BU_:  Airbag BAP_Tester ICAS1_Gateway ICAS1_KommunikationsServer LE1 LE2 Motor_BEV Schaltbetaetigung

BO_ 333 ACC_18: 32 ICAS1_Gateway
 SG_ ACC_18_CRC  : 0|8@1+ (1.000000,0.000000) [0.000000|255.000000] "" Motor_BEV
 SG_ ACC_18_BZ  : 8|4@1+ (1.000000,0.000000) [0.000000|15.000000] "" Motor_BEV
 SG_ ACC_limitierte_Anfahrdyn  : 12|1@1+ (1.000000,0.000000) [0.000000|1.000000] "" Motor_BEV
 SG_ ACC_nachtr_Stopp_Anf  : 13|1@1+ (1.000000,0.000000) [0.000000|1.000000] "" Vector__XXX
 SG_ ACC_DynErhoehung  : 14|1@1+ (1.000000,0.000000) [0.000000|1.000000] "" Motor_BEV
 SG_ ACC_Freilaufstrategie_TSK  : 15|1@1+ (1.000000,0.000000) [0.000000|1.000000] "" Motor_BEV
 SG_ ACC_zul_Regelabw_unten  : 16|6@1+ (0.024000,0.000000) [0.000000|1.512000] "Unit_MeterPerSeconSquar" Motor_BEV
 SG_ ACC_StartStopp_Info  : 22|2@1+ (1.000000,0.000000) [0.000000|3.000000] "" Vector__XXX
 SG_ ACC_Sollbeschleunigung_02  : 24|11@1+ (0.005000,-7.220000) [-7.220000|3.005000] "Unit_MeterPerSeconSquar" Motor_BEV
 SG_ ACC_zul_Regelabw_oben  : 35|5@1+ (0.062500,0.000000) [0.000000|1.937500] "Unit_MeterPerSeconSquar" Motor_BEV
 SG_ ACC_neg_Sollbeschl_Grad_02  : 40|8@1+ (0.050000,0.000000) [0.000000|12.750000] "Unit_MeterPerCubicSecon" Motor_BEV
 SG_ ACC_pos_Sollbeschl_Grad_02  : 48|8@1+ (0.050000,0.000000) [0.000000|12.750000] "Unit_MeterPerCubicSecon" Motor_BEV
 SG_ ACC_Anfahren  : 56|1@1+ (1.000000,0.000000) [0.000000|1.000000] "" Motor_BEV
 SG_ ACC_Anhalten  : 57|1@1+ (1.000000,0.000000) [0.000000|1.000000] "" Motor_BEV
 SG_ ACC_Typ  : 58|2@1+ (1.000000,0.000000) [0.000000|3.000000] "" Motor_BEV
 SG_ ACC_Status_ACC  : 60|3@1+ (1.000000,0.000000) [0.000000|7.000000] "" Motor_BEV
 SG_ ACC_Minimale_Bremsung  : 63|1@1+ (1.000000,0.000000) [0.000000|1.000000] "" Motor_BEV
 SG_ ACC_Anhalteweg  : 64|11@1+ (0.010000,0.000000) [0.000000|20.450000] "Unit_Meter" Vector__XXX
 SG_ ACC_Boost  : 75|1@1+ (1.000000,0.000000) [0.000000|1.000000] "" Vector__XXX
 SG_ ACC_Freilauf_Anf  : 76|1@1+ (1.000000,0.000000) [0.000000|1.000000] "" Vector__XXX
 SG_ ACC_Anforderung_HMS  : 77|3@1+ (1.000000,0.000000) [0.000000|7.000000] "" Vector__XXX
 SG_ ACC_Folgebeschl  : 80|8@1+ (0.030000,-4.600000) [-4.600000|2.990000] "Unit_MeterPerSeconSquar" Motor_BEV
 SG_ ACC_Freilauf_Info  : 88|2@1+ (1.000000,0.000000) [0.000000|3.000000] "" Motor_BEV
 SG_ ACC_Tempolimitassistent_Ein  : 90|1@1+ (1.000000,0.000000) [0.000000|1.000000] "" Vector__XXX
 SG_ ACC_FoD_Status  : 91|2@1+ (1.000000,0.000000) [0.000000|3.000000] "" Motor_BEV
 SG_ vESC_Verz_Anf  : 232|4@1+ (0.500000,0.000000) [0.000000|3.500000] "Unit_MeterPerSeconSquar" Vector__XXX
 SG_ RDR_v_ueber_Grund  : 236|12@1+ (0.100000,0.000000) [0.000000|409.000000] "Unit_KiloMeterPerHour" Vector__XXX
 SG_ RDR_v_ueber_Grund_Genauigkeit  : 248|6@1+ (0.100000,0.000000) [0.000000|6.000000] "Unit_KiloMeterPerHour" Vector__XXX
 SG_ RDR_v_ueber_Grund_Fahrtrichtung  : 254|2@1+ (1.000000,0.000000) [0.000000|3.000000] "" Vector__XXX

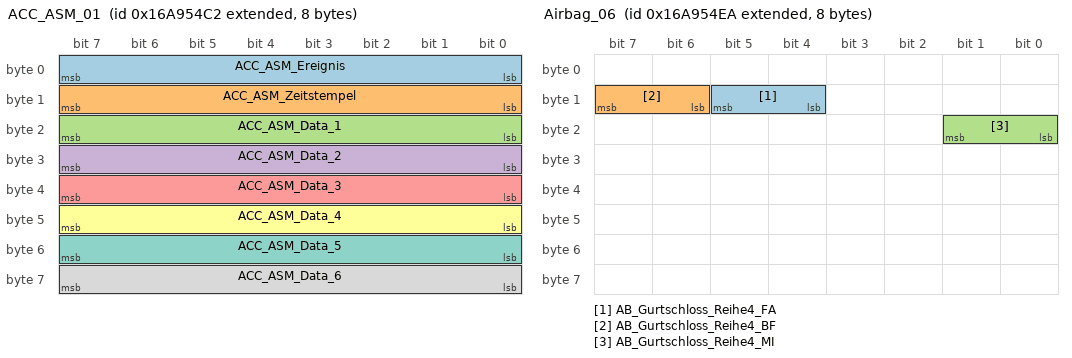
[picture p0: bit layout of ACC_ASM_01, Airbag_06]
BO_ 2527679682 ACC_ASM_01: 8 ICAS1_Gateway
 SG_ ACC_ASM_Ereignis  : 0|8@1+ (1.000000,0.000000) [1.000000|254.000000] "" Airbag
 SG_ ACC_ASM_Zeitstempel  : 8|8@1+ (0.080000,0.000000) [0.000000|20.320000] "Unit_Secon" Airbag
 SG_ ACC_ASM_Data_1  : 16|8@1+ (1.000000,0.000000) [0.000000|255.000000] "" Airbag
 SG_ ACC_ASM_Data_2  : 24|8@1+ (1.000000,0.000000) [0.000000|255.000000] "" Airbag
 SG_ ACC_ASM_Data_3  : 32|8@1+ (1.000000,0.000000) [0.000000|255.000000] "" Airbag
 SG_ ACC_ASM_Data_4  : 40|8@1+ (1.000000,0.000000) [0.000000|255.000000] "" Airbag
 SG_ ACC_ASM_Data_5  : 48|8@1+ (1.000000,0.000000) [0.000000|255.000000] "" Airbag
 SG_ ACC_ASM_Data_6  : 56|8@1+ (1.000000,0.000000) [0.000000|255.000000] "" Airbag

BO_ 64 Airbag_01: 8 Airbag
 SG_ Airbag_01_CRC  : 0|8@1+ (1.000000,0.000000) [0.000000|255.000000] "" ICAS1_Gateway LE1 LE2 Motor_BEV
 SG_ Airbag_01_BZ  : 8|4@1+ (1.000000,0.000000) [0.000000|15.000000] "" ICAS1_Gateway LE1 LE2 Motor_BEV
 SG_ AB_RGS_Anst  : 12|4@1+ (1.000000,0.000000) [0.000000|15.000000] "" ICAS1_Gateway ICAS1_KommunikationsServer
 SG_ AB_Front_Crash  : 16|1@1+ (1.000000,0.000000) [0.000000|1.000000] "" ICAS1_Gateway
 SG_ AB_Heck_Crash  : 17|1@1+ (1.000000,0.000000) [0.000000|1.000000] "" ICAS1_Gateway
 SG_ AB_SF_Crash  : 18|1@1+ (1.000000,0.000000) [0.000000|1.000000] "" ICAS1_Gateway
 SG_ AB_SB_Crash  : 19|1@1+ (1.000000,0.000000) [0.000000|1.000000] "" ICAS1_Gateway
 SG_ AB_Rollover_Crash  : 20|1@1+ (1.000000,0.000000) [0.000000|1.000000] "" ICAS1_Gateway
 SG_ AB_Crash_Int  : 21|3@1+ (1.000000,0.000000) [0.000000|7.000000] "" ICAS1_Gateway ICAS1_KommunikationsServer Motor_BEV
 SG_ AB_Lampe  : 24|1@1+ (1.000000,0.000000) [0.000000|1.000000] "" ICAS1_Gateway ICAS1_KommunikationsServer
 SG_ AB_Deaktiviert  : 25|1@1+ (1.000000,0.000000) [0.000000|1.000000] "" ICAS1_Gateway
 SG_ AB_VB_deaktiviert  : 26|1@1+ (1.000000,0.000000) [0.000000|1.000000] "" ICAS1_Gateway
 SG_ AB_Systemfehler  : 27|1@1+ (1.000000,0.000000) [0.000000|1.000000] "" ICAS1_Gateway ICAS1_KommunikationsServer
 SG_ AB_Diagnose  : 28|1@1+ (1.000000,0.000000) [0.000000|1.000000] "" ICAS1_Gateway
 SG_ AB_Stellgliedtest  : 29|1@1+ (1.000000,0.000000) [0.000000|1.000000] "" ICAS1_Gateway
 SG_ AB_Erh_Auf_VB  : 30|2@1+ (1.000000,0.000000) [0.000000|3.000000] "" ICAS1_Gateway
 SG_ AB_Gurtwarn_VF  : 32|1@1+ (1.000000,0.000000) [0.000000|1.000000] "" ICAS1_Gateway ICAS1_KommunikationsServer
 SG_ AB_Gurtwarn_VB  : 33|1@1+ (1.000000,0.000000) [0.000000|1.000000] "" ICAS1_Gateway ICAS1_KommunikationsServer
 SG_ AB_Anzeige_Fussg  : 34|2@1+ (1.000000,0.000000) [0.000000|3.000000] "" ICAS1_Gateway
 SG_ AB_Texte_AKS  : 36|2@1+ (1.000000,0.000000) [0.000000|3.000000] "" ICAS1_Gateway
 SG_ AB_PAO_Leuchte_Anf  : 38|1@1+ (1.000000,0.000000) [0.000000|1.000000] "" ICAS1_Gateway
 SG_ AB_MKB_gueltig  : 39|1@1+ (1.000000,0.000000) [0.000000|1.000000] "" ICAS1_Gateway
 SG_ AB_MKB_Anforderung  : 40|1@1+ (1.000000,0.000000) [0.000000|1.000000] "" ICAS1_Gateway
 SG_ AB_Versorgungsspannung  : 41|1@1+ (1.000000,0.000000) [0.000000|1.000000] "" ICAS1_Gateway
 SG_ AB_Deaktivierung_HV  : 42|3@1+ (1.000000,0.000000) [0.000000|7.000000] "" ICAS1_Gateway ICAS1_KommunikationsServer LE1 LE2 Motor_BEV
 SG_ AB_EDR_Trigger  : 45|2@1+ (1.000000,0.000000) [0.000000|3.000000] "" ICAS1_Gateway
 SG_ AB_Belegung_VF  : 47|2@1+ (1.000000,0.000000) [0.000000|3.000000] "" ICAS1_Gateway
 SG_ AB_Gurtschloss_FA_ext  : 49|3@1+ (1.000000,0.000000) [0.000000|7.000000] "" ICAS1_Gateway
 SG_ AB_Belegung_VF_ext  : 52|3@1+ (1.000000,0.000000) [0.000000|7.000000] "" ICAS1_Gateway
 SG_ ASM_Masterzeit  : 56|8@1+ (0.080000,0.000000) [0.000000|20.320000] "Unit_Secon" ICAS1_Gateway

BO_ 1312 Airbag_02: 8 Airbag
 SG_ Airbag_02_CRC  : 0|8@1+ (1.000000,0.000000) [0.000000|255.000000] "" ICAS1_Gateway Motor_BEV
 SG_ Airbag_02_BZ  : 8|4@1+ (1.000000,0.000000) [0.000000|15.000000] "" ICAS1_Gateway Motor_BEV
 SG_ LoGeWa_Event_Kombiwarnung  : 12|4@1+ (1.000000,0.000000) [0.000000|15.000000] "" ICAS1_Gateway
 SG_ AB_Anforderung_eCall  : 16|1@1+ (1.000000,0.000000) [0.000000|1.000000] "" ICAS1_Gateway
 SG_ AB_Anprall_Seite_Beifahrer  : 17|1@1+ (1.000000,0.000000) [0.000000|1.000000] "" ICAS1_Gateway ICAS1_KommunikationsServer
 SG_ AB_Anprall_Rollover  : 18|1@1+ (1.000000,0.000000) [0.000000|1.000000] "" ICAS1_Gateway ICAS1_KommunikationsServer
 SG_ AB_Anprall_FGS  : 19|1@1+ (1.000000,0.000000) [0.000000|1.000000] "" ICAS1_Gateway ICAS1_KommunikationsServer
 SG_ AB_Anprall_Front_Beifahrer  : 20|1@1+ (1.000000,0.000000) [0.000000|1.000000] "" ICAS1_Gateway ICAS1_KommunikationsServer
 SG_ AB_Anprall_Front_Fahrer  : 21|1@1+ (1.000000,0.000000) [0.000000|1.000000] "" ICAS1_Gateway ICAS1_KommunikationsServer
 SG_ AB_Anprall_Heck_Beifahrer  : 22|1@1+ (1.000000,0.000000) [0.000000|1.000000] "" ICAS1_Gateway ICAS1_KommunikationsServer
 SG_ AB_Anprall_Heck_Fahrer  : 23|1@1+ (1.000000,0.000000) [0.000000|1.000000] "" ICAS1_Gateway ICAS1_KommunikationsServer
 SG_ AB_Wickelklappung_Reihe2_MI  : 24|2@1+ (1.000000,0.000000) [0.000000|3.000000] "" ICAS1_Gateway
 SG_ AB_Belegung_VB  : 26|2@1+ (1.000000,0.000000) [0.000000|3.000000] "" ICAS1_Gateway
 SG_ AB_Abschaltanf_SIH_BF  : 28|1@1+ (1.000000,0.000000) [0.000000|1.000000] "" ICAS1_Gateway
 SG_ AB_Anprall_Seite_Fahrer  : 29|1@1+ (1.000000,0.000000) [0.000000|1.000000] "" ICAS1_Gateway ICAS1_KommunikationsServer
 SG_ SC_PAO_Schriftzug_Anf  : 30|2@1+ (1.000000,0.000000) [0.000000|3.000000] "" ICAS1_Gateway
 SG_ SC_PAO_ON_Anf  : 32|2@1+ (1.000000,0.000000) [0.000000|3.000000] "" ICAS1_Gateway
 SG_ SC_PAO_OFF_Anf  : 34|2@1+ (1.000000,0.000000) [0.000000|3.000000] "" ICAS1_Gateway
 SG_ AB_Crashschwere  : 36|3@1+ (1.000000,0.000000) [0.000000|7.000000] "" ICAS1_Gateway ICAS1_KommunikationsServer
 SG_ AB_Anforderung_USM  : 39|1@1+ (1.000000,0.000000) [0.000000|1.000000] "" ICAS1_Gateway
 SG_ AB_Gurtschloss_FA  : 40|2@1+ (1.000000,0.000000) [0.000000|3.000000] "" ICAS1_Gateway ICAS1_KommunikationsServer Motor_BEV
 SG_ AB_Gurtschloss_BF  : 42|2@1+ (1.000000,0.000000) [0.000000|3.000000] "" ICAS1_Gateway ICAS1_KommunikationsServer
 SG_ AB_Gurtschloss_Reihe2_FA  : 44|2@1+ (1.000000,0.000000) [0.000000|3.000000] "" ICAS1_Gateway ICAS1_KommunikationsServer
 SG_ AB_Gurtschloss_Reihe2_MI  : 46|2@1+ (1.000000,0.000000) [0.000000|3.000000] "" ICAS1_Gateway ICAS1_KommunikationsServer
 SG_ AB_Gurtschloss_Reihe2_BF  : 48|2@1+ (1.000000,0.000000) [0.000000|3.000000] "" ICAS1_Gateway ICAS1_KommunikationsServer
 SG_ AB_Gurtschloss_Reihe3_FA  : 50|2@1+ (1.000000,0.000000) [0.000000|3.000000] "" ICAS1_Gateway ICAS1_KommunikationsServer
 SG_ AB_Gurtschloss_Reihe3_MI  : 52|2@1+ (1.000000,0.000000) [0.000000|3.000000] "" ICAS1_Gateway ICAS1_KommunikationsServer
 SG_ AB_Gurtschloss_Reihe3_BF  : 54|2@1+ (1.000000,0.000000) [0.000000|3.000000] "" ICAS1_Gateway ICAS1_KommunikationsServer
 SG_ AB_Sitzpos_Sens_FA  : 56|2@1+ (1.000000,0.000000) [0.000000|3.000000] "" ICAS1_Gateway
 SG_ AB_Sitzpos_Sens_BF  : 58|2@1+ (1.000000,0.000000) [0.000000|3.000000] "" ICAS1_Gateway
 SG_ AB_Wickelklappung_Reihe2_BF  : 60|2@1+ (1.000000,0.000000) [0.000000|3.000000] "" ICAS1_Gateway
 SG_ AB_Wickelklappung_Reihe2_FA  : 62|2@1+ (1.000000,0.000000) [0.000000|3.000000] "" ICAS1_Gateway

BO_ 65 Airbag_03: 8 Airbag
 SG_ Airbag_03_CRC  : 0|8@1+ (1.000000,0.000000) [0.000000|255.000000] "" ICAS1_Gateway
 SG_ Airbag_03_BZ  : 8|4@1+ (1.000000,0.000000) [0.000000|15.000000] "" ICAS1_Gateway
 SG_ AB_MKB_Safing  : 63|1@1+ (1.000000,0.000000) [0.000000|1.000000] "" ICAS1_Gateway

BO_ 1349 Airbag_04: 8 Airbag
 SG_ AB_Gurtwarn_Reihe4_FA  : 14|2@1+ (1.000000,0.000000) [0.000000|3.000000] "" ICAS1_Gateway ICAS1_KommunikationsServer
 SG_ AB_Gurtwarn_Reihe4_BF  : 16|2@1+ (1.000000,0.000000) [0.000000|3.000000] "" ICAS1_Gateway ICAS1_KommunikationsServer
 SG_ AB_Gurtwarn_Reihe4_MI  : 18|2@1+ (1.000000,0.000000) [0.000000|3.000000] "" ICAS1_Gateway ICAS1_KommunikationsServer
 SG_ AB_Gurtwarn_Reihe2_FA  : 20|2@1+ (1.000000,0.000000) [0.000000|3.000000] "" ICAS1_Gateway ICAS1_KommunikationsServer
 SG_ AB_Gurtwarn_Reihe2_BF  : 22|2@1+ (1.000000,0.000000) [0.000000|3.000000] "" ICAS1_Gateway ICAS1_KommunikationsServer
 SG_ AbstWarn_MV_FAS_Fkt_Status  : 24|2@1+ (1.000000,0.000000) [0.000000|3.000000] "" ICAS1_Gateway
 SG_ WarnBrems_Charisma_Status  : 26|2@1+ (1.000000,0.000000) [0.000000|3.000000] "" ICAS1_Gateway
 SG_ WarnBrems_Charisma_FahrPr  : 28|4@1+ (1.000000,0.000000) [0.000000|15.000000] "" ICAS1_Gateway
 SG_ AB_Gurtwarn_Reihe2_MI  : 32|2@1+ (1.000000,0.000000) [0.000000|3.000000] "" ICAS1_Gateway ICAS1_KommunikationsServer
 SG_ AB_Gurtwarn_Reihe3_FA  : 34|2@1+ (1.000000,0.000000) [0.000000|3.000000] "" ICAS1_Gateway ICAS1_KommunikationsServer
 SG_ AB_Gurtwarn_Reihe3_MI  : 36|2@1+ (1.000000,0.000000) [0.000000|3.000000] "" ICAS1_Gateway ICAS1_KommunikationsServer
 SG_ AB_Gurtwarn_Reihe3_BF  : 38|2@1+ (1.000000,0.000000) [0.000000|3.000000] "" ICAS1_Gateway ICAS1_KommunikationsServer
 SG_ LGI_FAS_Fkt_Status  : 40|2@1+ (1.000000,0.000000) [0.000000|3.000000] "" ICAS1_Gateway
 SG_ PreCrash_FAS_Fkt_Status  : 42|3@1+ (1.000000,0.000000) [0.000000|7.000000] "" ICAS1_Gateway
 SG_ AB_SBR_hinten_verbau  : 48|2@1+ (1.000000,0.000000) [0.000000|3.000000] "" ICAS1_Gateway ICAS1_KommunikationsServer
 SG_ AWV_Einstellung_System_ASG  : 51|1@1+ (1.000000,0.000000) [0.000000|1.000000] "" ICAS1_Gateway
 SG_ AWV_Einstellung_Warnung_ASG  : 52|3@1+ (1.000000,0.000000) [0.000000|7.000000] "" ICAS1_Gateway
 SG_ SC_PreSense_Modus_Warnung_NV  : 55|3@1+ (1.000000,0.000000) [0.000000|7.000000] "" ICAS1_Gateway
 SG_ SC_PreSense_Modus_Warnung_MV  : 58|3@1+ (1.000000,0.000000) [0.000000|7.000000] "" ICAS1_Gateway
 SG_ SC_PreSense_Modus_System_MV  : 61|1@1+ (1.000000,0.000000) [0.000000|1.000000] "" ICAS1_Gateway
 SG_ SC_PreSense_Modus_System_NV  : 62|1@1+ (1.000000,0.000000) [0.000000|1.000000] "" ICAS1_Gateway
 SG_ SC_PreSense_Modus_System_KAS  : 63|1@1+ (1.000000,0.000000) [0.000000|1.000000] "" ICAS1_Gateway

BO_ 2527679722 Airbag_06: 8 Airbag
 SG_ AB_Gurtschloss_Reihe4_FA  : 12|2@1+ (1.000000,0.000000) [0.000000|3.000000] "" ICAS1_Gateway ICAS1_KommunikationsServer
 SG_ AB_Gurtschloss_Reihe4_BF  : 14|2@1+ (1.000000,0.000000) [0.000000|3.000000] "" ICAS1_Gateway ICAS1_KommunikationsServer
 SG_ AB_Gurtschloss_Reihe4_MI  : 16|2@1+ (1.000000,0.000000) [0.000000|3.000000] "" ICAS1_Gateway ICAS1_KommunikationsServer

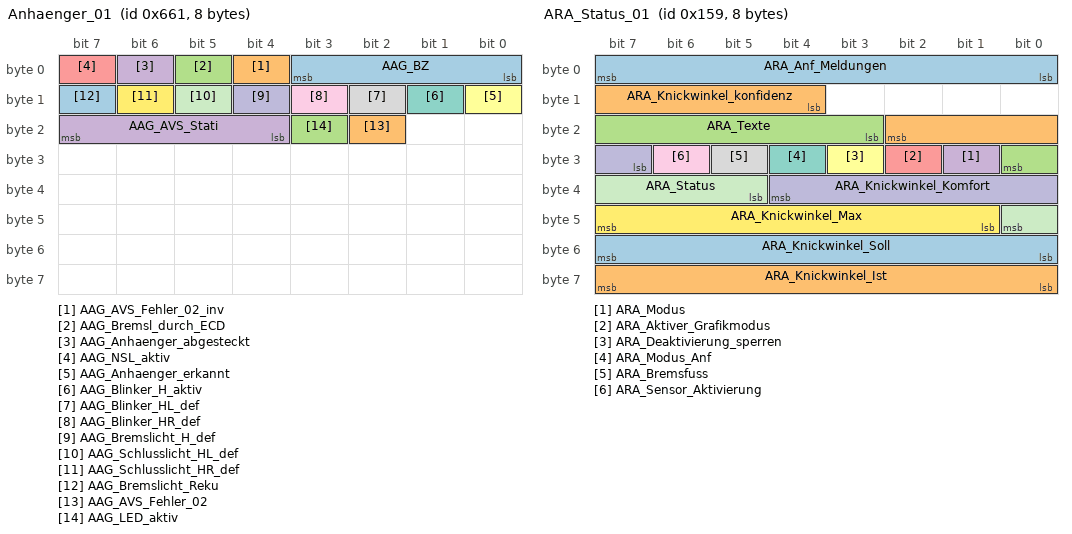
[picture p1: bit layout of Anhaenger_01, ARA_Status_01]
BO_ 1633 Anhaenger_01: 8 ICAS1_Gateway
 SG_ AAG_BZ  : 0|4@1+ (1.000000,0.000000) [0.000000|15.000000] "" Vector__XXX
 SG_ AAG_AVS_Fehler_02_inv  : 4|1@1+ (1.000000,0.000000) [0.000000|1.000000] "" Vector__XXX
 SG_ AAG_Bremsl_durch_ECD  : 5|1@1+ (1.000000,0.000000) [0.000000|1.000000] "" Motor_BEV
 SG_ AAG_Anhaenger_abgesteckt  : 6|1@1+ (1.000000,0.000000) [0.000000|1.000000] "" Motor_BEV
 SG_ AAG_NSL_aktiv  : 7|1@1+ (1.000000,0.000000) [0.000000|1.000000] "" Vector__XXX
 SG_ AAG_Anhaenger_erkannt  : 8|1@1+ (1.000000,0.000000) [0.000000|1.000000] "" Motor_BEV
 SG_ AAG_Blinker_H_aktiv  : 9|1@1+ (1.000000,0.000000) [0.000000|1.000000] "" Vector__XXX
 SG_ AAG_Blinker_HL_def  : 10|1@1+ (1.000000,0.000000) [0.000000|1.000000] "" Vector__XXX
 SG_ AAG_Blinker_HR_def  : 11|1@1+ (1.000000,0.000000) [0.000000|1.000000] "" Vector__XXX
 SG_ AAG_Bremslicht_H_def  : 12|1@1+ (1.000000,0.000000) [0.000000|1.000000] "" Motor_BEV
 SG_ AAG_Schlusslicht_HL_def  : 13|1@1+ (1.000000,0.000000) [0.000000|1.000000] "" Vector__XXX
 SG_ AAG_Schlusslicht_HR_def  : 14|1@1+ (1.000000,0.000000) [0.000000|1.000000] "" Vector__XXX
 SG_ AAG_Bremslicht_Reku  : 15|1@1+ (1.000000,0.000000) [0.000000|1.000000] "" Vector__XXX
 SG_ AAG_AVS_Fehler_02  : 18|1@1+ (1.000000,0.000000) [0.000000|1.000000] "" Vector__XXX
 SG_ AAG_LED_aktiv  : 19|1@1+ (1.000000,0.000000) [0.000000|1.000000] "" Vector__XXX
 SG_ AAG_AVS_Stati  : 20|4@1+ (1.000000,0.000000) [0.000000|15.000000] "" Vector__XXX

BO_ 345 ARA_Status_01: 8 ICAS1_Gateway
 SG_ ARA_Anf_Meldungen  : 0|8@1+ (1.000000,0.000000) [0.000000|255.000000] "" Vector__XXX
 SG_ ARA_Knickwinkel_konfidenz  : 12|7@1+ (1.000000,0.000000) [0.000000|120.000000] "Unit_DegreOfArc" Vector__XXX
 SG_ ARA_Texte  : 19|6@1+ (1.000000,0.000000) [0.000000|63.000000] "" Vector__XXX
 SG_ ARA_Modus  : 25|1@1+ (1.000000,0.000000) [0.000000|1.000000] "" Vector__XXX
 SG_ ARA_Aktiver_Grafikmodus  : 26|1@1+ (1.000000,0.000000) [0.000000|1.000000] "" Vector__XXX
 SG_ ARA_Deaktivierung_sperren  : 27|1@1+ (1.000000,0.000000) [0.000000|1.000000] "" Vector__XXX
 SG_ ARA_Modus_Anf  : 28|1@1+ (1.000000,0.000000) [0.000000|1.000000] "" Vector__XXX
 SG_ ARA_Bremsfuss  : 29|1@1+ (1.000000,0.000000) [0.000000|1.000000] "" Vector__XXX
 SG_ ARA_Sensor_Aktivierung  : 30|1@1+ (1.000000,0.000000) [0.000000|1.000000] "" Vector__XXX
 SG_ ARA_Knickwinkel_Komfort  : 31|6@1+ (1.000000,0.000000) [0.000000|60.000000] "Unit_DegreOfArc" Vector__XXX
 SG_ ARA_Status  : 37|4@1+ (1.000000,0.000000) [0.000000|15.000000] "" Motor_BEV
 SG_ ARA_Knickwinkel_Max  : 41|7@1+ (1.000000,0.000000) [0.000000|120.000000] "Unit_DegreOfArc" Vector__XXX
 SG_ ARA_Knickwinkel_Soll  : 48|8@1+ (1.000000,-125.000000) [-125.000000|126.000000] "Unit_DegreOfArc" Vector__XXX
 SG_ ARA_Knickwinkel_Ist  : 56|8@1+ (1.000000,-125.000000) [-125.000000|126.000000] "Unit_DegreOfArc" Vector__XXX

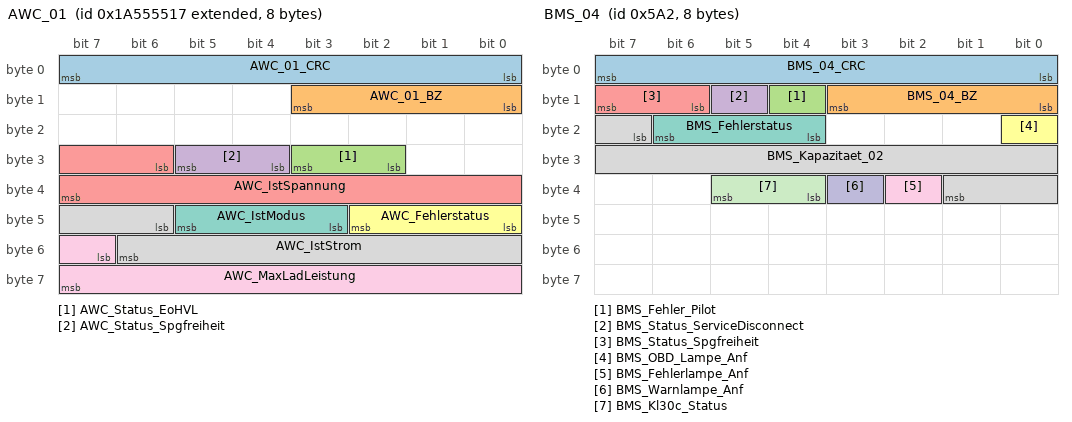
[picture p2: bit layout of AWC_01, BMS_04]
BO_ 2589283607 AWC_01: 8 ICAS1_Gateway
 SG_ AWC_01_CRC  : 0|8@1+ (1.000000,0.000000) [0.000000|255.000000] "" Vector__XXX
 SG_ AWC_01_BZ  : 8|4@1+ (1.000000,0.000000) [0.000000|15.000000] "" Vector__XXX
 SG_ AWC_Status_EoHVL  : 26|2@1+ (1.000000,0.000000) [0.000000|3.000000] "" Motor_BEV
 SG_ AWC_Status_Spgfreiheit  : 28|2@1+ (1.000000,0.000000) [0.000000|3.000000] "" Vector__XXX
 SG_ AWC_IstSpannung  : 30|10@1+ (1.000000,0.000000) [0.000000|1021.000000] "Unit_Volt" Vector__XXX
 SG_ AWC_Fehlerstatus  : 40|3@1+ (1.000000,0.000000) [0.000000|7.000000] "" Vector__XXX
 SG_ AWC_IstModus  : 43|3@1+ (1.000000,0.000000) [0.000000|7.000000] "" Vector__XXX
 SG_ AWC_IstStrom  : 46|9@1+ (0.100000,0.000000) [0.000000|50.900000] "Unit_Amper" Vector__XXX
 SG_ AWC_MaxLadLeistung  : 55|9@1+ (25.000000,0.000000) [0.000000|12725.000000] "Unit_Watt" Vector__XXX

BO_ 219 AWV_03: 48 ICAS1_Gateway
 SG_ AWV_03_CRC  : 0|8@1+ (1.000000,0.000000) [0.000000|255.000000] "" Airbag
 SG_ AWV_03_BZ  : 8|4@1+ (1.000000,0.000000) [0.000000|15.000000] "" Airbag
 SG_ PCF_Freigabe  : 12|1@1+ (1.000000,0.000000) [0.000000|1.000000] "" Airbag
 SG_ SDF_PSF_Objektstatus  : 13|3@1+ (1.000000,0.000000) [0.000000|7.000000] "" Airbag
 SG_ SDF_PSF_CU_Status  : 16|1@1+ (1.000000,0.000000) [0.000000|1.000000] "" Airbag
 SG_ SDF_PSF_CW  : 17|7@1+ (1.000000,0.000000) [0.000000|100.000000] "" Airbag
 SG_ SDF_PSF_Fahrer_aktiv  : 24|1@1+ (1.000000,0.000000) [0.000000|1.000000] "" Airbag
 SG_ SDF_PSF_Guete  : 25|2@1+ (1.000000,0.000000) [0.000000|3.000000] "" Airbag
 SG_ SDF_PSF_Kollisionsueberdeckung  : 27|5@1+ (0.100000,0.000000) [0.100000|2.800000] "Unit_Meter" Airbag
 SG_ SDF_PSF_Time_To_Collision  : 32|8@1+ (0.010000,0.000000) [0.000000|2.500000] "Unit_Secon" Vector__XXX
 SG_ SDF_PSF_v_rel  : 40|8@1+ (0.400000,0.000000) [0.400000|101.200000] "Unit_MeterPerSecon" Airbag
 SG_ AWV_Eingriff_Sendeart  : 64|1@1+ (1.000000,0.000000) [0.000000|1.000000] "" Airbag
 SG_ AWV_Verz_Freigabe  : 65|1@1+ (1.000000,0.000000) [0.000000|1.000000] "" Airbag
 SG_ AWV_Verz_Anf  : 66|10@1+ (0.024000,-20.016000) [-20.016000|4.512000] "Unit_MeterPerSeconSquar" Airbag
 SG_ AWV_Anf_Prefill  : 76|1@1+ (1.000000,0.000000) [0.000000|1.000000] "" Airbag
 SG_ AWV_Ruckprofil  : 77|3@1+ (1.000000,0.000000) [0.000000|7.000000] "" Vector__XXX
 SG_ AWV_Time_to_collision  : 80|8@1+ (0.010000,0.000000) [0.000000|2.500000] "Unit_Secon" Airbag
 SG_ AWV_HBA_Param  : 88|2@1+ (1.000000,0.000000) [0.000000|3.000000] "" Vector__XXX
 SG_ AWV_Verz_Anf_ASIL  : 90|3@1+ (1.000000,0.000000) [0.000000|7.000000] "" Vector__XXX
 SG_ AWV_Time_to_brake  : 93|7@1+ (10.000000,0.000000) [0.000000|1240.000000] "Unit_MilliSecon" Vector__XXX
 SG_ AWV_Zielobjekttyp  : 100|4@1+ (1.000000,0.000000) [0.000000|15.000000] "" Airbag
 SG_ AWV_QFK_KruemmSoll  : 104|15@1+ (0.000007,0.000000) [0.000000|0.219539] "Unit_MeterInver" Vector__XXX
 SG_ AWV_QFK_KruemmSoll_VZ  : 119|1@1+ (1.000000,0.000000) [0.000000|1.000000] "" Vector__XXX
 SG_ AWV_QFK_Spuerb  : 120|8@1+ (0.400000,0.000000) [0.000000|100.000000] "Unit_PerCent" Vector__XXX
 SG_ AWV_QFK_AnfStat  : 128|4@1+ (1.000000,0.000000) [0.000000|15.000000] "" Airbag
 SG_ AWV_QFK_Signal1  : 132|10@1+ (1.000000,0.000000) [0.000000|1023.000000] "" Vector__XXX
 SG_ AWV_QFK_Art1  : 142|3@1+ (1.000000,0.000000) [0.000000|7.000000] "" Vector__XXX
 SG_ AWV_QFK_Art2  : 145|3@1+ (1.000000,0.000000) [0.000000|7.000000] "" Vector__XXX
 SG_ AWV_QFK_Signal2  : 148|10@1+ (1.000000,0.000000) [0.000000|1023.000000] "" Vector__XXX

BO_ 2536767264 BAP_Debug_Cmd: 8 BAP_Tester
 SG_ BAP_Debug_Cmd  : 0|16@1+ (1.000000,0.000000) [0.000000|65535.000000] "" Motor_BEV

BO_ 2536767280 BAP_Debug_Data: 8 Motor_BEV
 SG_ BAP_Debug_Data  : 0|64@1+ (1.000000,0.000000) [0.000000|18446744073709551616.000000] "" BAP_Tester

BO_ 2536717313 BAP_EfficiencyAssist_ASG_02: 8 ICAS1_Gateway
 SG_ BAP_EfficAssist_ASG_02_Header  : 0|64@1+ (1.000000,0.000000) [0.000000|18446744073709551616.000000] "" Motor_BEV

BO_ 2536717314 BAP_EfficiencyAssist_ASG_03: 8 ICAS1_Gateway
 SG_ BAP_EfficAssist_ASG_03_Header  : 0|8@1+ (1.000000,0.000000) [0.000000|255.000000] "" Motor_BEV

BO_ 2536717328 BAP_EfficiencyAssist_FSG_01: 8 Motor_BEV
 SG_ BAP_EfficAssist_FSG_01_Header  : 0|8@1+ (1.000000,0.000000) [0.000000|255.000000] "" ICAS1_Gateway

BO_ 2536709120 BAP_Hybrid_ASG_01: 8 ICAS1_Gateway
 SG_ BAP_Hybrid_ASG_01_Header  : 0|8@1+ (1.000000,0.000000) [0.000000|255.000000] "" Motor_BEV

BO_ 2536709136 BAP_Hybrid_FSG_01: 8 Motor_BEV
 SG_ BAP_Hybrid_FSG_01_Header  : 0|8@1+ (1.000000,0.000000) [0.000000|255.000000] "" ICAS1_Gateway

BO_ 869 BEM_05: 8 ICAS1_Gateway
 SG_ BEM_UBDM  : 0|8@1+ (0.050000,5.000000) [5.050000|17.700000] "Unit_Volt" Vector__XXX
 SG_ NVEM_Ladefreigabe  : 8|2@1+ (1.000000,0.000000) [0.000000|3.000000] "" Vector__XXX
 SG_ NVEM_FMAus_Info  : 10|2@1+ (1.000000,0.000000) [0.000000|3.000000] "" Vector__XXX
 SG_ NVEM_PTC_Sollstufe  : 12|2@1+ (1.000000,0.000000) [0.000000|3.000000] "" Vector__XXX
 SG_ NVEM_P_Generator_Status  : 15|1@1+ (1.000000,0.000000) [0.000000|1.000000] "" Vector__XXX
 SG_ BEM_P_Generator  : 16|8@1+ (50.000000,0.000000) [0.000000|12700.000000] "Unit_Watt" Vector__XXX
 SG_ BEM_n_LLA  : 24|2@1+ (1.000000,0.000000) [0.000000|3.000000] "" Vector__XXX
 SG_ BEM_01_Abschaltstufen  : 26|3@1+ (1.000000,0.000000) [0.000000|7.000000] "" Vector__XXX
 SG_ BEM_Anf_KL  : 29|1@1+ (1.000000,0.000000) [0.000000|1.000000] "" Vector__XXX
 SG_ BEM_StartStopp_Info  : 30|2@1+ (1.000000,0.000000) [0.000000|3.000000] "" Vector__XXX
 SG_ BEM_DFM  : 32|5@1+ (3.225000,0.025000) [0.025000|100.000000] "" Vector__XXX
 SG_ BEM_EMLIN_ungueltig  : 37|1@1+ (1.000000,0.000000) [0.000000|1.000000] "" Vector__XXX
 SG_ BEM_Batt_Ab  : 38|1@1+ (1.000000,0.000000) [0.000000|1.000000] "" Motor_BEV
 SG_ NVEM_FMAus_I_Verbrauch  : 39|5@1+ (5.000000,0.000000) [0.000000|145.000000] "Unit_Amper" Vector__XXX
 SG_ NVEM_Freilauf_Info  : 44|2@1+ (1.000000,0.000000) [0.000000|3.000000] "" Vector__XXX
 SG_ BEM_NV_NachladAnf  : 46|2@1+ (1.000000,0.000000) [0.000000|3.000000] "" Vector__XXX
 SG_ BEM_Segel_Info  : 48|2@1+ (1.000000,0.000000) [0.000000|3.000000] "" Vector__XXX
 SG_ BEM_HYB_DC_uSollLV  : 50|6@1+ (0.100000,10.600000) [10.600000|16.000000] "Unit_Volt" Vector__XXX
 SG_ BEM_HYB_DC_uMinLV  : 56|8@1+ (0.100000,0.000000) [0.000000|25.300000] "Unit_Volt" Vector__XXX

BO_ 1442 BMS_04: 8 ICAS1_Gateway
 SG_ BMS_04_CRC  : 0|8@1+ (1.000000,0.000000) [0.000000|255.000000] "" Vector__XXX
 SG_ BMS_04_BZ  : 8|4@1+ (1.000000,0.000000) [0.000000|15.000000] "" Vector__XXX
 SG_ BMS_Fehler_Pilot  : 12|1@1+ (1.000000,0.000000) [0.000000|1.000000] "" Vector__XXX
 SG_ BMS_Status_ServiceDisconnect  : 13|1@1+ (1.000000,0.000000) [0.000000|1.000000] "" Vector__XXX
 SG_ BMS_Status_Spgfreiheit  : 14|2@1+ (1.000000,0.000000) [0.000000|3.000000] "" Motor_BEV
 SG_ BMS_OBD_Lampe_Anf  : 16|1@1+ (1.000000,0.000000) [0.000000|1.000000] "" Motor_BEV
 SG_ BMS_Fehlerstatus  : 20|3@1+ (1.000000,0.000000) [0.000000|7.000000] "" Vector__XXX
 SG_ BMS_Kapazitaet_02  : 23|11@1+ (0.200000,0.000000) [0.000000|409.200000] "Unit_AmperHour" Vector__XXX
 SG_ BMS_Fehlerlampe_Anf  : 34|1@1+ (1.000000,0.000000) [0.000000|1.000000] "" Motor_BEV
 SG_ BMS_Warnlampe_Anf  : 35|1@1+ (1.000000,0.000000) [0.000000|1.000000] "" Motor_BEV
 SG_ BMS_Kl30c_Status  : 36|2@1+ (1.000000,0.000000) [0.000000|3.000000] "" Motor_BEV

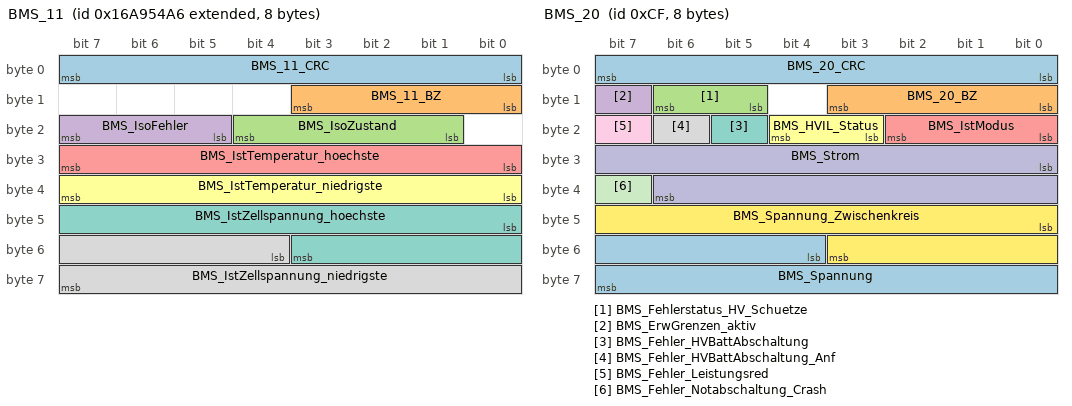
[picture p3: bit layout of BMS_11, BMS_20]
BO_ 2527679654 BMS_11: 8 ICAS1_Gateway
 SG_ BMS_11_CRC  : 0|8@1+ (1.000000,0.000000) [0.000000|255.000000] "" Motor_BEV
 SG_ BMS_11_BZ  : 8|4@1+ (1.000000,0.000000) [0.000000|15.000000] "" Motor_BEV
 SG_ BMS_IsoZustand  : 17|4@1+ (1.000000,0.000000) [0.000000|15.000000] "" Motor_BEV
 SG_ BMS_IsoFehler  : 21|3@1+ (1.000000,0.000000) [0.000000|7.000000] "" Motor_BEV
 SG_ BMS_IstTemperatur_hoechste  : 24|8@1+ (0.500000,-40.000000) [-40.000000|86.000000] "Unit_DegreCelsi" Vector__XXX
 SG_ BMS_IstTemperatur_niedrigste  : 32|8@1+ (0.500000,-40.000000) [-40.000000|86.000000] "Unit_DegreCelsi" Vector__XXX
 SG_ BMS_IstZellspannung_hoechste  : 40|12@1+ (1.000000,1000.000000) [1000.000000|5091.000000] "Unit_MilliVolt" Vector__XXX
 SG_ BMS_IstZellspannung_niedrigste  : 52|12@1+ (1.000000,1000.000000) [1000.000000|5091.000000] "Unit_MilliVolt" Vector__XXX

BO_ 207 BMS_20: 8 ICAS1_Gateway
 SG_ BMS_20_CRC  : 0|8@1+ (1.000000,0.000000) [0.000000|255.000000] "" Motor_BEV
 SG_ BMS_20_BZ  : 8|4@1+ (1.000000,0.000000) [0.000000|15.000000] "" Motor_BEV
 SG_ BMS_Fehlerstatus_HV_Schuetze  : 13|2@1+ (1.000000,0.000000) [0.000000|3.000000] "" Motor_BEV
 SG_ BMS_ErwGrenzen_aktiv  : 15|1@1+ (1.000000,0.000000) [0.000000|1.000000] "" Motor_BEV
 SG_ BMS_IstModus  : 16|3@1+ (1.000000,0.000000) [0.000000|7.000000] "" LE1 LE2 Motor_BEV
 SG_ BMS_HVIL_Status  : 19|2@1+ (1.000000,0.000000) [0.000000|3.000000] "" Motor_BEV
 SG_ BMS_Fehler_HVBattAbschaltung  : 21|1@1+ (1.000000,0.000000) [0.000000|1.000000] "" Motor_BEV
 SG_ BMS_Fehler_HVBattAbschaltung_Anf  : 22|1@1+ (1.000000,0.000000) [0.000000|1.000000] "" Motor_BEV
 SG_ BMS_Fehler_Leistungsred  : 23|1@1+ (1.000000,0.000000) [0.000000|1.000000] "" Motor_BEV
 SG_ BMS_Strom  : 24|15@1+ (0.100000,-1630.000000) [-1630.000000|1630.000000] "Unit_Amper" Motor_BEV
 SG_ BMS_Fehler_Notabschaltung_Crash  : 39|1@1+ (1.000000,0.000000) [0.000000|1.000000] "" Vector__XXX
 SG_ BMS_Spannung_Zwischenkreis  : 40|12@1+ (0.500000,-1000.000000) [-1000.000000|1000.000000] "Unit_Volt" Motor_BEV
 SG_ BMS_Spannung  : 52|12@1+ (0.250000,0.000000) [0.000000|1000.000000] "Unit_Volt" Motor_BEV

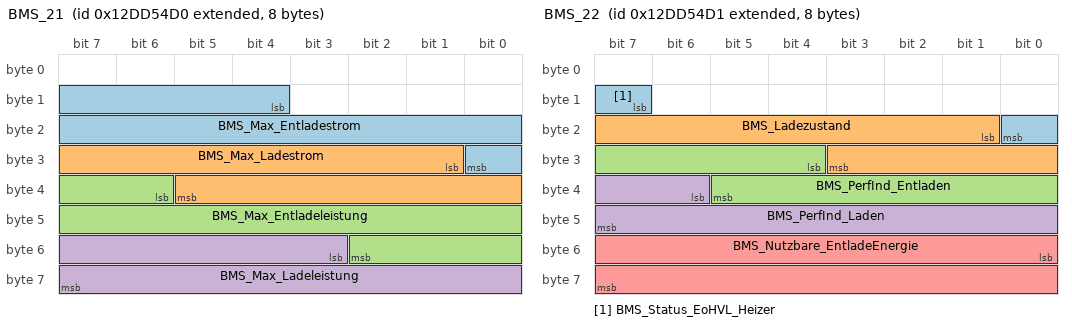
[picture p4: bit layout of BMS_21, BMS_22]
BO_ 2463978704 BMS_21: 8 ICAS1_Gateway
 SG_ BMS_Max_Entladestrom  : 12|13@1+ (0.200000,0.000000) [0.000000|1630.000000] "Unit_Amper" Motor_BEV
 SG_ BMS_Max_Ladestrom  : 25|13@1+ (0.200000,0.000000) [0.000000|1630.000000] "Unit_Amper" Motor_BEV
 SG_ BMS_Max_Entladeleistung  : 38|13@1+ (100.000000,0.000000) [0.000000|818000.000000] "Unit_Watt" Motor_BEV
 SG_ BMS_Max_Ladeleistung  : 51|13@1+ (100.000000,0.000000) [0.000000|818000.000000] "Unit_Watt" Motor_BEV

BO_ 2463978705 BMS_22: 8 ICAS1_Gateway
 SG_ BMS_Status_EoHVL_Heizer  : 15|2@1+ (1.000000,0.000000) [0.000000|3.000000] "" Motor_BEV
 SG_ BMS_Ladezustand  : 17|11@1+ (0.050000,0.000000) [0.000000|100.000000] "Unit_PerCent" Motor_BEV
 SG_ BMS_PerfInd_Entladen  : 28|10@1+ (0.200000,0.000000) [0.000000|200.000000] "Unit_PerCent" Motor_BEV
 SG_ BMS_PerfInd_Laden  : 38|10@1+ (0.200000,0.000000) [0.000000|200.000000] "Unit_PerCent" Motor_BEV
 SG_ BMS_Nutzbare_EntladeEnergie  : 48|16@1+ (5.000000,0.000000) [0.000000|327400.000000] "Unit_WattHour" Motor_BEV

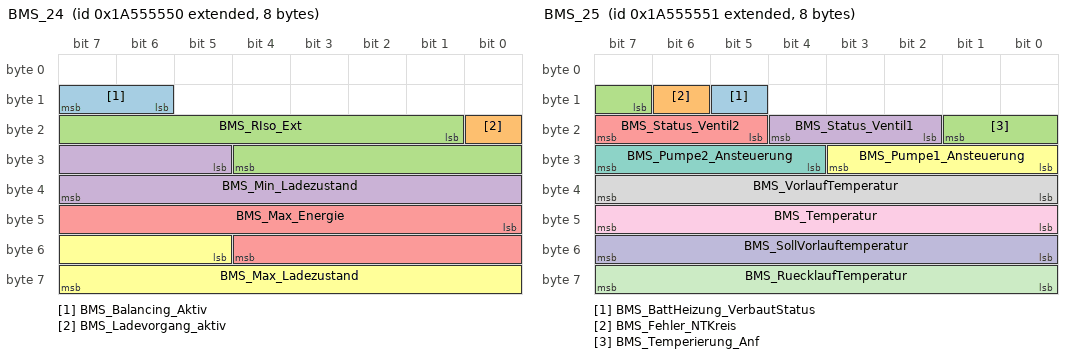
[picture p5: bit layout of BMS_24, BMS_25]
BO_ 2589283664 BMS_24: 8 ICAS1_Gateway
 SG_ BMS_Balancing_Aktiv  : 14|2@1+ (1.000000,0.000000) [0.000000|3.000000] "" Vector__XXX
 SG_ BMS_Ladevorgang_aktiv  : 16|1@1+ (1.000000,0.000000) [0.000000|1.000000] "" Vector__XXX
 SG_ BMS_RIso_Ext  : 17|12@1+ (5.000000,0.000000) [0.000000|20465.000000] "Unit_KiloOhm" Motor_BEV
 SG_ BMS_Min_Ladezustand  : 29|11@1+ (0.050000,0.000000) [0.000000|100.000000] "Unit_PerCent" Motor_BEV
 SG_ BMS_Max_Energie  : 40|13@1+ (40.000000,0.000000) [0.000000|327400.000000] "Unit_WattHour" Motor_BEV
 SG_ BMS_Max_Ladezustand  : 53|11@1+ (0.050000,0.000000) [0.000000|100.000000] "Unit_PerCent" Motor_BEV

BO_ 2589283665 BMS_25: 8 ICAS1_Gateway
 SG_ BMS_BattHeizung_VerbautStatus  : 13|1@1+ (1.000000,0.000000) [0.000000|1.000000] "" Motor_BEV
 SG_ BMS_Fehler_NTKreis  : 14|1@1+ (1.000000,0.000000) [0.000000|1.000000] "" Vector__XXX
 SG_ BMS_Temperierung_Anf  : 15|3@1+ (1.000000,0.000000) [0.000000|7.000000] "" Motor_BEV
 SG_ BMS_Status_Ventil1  : 18|3@1+ (1.000000,0.000000) [0.000000|7.000000] "" Motor_BEV
 SG_ BMS_Status_Ventil2  : 21|3@1+ (1.000000,0.000000) [0.000000|7.000000] "" Motor_BEV
 SG_ BMS_Pumpe1_Ansteuerung  : 24|4@1+ (10.000000,0.000000) [0.000000|100.000000] "Unit_PerCent" Motor_BEV
 SG_ BMS_Pumpe2_Ansteuerung  : 28|4@1+ (10.000000,0.000000) [0.000000|100.000000] "Unit_PerCent" Motor_BEV
 SG_ BMS_VorlaufTemperatur  : 32|8@1+ (0.500000,-40.000000) [-40.000000|86.000000] "Unit_DegreCelsi" Motor_BEV
 SG_ BMS_Temperatur  : 40|8@1+ (0.500000,-40.000000) [-40.000000|86.500000] "Unit_DegreCelsi" Motor_BEV
 SG_ BMS_SollVorlauftemperatur  : 48|8@1+ (0.500000,-40.000000) [-40.000000|86.500000] "Unit_DegreCelsi" Motor_BEV
 SG_ BMS_RuecklaufTemperatur  : 56|8@1+ (0.500000,-40.000000) [-40.000000|86.000000] "Unit_DegreCelsi" Motor_BEV

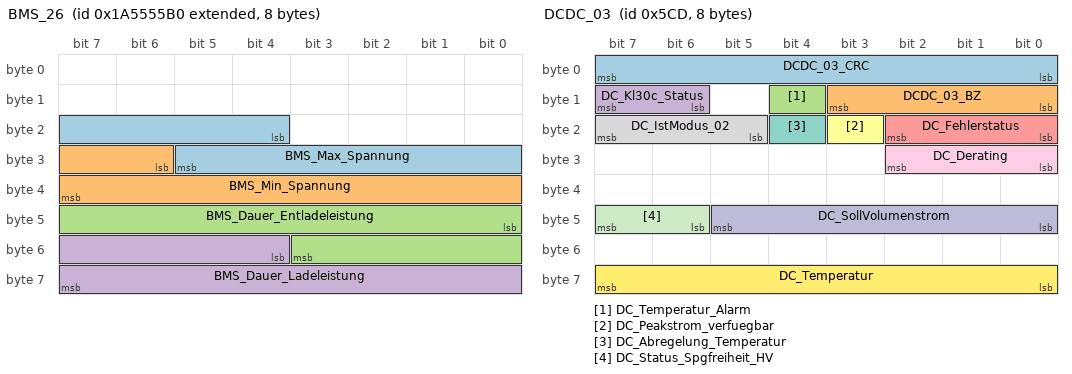
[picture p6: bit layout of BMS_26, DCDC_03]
BO_ 2589283760 BMS_26: 8 ICAS1_Gateway
 SG_ BMS_Max_Spannung  : 20|10@1+ (1.000000,0.000000) [0.000000|1000.000000] "Unit_Volt" Motor_BEV
 SG_ BMS_Min_Spannung  : 30|10@1+ (1.000000,0.000000) [0.000000|1000.000000] "Unit_Volt" Motor_BEV
 SG_ BMS_Dauer_Entladeleistung  : 40|12@1+ (200.000000,0.000000) [0.000000|818000.000000] "Unit_Watt" Motor_BEV
 SG_ BMS_Dauer_Ladeleistung  : 52|12@1+ (200.000000,0.000000) [0.000000|818000.000000] "Unit_Watt" Motor_BEV

BO_ 2463978646 Charisma_11: 24 ICAS1_Gateway
 SG_ CHA_Ziel_FahrPr_AGA  : 0|4@1+ (1.000000,0.000000) [0.000000|15.000000] "" Vector__XXX
 SG_ CHA_Ziel_FahrPr_ESP  : 4|4@1+ (1.000000,0.000000) [0.000000|15.000000] "" Motor_BEV
 SG_ CHA_Ziel_FahrPr_Freilauf  : 8|4@1+ (1.000000,0.000000) [0.000000|15.000000] "" Vector__XXX
 SG_ CHA_Fahrer_Umschaltung  : 14|1@1+ (1.000000,0.000000) [0.000000|1.000000] "" Motor_BEV
 SG_ CHA_Fahrer_Umschaltung_BMA  : 15|1@1+ (1.000000,0.000000) [0.000000|1.000000] "" Vector__XXX
 SG_ CHA_Ziel_FahrPr_MO  : 16|4@1+ (1.000000,0.000000) [0.000000|15.000000] "" Motor_BEV
 SG_ CHA_Ziel_FahrPr_GE  : 20|4@1+ (1.000000,0.000000) [0.000000|15.000000] "" Vector__XXX
 SG_ CHA_Ziel_FahrPr_ALR  : 24|4@1+ (1.000000,0.000000) [0.000000|15.000000] "" Motor_BEV
 SG_ CHA_Ziel_FahrPr_MO_BZS  : 28|4@1+ (1.000000,0.000000) [0.000000|15.000000] "" Vector__XXX
 SG_ CHA_Ziel_FahrPr_DR  : 32|4@1+ (1.000000,0.000000) [0.000000|15.000000] "" Vector__XXX
 SG_ CHA_Ziel_FahrPr_VAQ  : 36|4@1+ (1.000000,0.000000) [0.000000|15.000000] "" Vector__XXX
 SG_ CHA_Ziel_FahrPr_AFS  : 40|4@1+ (1.000000,0.000000) [0.000000|15.000000] "" Vector__XXX
 SG_ CHA_Ziel_FahrPr_PreCrash  : 44|4@1+ (1.000000,0.000000) [0.000000|15.000000] "" Airbag
 SG_ CHA_Ziel_FahrPr_EPS  : 48|4@1+ (1.000000,0.000000) [0.000000|15.000000] "" Vector__XXX
 SG_ CHA_Ziel_FahrPr_ACC  : 52|4@1+ (1.000000,0.000000) [0.000000|15.000000] "" Vector__XXX
 SG_ CHA_Ziel_FahrPr_SAK  : 56|4@1+ (1.000000,0.000000) [0.000000|15.000000] "" Vector__XXX
 SG_ CHA_Ziel_FahrPr_MO_StSt  : 60|4@1+ (1.000000,0.000000) [0.000000|15.000000] "" Vector__XXX
 SG_ CHA_Ziel_FahrPr_EBKV  : 64|4@1+ (1.000000,0.000000) [0.000000|15.000000] "" Vector__XXX
 SG_ CHA_Ziel_FahrPr_IL  : 68|4@1+ (1.000000,0.000000) [0.000000|15.000000] "" Vector__XXX
 SG_ CHA_Current_Mode  : 72|4@1+ (1.000000,0.000000) [0.000000|15.000000] "" Vector__XXX
 SG_ CHA_Ziel_FahrPr_QS  : 80|4@1+ (1.000000,0.000000) [0.000000|15.000000] "" Vector__XXX
 SG_ CHA_Ziel_FahrPr_SCU  : 84|4@1+ (1.000000,0.000000) [0.000000|15.000000] "" Vector__XXX
 SG_ CHA_Ziel_FahrPr_HAL  : 88|4@1+ (1.000000,0.000000) [0.000000|15.000000] "" Vector__XXX
 SG_ CHA_Ziel_FahrPr_NR  : 92|4@1+ (1.000000,0.000000) [0.000000|15.000000] "" Vector__XXX
 SG_ CHA_Ziel_FahrPr_AV  : 96|4@1+ (1.000000,0.000000) [0.000000|15.000000] "" Vector__XXX
 SG_ CHA_Ziel_FahrPr_MXB  : 100|4@1+ (1.000000,0.000000) [0.000000|15.000000] "" Vector__XXX
 SG_ CHA_Ziel_FahrPr_AFR  : 104|4@1+ (1.000000,0.000000) [0.000000|15.000000] "" Vector__XXX
 SG_ CHA_Ziel_FahrPr_HDC  : 108|4@1+ (1.000000,0.000000) [0.000000|15.000000] "" Vector__XXX
 SG_ CHA_Ziel_FahrPr_EAR  : 112|4@1+ (1.000000,0.000000) [0.000000|15.000000] "" Vector__XXX
 SG_ CHA_Ziel_FahrPr_AEB  : 116|4@1+ (1.000000,0.000000) [0.000000|15.000000] "" Vector__XXX
 SG_ CHA_Ziel_FahrPr_FCWO  : 120|4@1+ (1.000000,0.000000) [0.000000|15.000000] "" Vector__XXX
 SG_ CHA_Ziel_FahrPr_FCWP  : 124|4@1+ (1.000000,0.000000) [0.000000|15.000000] "" Vector__XXX
 SG_ CHA_Ziel_FahrPr_ToS_laengs  : 144|4@1+ (1.000000,0.000000) [0.000000|15.000000] "" Vector__XXX
 SG_ CHA_Ziel_FahrPr_ToS_quer  : 148|4@1+ (1.000000,0.000000) [0.000000|15.000000] "" Vector__XXX
 SG_ CHA_Ziel_FahrPr_mFDR  : 152|4@1+ (1.000000,0.000000) [0.000000|15.000000] "" Vector__XXX
 SG_ CHA_Ziel_FahrPr_Reku_ZwGas  : 156|4@1+ (1.000000,0.000000) [0.000000|15.000000] "" Vector__XXX
 SG_ CHA_Ziel_FahrPr_MO_Freilauf  : 160|4@1+ (1.000000,0.000000) [0.000000|15.000000] "" Vector__XXX
 SG_ CHA_Ziel_FahrPr_BMS  : 164|4@1+ (1.000000,0.000000) [0.000000|15.000000] "" Vector__XXX
 SG_ CHA_Current_Mode_BMA  : 168|4@1+ (1.000000,0.000000) [0.000000|15.000000] "" Vector__XXX
 SG_ CHA_Ziel_FahrPr_PDC  : 172|4@1+ (1.000000,0.000000) [0.000000|15.000000] "" Vector__XXX
 SG_ CHA_Ziel_FahrPr_HHC  : 176|4@1+ (1.000000,0.000000) [0.000000|15.000000] "" Vector__XXX
 SG_ CHA_Ziel_FahrPr_EDS  : 180|4@1+ (1.000000,0.000000) [0.000000|15.000000] "" Vector__XXX
 SG_ CHA_Ziel_FahrPr_PACC  : 184|4@1+ (1.000000,0.000000) [0.000000|15.000000] "" Vector__XXX
 SG_ CHA_Ziel_FahrPr_AGK  : 188|4@1+ (1.000000,0.000000) [0.000000|15.000000] "" Vector__XXX

BO_ 514 Daempfer_03: 32 ICAS1_Gateway
 SG_ DR_Aufbaubeschleunigung_HR  : 12|10@1+ (0.032700,-15.696000) [-15.696000|15.696000] "Unit_MeterPerSeconSquar" Motor_BEV
 SG_ DR_Aufbaubeschleunigung_VR  : 22|10@1+ (0.032700,-15.696000) [-15.696000|15.696000] "Unit_MeterPerSeconSquar" Motor_BEV
 SG_ DR_Aufbaubeschleunigung_VL  : 32|10@1+ (0.032700,-15.696000) [-15.696000|15.696000] "Unit_MeterPerSeconSquar" Motor_BEV
 SG_ DR_Aufbaubeschleunigung_HL  : 42|10@1+ (0.032700,-15.696000) [-15.696000|15.696000] "Unit_MeterPerSeconSquar" Motor_BEV
 SG_ DR_Funktionsstatus  : 52|2@1+ (1.000000,0.000000) [0.000000|3.000000] "" Vector__XXX
 SG_ DR_Drehwinkelsensortausch_VL  : 72|2@1+ (1.000000,0.000000) [1.000000|3.000000] "" Vector__XXX
 SG_ DR_Drehwinkelsensortausch_VR  : 74|2@1+ (1.000000,0.000000) [1.000000|3.000000] "" Vector__XXX
 SG_ DR_Drehwinkelsensortausch_HL  : 76|2@1+ (1.000000,0.000000) [1.000000|3.000000] "" Vector__XXX
 SG_ DR_Drehwinkelsensortausch_HR  : 78|2@1+ (1.000000,0.000000) [1.000000|3.000000] "" Vector__XXX
 SG_ DR_Drehwinkel_VL  : 80|12@1+ (0.088000,0.000000) [0.000000|359.920000] "" Vector__XXX
 SG_ DR_Drehwinkel_VR  : 92|12@1+ (0.088000,0.000000) [0.000000|359.920000] "" Vector__XXX
 SG_ DR_Drehwinkel_HL  : 104|12@1+ (0.088000,0.000000) [0.000000|359.920000] "" Vector__XXX
 SG_ DR_Drehwinkel_HR  : 116|12@1+ (0.088000,0.000000) [0.000000|359.920000] "" Vector__XXX

BO_ 1485 DCDC_03: 8 ICAS1_Gateway
 SG_ DCDC_03_CRC  : 0|8@1+ (1.000000,0.000000) [0.000000|255.000000] "" Motor_BEV
 SG_ DCDC_03_BZ  : 8|4@1+ (1.000000,0.000000) [0.000000|15.000000] "" Motor_BEV
 SG_ DC_Temperatur_Alarm  : 12|1@1+ (1.000000,0.000000) [0.000000|1.000000] "" Vector__XXX
 SG_ DC_Kl30c_Status  : 14|2@1+ (1.000000,0.000000) [0.000000|3.000000] "" Motor_BEV
 SG_ DC_Fehlerstatus  : 16|3@1+ (1.000000,0.000000) [0.000000|7.000000] "" Vector__XXX
 SG_ DC_Peakstrom_verfuegbar  : 19|1@1+ (1.000000,0.000000) [0.000000|1.000000] "" Vector__XXX
 SG_ DC_Abregelung_Temperatur  : 20|1@1+ (1.000000,0.000000) [0.000000|1.000000] "" Vector__XXX
 SG_ DC_IstModus_02  : 21|3@1+ (1.000000,0.000000) [0.000000|7.000000] "" Vector__XXX
 SG_ DC_Derating  : 24|3@1+ (1.000000,0.000000) [0.000000|7.000000] "" Vector__XXX
 SG_ DC_SollVolumenstrom  : 40|6@1+ (0.500000,0.000000) [0.000000|30.500000] "Unit_LiterPerMinut" Motor_BEV
 SG_ DC_Status_Spgfreiheit_HV  : 46|2@1+ (1.000000,0.000000) [0.000000|3.000000] "" Vector__XXX
 SG_ DC_Temperatur  : 56|8@1+ (1.000000,-40.000000) [-40.000000|213.000000] "Unit_DegreCelsi" Motor_BEV

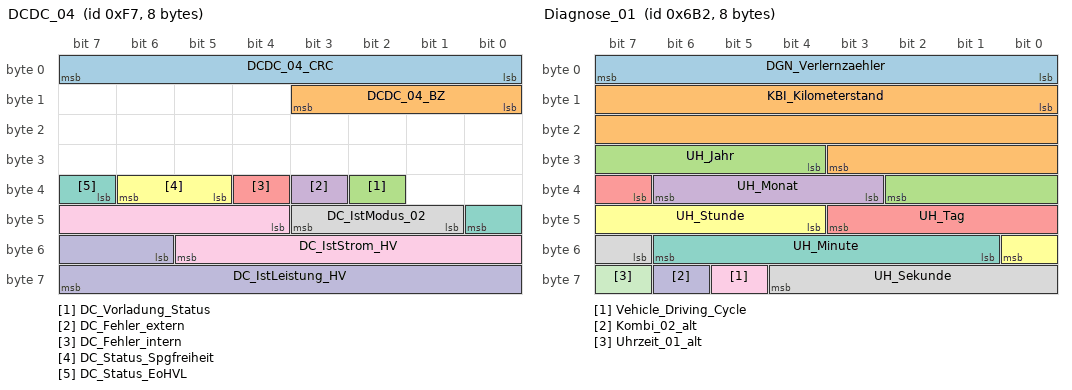
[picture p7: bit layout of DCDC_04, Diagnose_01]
BO_ 247 DCDC_04: 8 ICAS1_Gateway
 SG_ DCDC_04_CRC  : 0|8@1+ (1.000000,0.000000) [0.000000|255.000000] "" Vector__XXX
 SG_ DCDC_04_BZ  : 8|4@1+ (1.000000,0.000000) [0.000000|15.000000] "" Vector__XXX
 SG_ DC_Vorladung_Status  : 34|1@1+ (1.000000,0.000000) [0.000000|1.000000] "" Motor_BEV
 SG_ DC_Fehler_extern  : 35|1@1+ (1.000000,0.000000) [0.000000|1.000000] "" Motor_BEV
 SG_ DC_Fehler_intern  : 36|1@1+ (1.000000,0.000000) [0.000000|1.000000] "" Motor_BEV
 SG_ DC_Status_Spgfreiheit  : 37|2@1+ (1.000000,0.000000) [0.000000|3.000000] "" Motor_BEV
 SG_ DC_Status_EoHVL  : 39|2@1+ (1.000000,0.000000) [0.000000|3.000000] "" Motor_BEV
 SG_ DC_IstModus_02  : 41|3@1+ (1.000000,0.000000) [0.000000|7.000000] "" Motor_BEV
 SG_ DC_IstStrom_HV  : 44|10@1+ (0.100000,-51.100000) [-51.100000|51.000000] "Unit_Amper" Motor_BEV
 SG_ DC_IstLeistung_HV  : 54|10@1+ (10.000000,-4000.000000) [-4000.000000|6210.000000] "Unit_Watt" Motor_BEV

BO_ 2617027088 DEV_Airbag_ASM_01: 8 Airbag
 SG_ DEV_Airbag_ASM_01_Data  : 0|64@1+ (1.000000,0.000000) [0.000000|18446744073709551616.000000] "" Vector__XXX

BO_ 2617027072 DEV_Airbag_Resp_00: 8 Airbag
 SG_ DEV_Airbag_Resp_00_Data  : 0|64@1+ (1.000000,0.000000) [0.000000|18446744073709551616.000000] "" Vector__XXX

BO_ 2617027073 DEV_Airbag_Resp_01: 8 Airbag
 SG_ DEV_Airbag_Resp_01_Data  : 0|64@1+ (1.000000,0.000000) [0.000000|18446744073709551616.000000] "" Vector__XXX

BO_ 2617027074 DEV_Airbag_Resp_02: 8 Airbag
 SG_ DEV_Airbag_Resp_02_Data  : 0|64@1+ (1.000000,0.000000) [0.000000|18446744073709551616.000000] "" Vector__XXX

BO_ 2617027075 DEV_Airbag_Resp_03: 8 Airbag
 SG_ DEV_Airbag_Resp_03_Data  : 0|64@1+ (1.000000,0.000000) [0.000000|18446744073709551616.000000] "" Vector__XXX

BO_ 2617027076 DEV_Airbag_Resp_04: 8 Airbag
 SG_ DEV_Airbag_Resp_04_Data  : 0|64@1+ (1.000000,0.000000) [0.000000|18446744073709551616.000000] "" Vector__XXX

BO_ 2617027077 DEV_Airbag_Resp_05: 8 Airbag
 SG_ DEV_Airbag_Resp_05_Data  : 0|64@1+ (1.000000,0.000000) [0.000000|18446744073709551616.000000] "" Vector__XXX

BO_ 2617027078 DEV_Airbag_Resp_06: 8 Airbag
 SG_ DEV_Airbag_Resp_06_Data  : 0|64@1+ (1.000000,0.000000) [0.000000|18446744073709551616.000000] "" Vector__XXX

BO_ 2617027079 DEV_Airbag_Resp_07: 8 Airbag
 SG_ DEV_Airbag_Resp_07_Data  : 0|64@1+ (1.000000,0.000000) [0.000000|18446744073709551616.000000] "" Vector__XXX

BO_ 2617027080 DEV_Airbag_Resp_08: 8 Airbag
 SG_ DEV_Airbag_Resp_08_Data  : 0|64@1+ (1.000000,0.000000) [0.000000|18446744073709551616.000000] "" Vector__XXX

BO_ 2617027081 DEV_Airbag_Resp_09: 8 Airbag
 SG_ DEV_Airbag_Resp_09_Data  : 0|64@1+ (1.000000,0.000000) [0.000000|18446744073709551616.000000] "" Vector__XXX

BO_ 2617027082 DEV_Airbag_Resp_10: 8 Airbag
 SG_ DEV_Airbag_Resp_10_Data  : 0|64@1+ (1.000000,0.000000) [0.000000|18446744073709551616.000000] "" Vector__XXX

BO_ 2617027083 DEV_Airbag_Resp_11: 8 Airbag
 SG_ DEV_Airbag_Resp_11_Data  : 0|64@1+ (1.000000,0.000000) [0.000000|18446744073709551616.000000] "" Vector__XXX

BO_ 2617154048 DEV_Waehlhebel_Resp_00: 8 Schaltbetaetigung
 SG_ DEV_Waehlhebel_Resp_00_Data  : 0|64@1+ (1.000000,0.000000) [0.000000|18446744073709551616.000000] "" Vector__XXX

BO_ 2617154049 DEV_Waehlhebel_Resp_01: 8 Schaltbetaetigung
 SG_ DEV_Waehlhebel_Resp_01_Data  : 0|64@1+ (1.000000,0.000000) [0.000000|18446744073709551616.000000] "" Vector__XXX

BO_ 2617154050 DEV_Waehlhebel_Resp_02: 8 Schaltbetaetigung
 SG_ DEV_Waehlhebel_Resp_02_Data  : 0|64@1+ (1.000000,0.000000) [0.000000|18446744073709551616.000000] "" Vector__XXX

BO_ 2617154051 DEV_Waehlhebel_Resp_03: 8 Schaltbetaetigung
 SG_ DEV_Waehlhebel_Resp_03_Data  : 0|64@1+ (1.000000,0.000000) [0.000000|18446744073709551616.000000] "" Vector__XXX

BO_ 2617154052 DEV_Waehlhebel_Resp_04: 8 Schaltbetaetigung
 SG_ DEV_Waehlhebel_Resp_04_Data  : 0|64@1+ (1.000000,0.000000) [0.000000|18446744073709551616.000000] "" Vector__XXX

BO_ 2617154053 DEV_Waehlhebel_Resp_05: 8 Schaltbetaetigung
 SG_ DEV_Waehlhebel_Resp_05_Data  : 0|64@1+ (1.000000,0.000000) [0.000000|18446744073709551616.000000] "" Vector__XXX

BO_ 2549876269 Diag_Waehlhebel_Req: 8 Motor_BEV
 SG_ Diag_Waehlhebel_Req_Data  : 0|64@1+ (1.000000,0.000000) [0.000000|18446744073709551616.000000] "" Schaltbetaetigung

BO_ 2550007341 Diag_Waehlhebel_Resp: 8 Schaltbetaetigung
 SG_ Diag_Waehlhebel_Resp_Data  : 0|64@1+ (1.000000,0.000000) [0.000000|18446744073709551616.000000] "" Motor_BEV

BO_ 1714 Diagnose_01: 8 ICAS1_Gateway
 SG_ DGN_Verlernzaehler  : 0|8@1+ (1.000000,0.000000) [0.000000|254.000000] "" Airbag LE1 LE2 Motor_BEV
 SG_ KBI_Kilometerstand  : 8|20@1+ (1.000000,0.000000) [0.000000|1048573.000000] "Unit_KiloMeter" Airbag LE1 LE2 Motor_BEV
 SG_ UH_Jahr  : 28|7@1+ (1.000000,2000.000000) [2000.000000|2127.000000] "Unit_Year" Airbag LE1 LE2 Motor_BEV
 SG_ UH_Monat  : 35|4@1+ (1.000000,0.000000) [1.000000|12.000000] "Unit_Month" Airbag LE1 LE2 Motor_BEV
 SG_ UH_Tag  : 39|5@1+ (1.000000,0.000000) [1.000000|31.000000] "Unit_Day" Airbag LE1 LE2 Motor_BEV
 SG_ UH_Stunde  : 44|5@1+ (1.000000,0.000000) [0.000000|23.000000] "Unit_Hours" Airbag LE1 LE2 Motor_BEV
 SG_ UH_Minute  : 49|6@1+ (1.000000,0.000000) [0.000000|59.000000] "Unit_Minut" Airbag LE1 LE2 Motor_BEV
 SG_ UH_Sekunde  : 55|6@1+ (1.000000,0.000000) [0.000000|59.000000] "Unit_Secon" Airbag LE1 LE2 Motor_BEV
 SG_ Vehicle_Driving_Cycle  : 61|1@1+ (1.000000,0.000000) [0.000000|1.000000] "" Airbag
 SG_ Kombi_02_alt  : 62|1@1+ (1.000000,0.000000) [0.000000|1.000000] "" Vector__XXX
 SG_ Uhrzeit_01_alt  : 63|1@1+ (1.000000,0.000000) [0.000000|1.000000] "" Vector__XXX

BO_ 851 DiETa_01: 8 ICAS1_Gateway
 SG_ DiETas_01_CRC  : 0|8@1+ (1.000000,0.000000) [0.000000|255.000000] "" Airbag
 SG_ DiETas_01_BZ  : 8|4@1+ (1.000000,0.000000) [0.000000|15.000000] "" Airbag
 SG_ DiETa_Reserve_Byte2_4  : 12|1@1+ (1.000000,0.000000) [0.000000|1.000000] "" Vector__XXX
 SG_ DiETa_Status  : 13|2@1+ (1.000000,0.000000) [0.000000|3.000000] "" Airbag
 SG_ DiETa_ResponseError  : 15|1@1+ (1.000000,0.000000) [0.000000|1.000000] "" Vector__XXX
 SG_ DiETa_Car  : 16|2@1+ (1.000000,0.000000) [0.000000|3.000000] "" Vector__XXX
 SG_ DiETa_Klima  : 18|2@1+ (1.000000,0.000000) [0.000000|3.000000] "" Vector__XXX
 SG_ DiETa_Mode  : 20|2@1+ (1.000000,0.000000) [0.000000|3.000000] "" Vector__XXX
 SG_ DiETa_Parken  : 22|2@1+ (1.000000,0.000000) [0.000000|3.000000] "" Vector__XXX
 SG_ DiETa_FSH_Taste  : 24|2@1+ (1.000000,0.000000) [0.000000|3.000000] "" Vector__XXX
 SG_ DiETa_HSH_Taste  : 26|2@1+ (1.000000,0.000000) [0.000000|3.000000] "" Vector__XXX
 SG_ DiETa_Warnblink_Taste  : 28|2@1+ (1.000000,0.000000) [0.000000|3.000000] "" Vector__XXX
 SG_ DiETa_FAS_Stufe  : 30|2@1+ (1.000000,0.000000) [0.000000|3.000000] "" Vector__XXX
 SG_ DiETa_PAO_ON_Status  : 32|2@1+ (1.000000,0.000000) [0.000000|3.000000] "" Airbag
 SG_ DiETa_PAO_OFF_Status  : 34|2@1+ (1.000000,0.000000) [0.000000|3.000000] "" Airbag
 SG_ DiETa_Defrost_Taste  : 36|2@1+ (1.000000,0.000000) [0.000000|3.000000] "" Vector__XXX
 SG_ DiETa_Reserve_Byte5_6  : 38|2@1+ (1.000000,0.000000) [0.000000|3.000000] "" Vector__XXX
 SG_ DiETa_Lock_Unlock_Taste  : 40|3@1+ (1.000000,0.000000) [0.000000|7.000000] "" Vector__XXX
 SG_ DiETa_Mode_roh  : 43|1@1+ (1.000000,0.000000) [0.000000|1.000000] "" Vector__XXX
 SG_ DiETa_Reserve_Byte6_3  : 44|4@1+ (1.000000,0.000000) [0.000000|15.000000] "" Vector__XXX
 SG_ DiETa_Reserve_Byte7  : 48|8@1+ (1.000000,0.000000) [0.000000|255.000000] "" Vector__XXX
 SG_ DiETa_Reserve_Byte8  : 56|8@1+ (1.000000,0.000000) [0.000000|255.000000] "" Vector__XXX

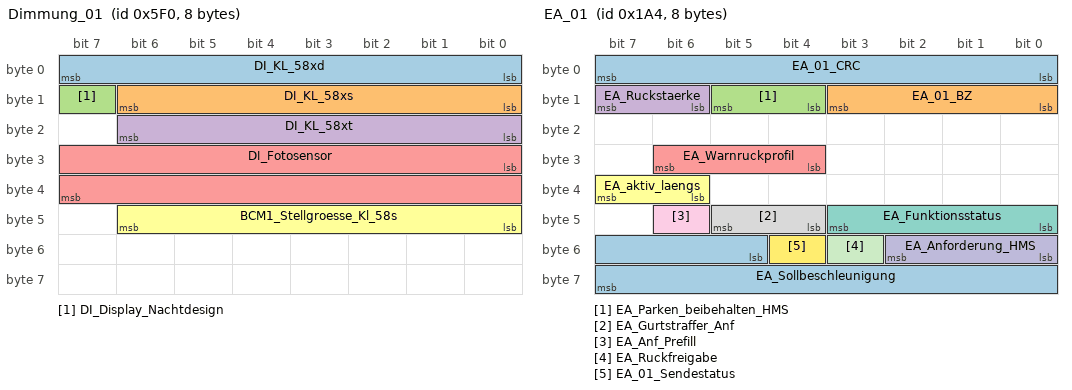
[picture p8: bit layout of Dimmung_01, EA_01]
BO_ 1520 Dimmung_01: 8 ICAS1_Gateway
 SG_ DI_KL_58xd  : 0|8@1+ (1.000000,0.000000) [0.000000|253.000000] "" Airbag Schaltbetaetigung
 SG_ DI_KL_58xs  : 8|7@1+ (1.000000,0.000000) [0.000000|100.000000] "Unit_PerCent" Airbag
 SG_ DI_Display_Nachtdesign  : 15|1@1+ (1.000000,0.000000) [0.000000|1.000000] "" Vector__XXX
 SG_ DI_KL_58xt  : 16|7@1+ (1.000000,0.000000) [0.000000|100.000000] "Unit_PerCent" Airbag Schaltbetaetigung
 SG_ DI_Fotosensor  : 24|16@1+ (1.000000,0.000000) [0.000000|65535.000000] "" Vector__XXX
 SG_ BCM1_Stellgroesse_Kl_58s  : 40|7@1+ (1.000000,0.000000) [0.000000|100.000000] "" Vector__XXX

BO_ 420 EA_01: 8 ICAS1_Gateway
 SG_ EA_01_CRC  : 0|8@1+ (1.000000,0.000000) [0.000000|255.000000] "" Motor_BEV
 SG_ EA_01_BZ  : 8|4@1+ (1.000000,0.000000) [0.000000|15.000000] "" Motor_BEV
 SG_ EA_Parken_beibehalten_HMS  : 12|2@1+ (1.000000,0.000000) [0.000000|3.000000] "" Vector__XXX
 SG_ EA_Ruckstaerke  : 14|2@1+ (1.000000,0.000000) [0.000000|3.000000] "" Vector__XXX
 SG_ EA_Warnruckprofil  : 28|3@1+ (1.000000,0.000000) [0.000000|7.000000] "" Vector__XXX
 SG_ EA_aktiv_laengs  : 38|2@1+ (1.000000,0.000000) [0.000000|3.000000] "" Motor_BEV
 SG_ EA_Funktionsstatus  : 40|4@1+ (1.000000,0.000000) [0.000000|15.000000] "" Motor_BEV
 SG_ EA_Gurtstraffer_Anf  : 44|2@1+ (1.000000,0.000000) [0.000000|3.000000] "" Airbag
 SG_ EA_Anf_Prefill  : 46|1@1+ (1.000000,0.000000) [0.000000|1.000000] "" Vector__XXX
 SG_ EA_Anforderung_HMS  : 48|3@1+ (1.000000,0.000000) [0.000000|7.000000] "" Vector__XXX
 SG_ EA_Ruckfreigabe  : 51|1@1+ (1.000000,0.000000) [0.000000|1.000000] "" Vector__XXX
 SG_ EA_01_Sendestatus  : 52|1@1+ (1.000000,0.000000) [0.000000|1.000000] "" Vector__XXX
 SG_ EA_Sollbeschleunigung  : 53|11@1+ (0.005000,-7.220000) [-7.220000|3.005000] "Unit_MeterPerSeconSquar" Motor_BEV

BO_ 374 EBKV_03: 8 ICAS1_Gateway
 SG_ EBKV_03_CRC  : 0|8@1+ (1.000000,0.000000) [0.000000|255.000000] "" Vector__XXX
 SG_ EBKV_03_BZ  : 8|4@1+ (1.000000,0.000000) [0.000000|15.000000] "" Vector__XXX
 SG_ EBKV_Activate_Fallback_ESP  : 12|1@1+ (1.000000,0.000000) [0.000000|1.000000] "" Vector__XXX
 SG_ EBKV_Restdruckabsenkung  : 13|3@1+ (1.000000,0.000000) [0.000000|7.000000] "" Vector__XXX
 SG_ EBKV_Status_02  : 16|4@1+ (1.000000,0.000000) [0.000000|15.000000] "" Vector__XXX
 SG_ EBKV_Diagnose  : 20|1@1+ (1.000000,0.000000) [0.000000|1.000000] "" Vector__XXX
 SG_ EBKV_Fahrer_bremst  : 21|1@1+ (1.000000,0.000000) [0.000000|1.000000] "" Motor_BEV
 SG_ EBKV_QBit_Fahrer_bremst  : 22|1@1+ (1.000000,0.000000) [0.000000|1.000000] "" Motor_BEV
 SG_ EBKV_Fahrer_bremst_deutlich  : 23|1@1+ (1.000000,0.000000) [0.000000|1.000000] "" Vector__XXX
 SG_ EBKV_OBD_Status  : 24|1@1+ (1.000000,0.000000) [0.000000|1.000000] "" Motor_BEV
 SG_ EBKV_VMM_Sek_Notstopp_Status  : 25|3@1+ (1.000000,0.000000) [0.000000|7.000000] "" Vector__XXX
 SG_ EBKV_Anforderung_HMS  : 28|3@1+ (1.000000,0.000000) [0.000000|7.000000] "" Vector__XXX
 SG_ SBS_Anforderung_GE  : 31|1@1+ (1.000000,0.000000) [0.000000|1.000000] "" Vector__XXX
 SG_ EPB_Status_ext  : 32|3@1+ (1.000000,0.000000) [0.000000|7.000000] "" Motor_BEV
 SG_ EBKV_Bremspedalweg  : 40|8@1+ (0.400000,-0.400000) [0.000000|101.200000] "Unit_PerCent" Motor_BEV
 SG_ EBKV_Kraftblending_Reserve  : 48|8@1+ (0.500000,0.000000) [0.000000|125.000000] "Unit_Bar" Vector__XXX
 SG_ EBKV_Aussteuerdruck  : 56|8@1+ (1.000000,0.000000) [0.000000|250.000000] "Unit_Bar" Vector__XXX

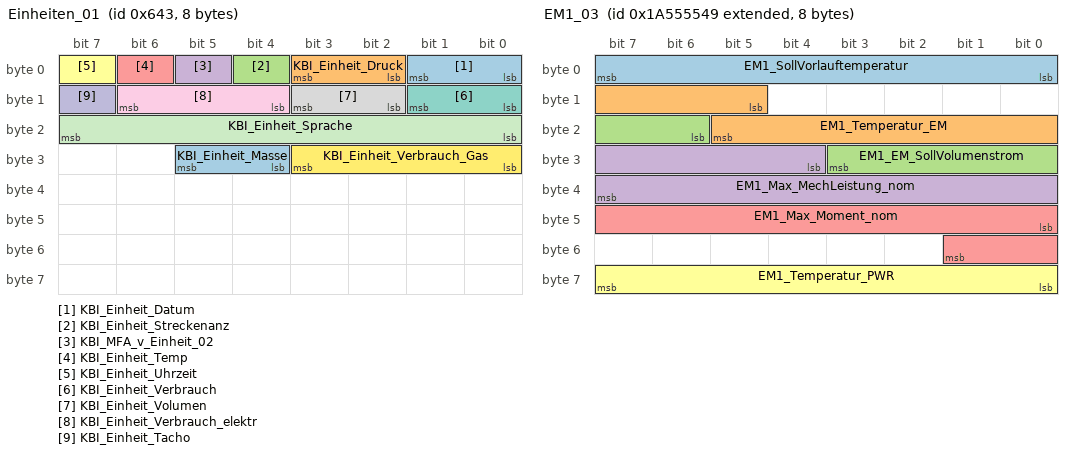
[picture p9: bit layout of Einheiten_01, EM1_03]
BO_ 1603 Einheiten_01: 8 ICAS1_KommunikationsServer
 SG_ KBI_Einheit_Datum  : 0|2@1+ (1.000000,0.000000) [0.000000|3.000000] "" Vector__XXX
 SG_ KBI_Einheit_Druck  : 2|2@1+ (1.000000,0.000000) [0.000000|3.000000] "" Vector__XXX
 SG_ KBI_Einheit_Streckenanz  : 4|1@1+ (1.000000,0.000000) [0.000000|1.000000] "" Vector__XXX
 SG_ KBI_MFA_v_Einheit_02  : 5|1@1+ (1.000000,0.000000) [0.000000|1.000000] "" Motor_BEV
 SG_ KBI_Einheit_Temp  : 6|1@1+ (1.000000,0.000000) [0.000000|1.000000] "" Vector__XXX
 SG_ KBI_Einheit_Uhrzeit  : 7|1@1+ (1.000000,0.000000) [0.000000|1.000000] "" Vector__XXX
 SG_ KBI_Einheit_Verbrauch  : 8|2@1+ (1.000000,0.000000) [0.000000|3.000000] "" Vector__XXX
 SG_ KBI_Einheit_Volumen  : 10|2@1+ (1.000000,0.000000) [0.000000|3.000000] "" Vector__XXX
 SG_ KBI_Einheit_Verbrauch_elektr  : 12|3@1+ (1.000000,0.000000) [0.000000|7.000000] "" Vector__XXX
 SG_ KBI_Einheit_Tacho  : 15|1@1+ (1.000000,0.000000) [0.000000|1.000000] "" Motor_BEV
 SG_ KBI_Einheit_Sprache  : 16|8@1+ (1.000000,0.000000) [0.000000|255.000000] "" Vector__XXX
 SG_ KBI_Einheit_Verbrauch_Gas  : 24|4@1+ (1.000000,0.000000) [0.000000|15.000000] "" Vector__XXX
 SG_ KBI_Einheit_Masse  : 28|2@1+ (1.000000,0.000000) [0.000000|3.000000] "" Vector__XXX

BO_ 192 EM1_01: 32 LE1
 SG_ EM1_01_CRC  : 0|8@1+ (1.000000,0.000000) [0.000000|255.000000] "" ICAS1_Gateway Motor_BEV
 SG_ EM1_01_BZ  : 8|4@1+ (1.000000,0.000000) [0.000000|15.000000] "" ICAS1_Gateway Motor_BEV
 SG_ EM1_Istmodus  : 12|4@1+ (1.000000,0.000000) [0.000000|15.000000] "" ICAS1_Gateway Motor_BEV
 SG_ EM1_IstMoment  : 16|12@1+ (0.500000,-1023.000000) [-1023.000000|1023.500000] "Unit_NewtoMeter" ICAS1_Gateway Motor_BEV
 SG_ EM1_Moment_AR_Eingriff  : 28|12@1+ (0.500000,-1023.000000) [-1023.000000|1023.500000] "Unit_NewtoMeter" ICAS1_Gateway Motor_BEV
 SG_ EM1_IstDrehzahl  : 40|15@1+ (1.000000,-10000.000000) [-10000.000000|22765.000000] "Unit_MinutInver" ICAS1_Gateway Motor_BEV
 SG_ EM1_AR_aktiv  : 55|1@1+ (1.000000,0.000000) [0.000000|1.000000] "" ICAS1_Gateway Motor_BEV
 SG_ EM1_IstSpannung  : 56|12@1+ (0.250000,0.000000) [0.000000|1023.250000] "Unit_Volt" ICAS1_Gateway Motor_BEV
 SG_ EM1_Strom_HV  : 68|12@1+ (0.500000,-1023.000000) [-1023.000000|1023.500000] "Unit_Amper" ICAS1_Gateway Motor_BEV
 SG_ EM1_Max_Moment  : 80|11@1+ (1.000000,-1023.000000) [-1023.000000|1022.000000] "Unit_NewtoMeter" ICAS1_Gateway Motor_BEV
 SG_ EM1_ErwGrenzen_aktiv  : 91|1@1+ (1.000000,0.000000) [0.000000|1.000000] "" ICAS1_Gateway Motor_BEV
 SG_ EM1_Min_Moment  : 92|11@1+ (1.000000,-1023.000000) [-1023.000000|1022.000000] "Unit_NewtoMeter" ICAS1_Gateway Motor_BEV
 SG_ EM1_Fehler_ElAntriebAbschaltung  : 103|1@1+ (1.000000,0.000000) [0.000000|1.000000] "" ICAS1_Gateway Motor_BEV
 SG_ EM1_Max_Moment_Lim  : 104|11@1+ (1.000000,-1023.000000) [-1023.000000|1022.000000] "Unit_NewtoMeter" ICAS1_Gateway Motor_BEV
 SG_ EM1_Fehler_Notabschaltung  : 115|1@1+ (1.000000,0.000000) [0.000000|1.000000] "" ICAS1_Gateway Motor_BEV
 SG_ EM1_Min_Moment_Lim  : 116|11@1+ (1.000000,-1023.000000) [-1023.000000|1022.000000] "Unit_NewtoMeter" ICAS1_Gateway Motor_BEV
 SG_ EM1_Status_DrzEingriff  : 127|2@1+ (1.000000,0.000000) [0.000000|3.000000] "" ICAS1_Gateway Motor_BEV
 SG_ EM1_Mom_DrzEingriff  : 129|11@1+ (1.000000,-1023.000000) [-1023.000000|1022.000000] "Unit_NewtoMeter" ICAS1_Gateway Motor_BEV

BO_ 2463978673 EM1_02: 32 LE1
 SG_ EM1_Status_Spgfreiheit  : 12|2@1+ (1.000000,0.000000) [0.000000|3.000000] "" Motor_BEV
 SG_ EM1_Status_EoHVL  : 14|2@1+ (1.000000,0.000000) [0.000000|3.000000] "" Motor_BEV
 SG_ EM1_Max_LeistungMech_Sockel  : 16|13@1+ (200.000000,-819000.000000) [-819000.000000|818800.000000] "Unit_Watt" Vector__XXX
 SG_ EM1_Max_Moment_Sockel  : 29|11@1+ (1.000000,-1023.000000) [-1023.000000|1022.000000] "Unit_NewtoMeter" Vector__XXX
 SG_ EM1_Min_LeistungMech_Sockel  : 40|13@1+ (200.000000,-819000.000000) [-819000.000000|818800.000000] "Unit_Watt" Vector__XXX
 SG_ EM1_Min_Moment_Sockel  : 53|11@1+ (1.000000,-1023.000000) [-1023.000000|1022.000000] "Unit_NewtoMeter" Vector__XXX
 SG_ EM1_PerfInd_MaxLeistung  : 64|10@1+ (0.200000,0.000000) [0.000000|200.000000] "Unit_PerCent" Motor_BEV
 SG_ EM1_PerfInd_MaxMoment  : 74|10@1+ (0.200000,0.000000) [0.000000|200.000000] "Unit_PerCent" Motor_BEV
 SG_ EM1_AnlernenElMotor_Anf  : 84|1@1+ (1.000000,0.000000) [0.000000|1.000000] "" Motor_BEV
 SG_ EM1_OBD_Lampe_Anf  : 85|1@1+ (1.000000,0.000000) [0.000000|1.000000] "" Motor_BEV
 SG_ EM1_Generator_Moment  : 86|10@1+ (1.000000,0.000000) [0.000000|1021.000000] "Unit_NewtoMeter" Motor_BEV
 SG_ EM1_PerfInd_Temperatur  : 96|8@1+ (0.800000,0.000000) [0.000000|200.000000] "Unit_PerCent" Motor_BEV
 SG_ EM1_MaxZul_Drehzahl  : 104|8@1+ (80.000000,0.000000) [0.000000|20240.000000] "Unit_RevPerMinute" Motor_BEV
 SG_ EM1_Min_Moment_Gesamt  : 112|11@1+ (1.000000,-1023.000000) [-1023.000000|1022.000000] "Unit_NewtoMeter" Motor_BEV
 SG_ EM1_Fehlerlampe_Anf  : 123|1@1+ (1.000000,0.000000) [0.000000|1.000000] "" Motor_BEV
 SG_ EM1_Max_Moment_Gesamt  : 124|11@1+ (1.000000,-1023.000000) [-1023.000000|1022.000000] "Unit_NewtoMeter" Motor_BEV
 SG_ EM1_Warnlampe_Anf  : 135|1@1+ (1.000000,0.000000) [0.000000|1.000000] "" Motor_BEV
 SG_ EM1_Rekuperation  : 136|15@1+ (10.000000,0.000000) [0.000000|327670.000000] "Unit_WattSecond" Motor_BEV
 SG_ EM1_Rekuperation_Ueberlauf  : 151|1@1+ (1.000000,0.000000) [0.000000|1.000000] "" Motor_BEV
 SG_ EM1_Verbrauch  : 152|15@1+ (10.000000,0.000000) [0.000000|327670.000000] "Unit_WattSecond" Motor_BEV
 SG_ EM1_Verbrauch_Ueberlauf  : 167|1@1+ (1.000000,0.000000) [0.000000|1.000000] "" Motor_BEV
 SG_ EM1_Fehler_AE  : 168|1@1+ (1.000000,0.000000) [0.000000|1.000000] "" Motor_BEV
 SG_ EM1_Fehler_Leistungsred  : 169|1@1+ (1.000000,0.000000) [0.000000|1.000000] "" Motor_BEV
 SG_ EM1_Fehler_ElAntriebFreilauf  : 170|1@1+ (1.000000,0.000000) [0.000000|1.000000] "" Motor_BEV
 SG_ EM1_PWR_SollVolumenstrom  : 171|6@1+ (0.500000,0.000000) [0.000000|30.500000] "Unit_LiterPerMinut" Motor_BEV

BO_ 2589283657 EM1_03: 8 LE1
 SG_ EM1_SollVorlauftemperatur  : 0|8@1+ (0.500000,-40.000000) [-40.000000|86.500000] "Unit_DegreCelsi" Motor_BEV
 SG_ EM1_Temperatur_EM  : 13|9@1+ (1.000000,-40.000000) [-40.000000|469.000000] "Unit_DegreCelsi" ICAS1_Gateway Motor_BEV
 SG_ EM1_EM_SollVolumenstrom  : 22|6@1+ (0.500000,0.000000) [0.000000|30.500000] "Unit_LiterPerMinut" Motor_BEV
 SG_ EM1_Max_MechLeistung_nom  : 28|12@1+ (200.000000,0.000000) [0.000000|818600.000000] "Unit_Watt" Motor_BEV
 SG_ EM1_Max_Moment_nom  : 40|10@1+ (1.000000,0.000000) [0.000000|1021.000000] "Unit_NewtoMeter" Motor_BEV
 SG_ EM1_Temperatur_PWR  : 56|8@1+ (1.000000,-40.000000) [-40.000000|213.000000] "Unit_DegreCelsi" ICAS1_Gateway Motor_BEV

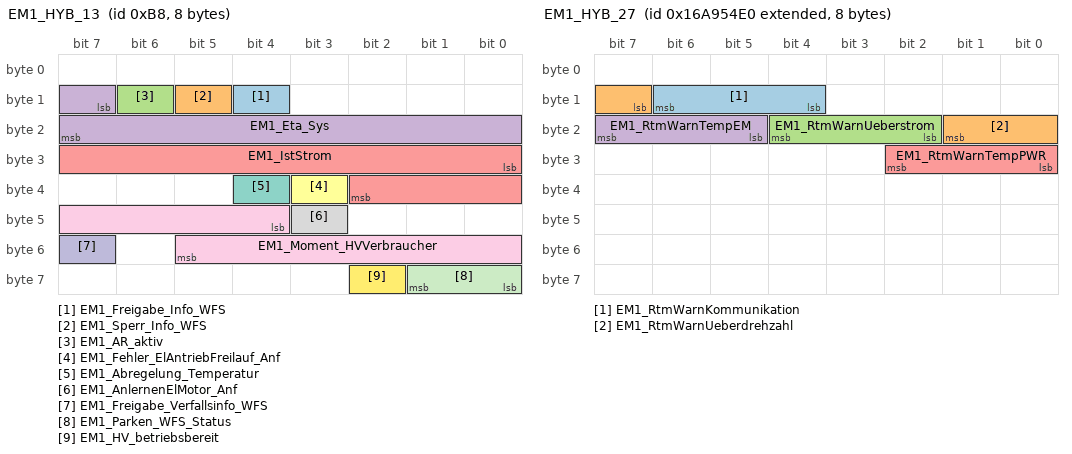
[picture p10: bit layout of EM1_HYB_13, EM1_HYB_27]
BO_ 184 EM1_HYB_13: 8 LE1
 SG_ EM1_Freigabe_Info_WFS  : 12|1@1+ (1.000000,0.000000) [0.000000|1.000000] "" ICAS1_Gateway Motor_BEV
 SG_ EM1_Sperr_Info_WFS  : 13|1@1+ (1.000000,0.000000) [0.000000|1.000000] "" ICAS1_Gateway Motor_BEV
 SG_ EM1_AR_aktiv  : 14|1@1+ (1.000000,0.000000) [0.000000|1.000000] "" ICAS1_Gateway
 SG_ EM1_Eta_Sys  : 15|9@1+ (0.200000,0.000000) [0.000000|101.800000] "Unit_PerCent" ICAS1_Gateway
 SG_ EM1_IstStrom  : 24|11@1+ (1.000000,-1023.000000) [-1023.000000|1022.000000] "Unit_Amper" ICAS1_Gateway
 SG_ EM1_Fehler_ElAntriebFreilauf_Anf  : 35|1@1+ (1.000000,0.000000) [0.000000|1.000000] "" ICAS1_Gateway
 SG_ EM1_Abregelung_Temperatur  : 36|1@1+ (1.000000,0.000000) [0.000000|1.000000] "" ICAS1_Gateway
 SG_ EM1_AnlernenElMotor_Anf  : 43|1@1+ (1.000000,0.000000) [0.000000|1.000000] "" ICAS1_Gateway
 SG_ EM1_Moment_HVVerbraucher  : 44|10@1+ (1.000000,-511.000000) [-511.000000|511.000000] "Unit_NewtoMeter" ICAS1_Gateway
 SG_ EM1_Freigabe_Verfallsinfo_WFS  : 55|1@1+ (1.000000,0.000000) [0.000000|1.000000] "" ICAS1_Gateway Motor_BEV
 SG_ EM1_Parken_WFS_Status  : 56|2@1+ (1.000000,0.000000) [0.000000|3.000000] "" ICAS1_Gateway
 SG_ EM1_HV_betriebsbereit  : 58|1@1+ (1.000000,0.000000) [0.000000|1.000000] "" ICAS1_Gateway

BO_ 2527679712 EM1_HYB_27: 8 LE1
 SG_ EM1_RtmWarnKommunikation  : 12|3@1+ (1.000000,0.000000) [0.000000|7.000000] "" Vector__XXX
 SG_ EM1_RtmWarnUeberdrehzahl  : 15|3@1+ (1.000000,0.000000) [0.000000|7.000000] "" ICAS1_Gateway
 SG_ EM1_RtmWarnUeberstrom  : 18|3@1+ (1.000000,0.000000) [0.000000|7.000000] "" ICAS1_Gateway
 SG_ EM1_RtmWarnTempEM  : 21|3@1+ (1.000000,0.000000) [0.000000|7.000000] "" ICAS1_Gateway
 SG_ EM1_RtmWarnTempPWR  : 24|3@1+ (1.000000,0.000000) [0.000000|7.000000] "" ICAS1_Gateway

BO_ 193 EM2_01: 32 LE2
 SG_ EM2_01_CRC  : 0|8@1+ (1.000000,0.000000) [0.000000|255.000000] "" Motor_BEV
 SG_ EM2_01_BZ  : 8|4@1+ (1.000000,0.000000) [0.000000|15.000000] "" Motor_BEV
 SG_ EM2_Istmodus  : 12|4@1+ (1.000000,0.000000) [0.000000|15.000000] "" ICAS1_Gateway Motor_BEV
 SG_ EM2_IstMoment  : 16|12@1+ (0.500000,-1023.000000) [-1023.000000|1023.500000] "Unit_NewtoMeter" ICAS1_Gateway Motor_BEV
 SG_ EM2_Moment_AR_Eingriff  : 28|12@1+ (0.500000,-1023.000000) [-1023.000000|1023.500000] "Unit_NewtoMeter" Motor_BEV
 SG_ EM2_IstDrehzahl  : 40|15@1+ (1.000000,-10000.000000) [-10000.000000|22765.000000] "Unit_MinutInver" ICAS1_Gateway Motor_BEV
 SG_ EM2_AR_aktiv  : 55|1@1+ (1.000000,0.000000) [0.000000|1.000000] "" Motor_BEV
 SG_ EM2_IstSpannung  : 56|12@1+ (0.250000,0.000000) [0.000000|1023.250000] "Unit_Volt" ICAS1_Gateway Motor_BEV
 SG_ EM2_Strom_HV  : 68|12@1+ (0.500000,-1023.000000) [-1023.000000|1023.500000] "Unit_Amper" ICAS1_Gateway Motor_BEV
 SG_ EM2_Max_Moment  : 80|11@1+ (1.000000,-1023.000000) [-1023.000000|1022.000000] "Unit_NewtoMeter" Motor_BEV
 SG_ EM2_ErwGrenzen_aktiv  : 91|1@1+ (1.000000,0.000000) [0.000000|1.000000] "" Motor_BEV
 SG_ EM2_Min_Moment  : 92|11@1+ (1.000000,-1023.000000) [-1023.000000|1022.000000] "Unit_NewtoMeter" Motor_BEV
 SG_ EM2_Fehler_ElAntriebAbschaltung  : 103|1@1+ (1.000000,0.000000) [0.000000|1.000000] "" Motor_BEV
 SG_ EM2_Max_Moment_Lim  : 104|11@1+ (1.000000,-1023.000000) [-1023.000000|1022.000000] "Unit_NewtoMeter" Motor_BEV
 SG_ EM2_Fehler_Notabschaltung  : 115|1@1+ (1.000000,0.000000) [0.000000|1.000000] "" ICAS1_Gateway Motor_BEV
 SG_ EM2_Min_Moment_Lim  : 116|11@1+ (1.000000,-1023.000000) [-1023.000000|1022.000000] "Unit_NewtoMeter" Motor_BEV
 SG_ EM2_Status_DrzEingriff  : 127|2@1+ (1.000000,0.000000) [0.000000|3.000000] "" ICAS1_Gateway Motor_BEV
 SG_ EM2_Mom_DrzEingriff  : 129|11@1+ (1.000000,-1023.000000) [-1023.000000|1022.000000] "Unit_NewtoMeter" Motor_BEV

BO_ 2463978674 EM2_02: 32 LE2
 SG_ EM2_Status_Spgfreiheit  : 12|2@1+ (1.000000,0.000000) [0.000000|3.000000] "" Motor_BEV
 SG_ EM2_Status_EoHVL  : 14|2@1+ (1.000000,0.000000) [0.000000|3.000000] "" Motor_BEV
 SG_ EM2_Max_LeistungMech_Sockel  : 16|13@1+ (200.000000,-819000.000000) [-819000.000000|818800.000000] "Unit_Watt" Vector__XXX
 SG_ EM2_Max_Moment_Sockel  : 29|11@1+ (1.000000,-1023.000000) [-1023.000000|1022.000000] "Unit_NewtoMeter" Vector__XXX
 SG_ EM2_Min_LeistungMech_Sockel  : 40|13@1+ (200.000000,-819000.000000) [-819000.000000|818800.000000] "Unit_Watt" Vector__XXX
 SG_ EM2_Min_Moment_Sockel  : 53|11@1+ (1.000000,-1023.000000) [-1023.000000|1022.000000] "Unit_NewtoMeter" Vector__XXX
 SG_ EM2_PerfInd_MaxLeistung  : 64|10@1+ (0.200000,0.000000) [0.000000|200.000000] "Unit_PerCent" Motor_BEV
 SG_ EM2_PerfInd_MaxMoment  : 74|10@1+ (0.200000,0.000000) [0.000000|200.000000] "Unit_PerCent" Motor_BEV
 SG_ EM2_AnlernenElMotor_Anf  : 84|1@1+ (1.000000,0.000000) [0.000000|1.000000] "" Motor_BEV
 SG_ EM2_OBD_Lampe_Anf  : 85|1@1+ (1.000000,0.000000) [0.000000|1.000000] "" Motor_BEV
 SG_ EM2_Generator_Moment  : 86|10@1+ (1.000000,0.000000) [0.000000|1021.000000] "Unit_NewtoMeter" Motor_BEV
 SG_ EM2_PerfInd_Temperatur  : 96|8@1+ (0.800000,0.000000) [0.000000|200.000000] "Unit_PerCent" Motor_BEV
 SG_ EM2_MaxZul_Drehzahl  : 104|8@1+ (80.000000,0.000000) [0.000000|20240.000000] "Unit_RevPerMinute" Motor_BEV
 SG_ EM2_Min_Moment_Gesamt  : 112|11@1+ (1.000000,-1023.000000) [-1023.000000|1022.000000] "Unit_NewtoMeter" Motor_BEV
 SG_ EM2_Fehlerlampe_Anf  : 123|1@1+ (1.000000,0.000000) [0.000000|1.000000] "" Motor_BEV
 SG_ EM2_Max_Moment_Gesamt  : 124|11@1+ (1.000000,-1023.000000) [-1023.000000|1022.000000] "Unit_NewtoMeter" Motor_BEV
 SG_ EM2_Warnlampe_Anf  : 135|1@1+ (1.000000,0.000000) [0.000000|1.000000] "" Motor_BEV
 SG_ EM2_Rekuperation  : 136|15@1+ (10.000000,0.000000) [0.000000|327670.000000] "Unit_WattSecond" Motor_BEV
 SG_ EM2_Rekuperation_Ueberlauf  : 151|1@1+ (1.000000,0.000000) [0.000000|1.000000] "" Motor_BEV
 SG_ EM2_Verbrauch  : 152|15@1+ (10.000000,0.000000) [0.000000|327670.000000] "Unit_WattSecond" Motor_BEV
 SG_ EM2_Verbrauch_Ueberlauf  : 167|1@1+ (1.000000,0.000000) [0.000000|1.000000] "" Motor_BEV
 SG_ EM2_Fehler_AE  : 168|1@1+ (1.000000,0.000000) [0.000000|1.000000] "" Motor_BEV
 SG_ EM2_Fehler_Leistungsred  : 169|1@1+ (1.000000,0.000000) [0.000000|1.000000] "" Motor_BEV
 SG_ EM2_Fehler_ElAntriebFreilauf  : 170|1@1+ (1.000000,0.000000) [0.000000|1.000000] "" Motor_BEV
 SG_ EM2_PWR_SollVolumenstrom  : 171|6@1+ (0.500000,0.000000) [0.000000|30.500000] "Unit_LiterPerMinut" Motor_BEV

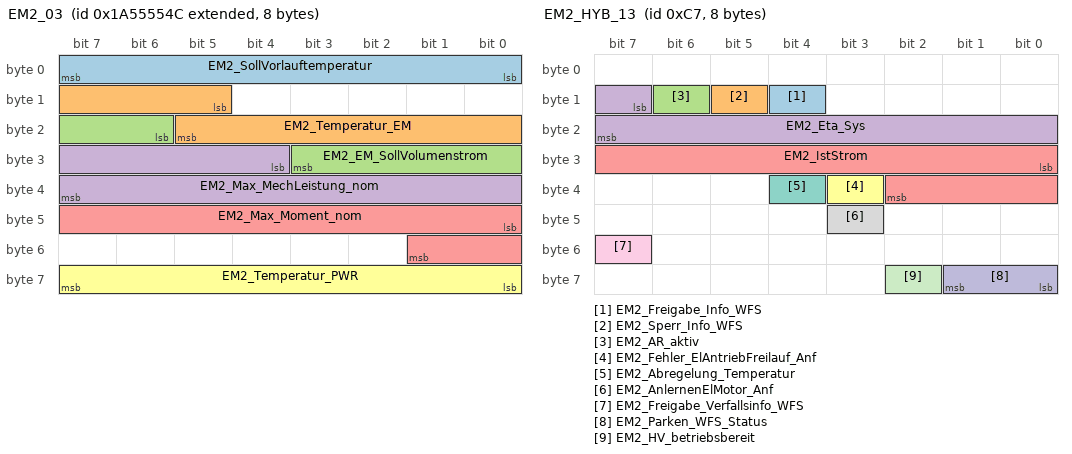
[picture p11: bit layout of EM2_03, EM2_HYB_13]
BO_ 2589283660 EM2_03: 8 LE2
 SG_ EM2_SollVorlauftemperatur  : 0|8@1+ (0.500000,-40.000000) [-40.000000|86.500000] "Unit_DegreCelsi" Motor_BEV
 SG_ EM2_Temperatur_EM  : 13|9@1+ (1.000000,-40.000000) [-40.000000|469.000000] "Unit_DegreCelsi" ICAS1_Gateway Motor_BEV
 SG_ EM2_EM_SollVolumenstrom  : 22|6@1+ (0.500000,0.000000) [0.000000|30.500000] "Unit_LiterPerMinut" Motor_BEV
 SG_ EM2_Max_MechLeistung_nom  : 28|12@1+ (200.000000,0.000000) [0.000000|818600.000000] "Unit_Watt" Motor_BEV
 SG_ EM2_Max_Moment_nom  : 40|10@1+ (1.000000,0.000000) [0.000000|1021.000000] "Unit_NewtoMeter" Motor_BEV
 SG_ EM2_Temperatur_PWR  : 56|8@1+ (1.000000,-40.000000) [-40.000000|213.000000] "Unit_DegreCelsi" ICAS1_Gateway Motor_BEV

BO_ 199 EM2_HYB_13: 8 LE2
 SG_ EM2_Freigabe_Info_WFS  : 12|1@1+ (1.000000,0.000000) [0.000000|1.000000] "" ICAS1_Gateway Motor_BEV
 SG_ EM2_Sperr_Info_WFS  : 13|1@1+ (1.000000,0.000000) [0.000000|1.000000] "" ICAS1_Gateway Motor_BEV
 SG_ EM2_AR_aktiv  : 14|1@1+ (1.000000,0.000000) [0.000000|1.000000] "" ICAS1_Gateway
 SG_ EM2_Eta_Sys  : 15|9@1+ (0.200000,0.000000) [0.000000|101.800000] "Unit_PerCent" ICAS1_Gateway
 SG_ EM2_IstStrom  : 24|11@1+ (1.000000,-1023.000000) [-1023.000000|1022.000000] "Unit_Amper" ICAS1_Gateway
 SG_ EM2_Fehler_ElAntriebFreilauf_Anf  : 35|1@1+ (1.000000,0.000000) [0.000000|1.000000] "" ICAS1_Gateway
 SG_ EM2_Abregelung_Temperatur  : 36|1@1+ (1.000000,0.000000) [0.000000|1.000000] "" ICAS1_Gateway
 SG_ EM2_AnlernenElMotor_Anf  : 43|1@1+ (1.000000,0.000000) [0.000000|1.000000] "" ICAS1_Gateway
 SG_ EM2_Freigabe_Verfallsinfo_WFS  : 55|1@1+ (1.000000,0.000000) [0.000000|1.000000] "" ICAS1_Gateway Motor_BEV
 SG_ EM2_Parken_WFS_Status  : 56|2@1+ (1.000000,0.000000) [0.000000|3.000000] "" ICAS1_Gateway
 SG_ EM2_HV_betriebsbereit  : 58|1@1+ (1.000000,0.000000) [0.000000|1.000000] "" ICAS1_Gateway

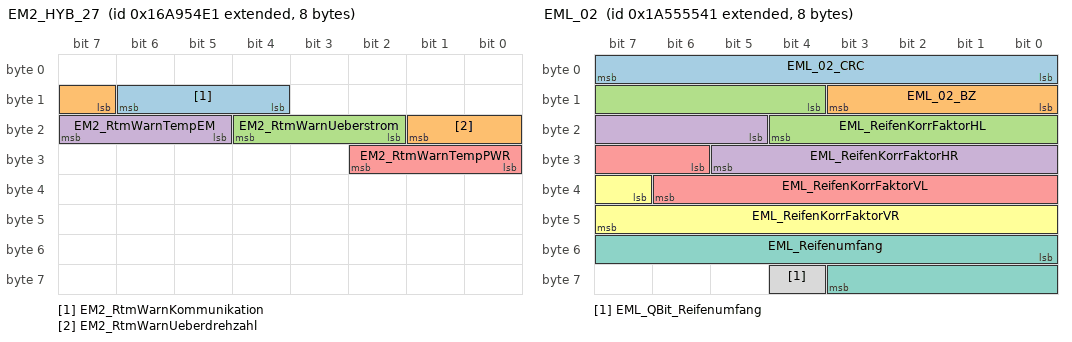
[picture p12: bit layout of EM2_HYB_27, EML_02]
BO_ 2527679713 EM2_HYB_27: 8 LE2
 SG_ EM2_RtmWarnKommunikation  : 12|3@1+ (1.000000,0.000000) [0.000000|7.000000] "" Vector__XXX
 SG_ EM2_RtmWarnUeberdrehzahl  : 15|3@1+ (1.000000,0.000000) [0.000000|7.000000] "" ICAS1_Gateway
 SG_ EM2_RtmWarnUeberstrom  : 18|3@1+ (1.000000,0.000000) [0.000000|7.000000] "" ICAS1_Gateway
 SG_ EM2_RtmWarnTempEM  : 21|3@1+ (1.000000,0.000000) [0.000000|7.000000] "" ICAS1_Gateway
 SG_ EM2_RtmWarnTempPWR  : 24|3@1+ (1.000000,0.000000) [0.000000|7.000000] "" ICAS1_Gateway

BO_ 2589283649 EML_02: 8 ICAS1_Gateway
 SG_ EML_02_CRC  : 0|8@1+ (1.000000,0.000000) [0.000000|255.000000] "" Vector__XXX
 SG_ EML_02_BZ  : 8|4@1+ (1.000000,0.000000) [0.000000|15.000000] "" Vector__XXX
 SG_ EML_ReifenKorrFaktorHL  : 12|9@1+ (0.000488,0.850000) [0.850000|1.098535] "" Vector__XXX
 SG_ EML_ReifenKorrFaktorHR  : 21|9@1+ (0.000488,0.850000) [0.850000|1.098535] "" Vector__XXX
 SG_ EML_ReifenKorrFaktorVL  : 30|9@1+ (0.000488,0.850000) [0.850000|1.098535] "" Vector__XXX
 SG_ EML_ReifenKorrFaktorVR  : 39|9@1+ (0.000488,0.850000) [0.850000|1.098535] "" Vector__XXX
 SG_ EML_Reifenumfang  : 48|12@1+ (1.000000,0.000000) [0.000000|4095.000000] "Unit_MilliMeter" Motor_BEV
 SG_ EML_QBit_Reifenumfang  : 60|1@1+ (1.000000,0.000000) [0.000000|1.000000] "" Motor_BEV

BO_ 608 EML_07: 8 ICAS1_Gateway
 SG_ EML_AnzeigeGeschw  : 54|10@1+ (0.320000,0.000000) [0.000000|325.120000] "Unit_KiloMeterPerHour" Motor_BEV

BO_ 2589283751 Entfernungen_01: 8 ICAS1_KommunikationsServer
 SG_ KBI_Kilometerstand_HiRes_meter  : 32|32@1+ (1.000000,0.000000) [0.000000|4294967295.000000] "Unit_Meter" Motor_BEV

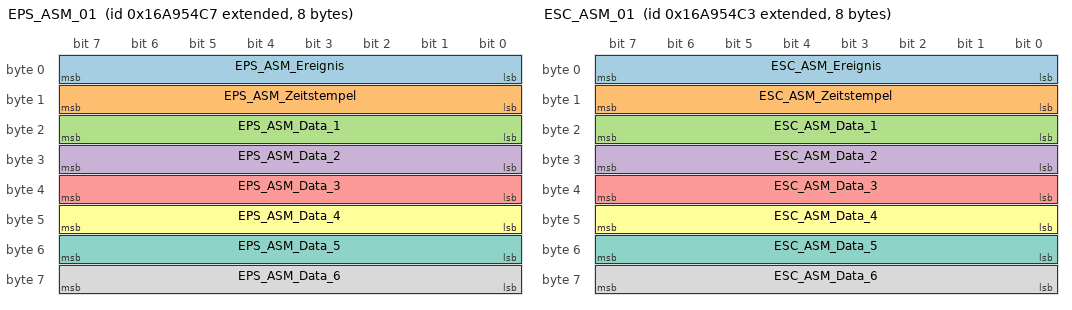
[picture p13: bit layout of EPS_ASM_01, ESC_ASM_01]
BO_ 2527679687 EPS_ASM_01: 8 ICAS1_Gateway
 SG_ EPS_ASM_Ereignis  : 0|8@1+ (1.000000,0.000000) [1.000000|254.000000] "Unit_None" Airbag
 SG_ EPS_ASM_Zeitstempel  : 8|8@1+ (0.080000,0.000000) [0.000000|20.320000] "Unit_None" Airbag
 SG_ EPS_ASM_Data_1  : 16|8@1+ (1.000000,0.000000) [0.000000|255.000000] "Unit_None" Airbag
 SG_ EPS_ASM_Data_2  : 24|8@1+ (1.000000,0.000000) [0.000000|255.000000] "Unit_None" Airbag
 SG_ EPS_ASM_Data_3  : 32|8@1+ (1.000000,0.000000) [0.000000|255.000000] "Unit_None" Airbag
 SG_ EPS_ASM_Data_4  : 40|8@1+ (1.000000,0.000000) [0.000000|255.000000] "Unit_None" Airbag
 SG_ EPS_ASM_Data_5  : 48|8@1+ (1.000000,0.000000) [0.000000|255.000000] "Unit_None" Airbag
 SG_ EPS_ASM_Data_6  : 56|8@1+ (1.000000,0.000000) [0.000000|255.000000] "Unit_None" Airbag

BO_ 258 ESC_50: 48 ICAS1_Gateway
 SG_ ESC_50_CRC  : 0|8@1+ (1.000000,0.000000) [0.000000|255.000000] "" Motor_BEV
 SG_ ESC_50_BZ  : 8|4@1+ (1.000000,0.000000) [0.000000|15.000000] "" Motor_BEV
 SG_ ESP_QBit_Gierrate  : 12|1@1+ (1.000000,0.000000) [0.000000|1.000000] "" Motor_BEV
 SG_ ESP_QBit_Laengsbeschl  : 13|1@1+ (1.000000,0.000000) [0.000000|1.000000] "" Motor_BEV
 SG_ ESP_QBit_Querb  : 14|1@1+ (1.000000,0.000000) [0.000000|1.000000] "" Motor_BEV
 SG_ ESP_Querbeschleunigung  : 16|8@1+ (0.010000,-1.270000) [-1.270000|1.270000] "Unit_ForceOfGravi" Airbag Motor_BEV
 SG_ ESP_Laengsbeschl  : 24|10@1+ (0.031250,-16.000000) [-16.000000|15.906250] "Unit_MeterPerSeconSquar" Airbag Motor_BEV
 SG_ ESC_Motorstartverzoegerung  : 34|1@1+ (1.000000,0.000000) [0.000000|1.000000] "" Vector__XXX
 SG_ ESC_SeitenwindAssistent_Eingriff  : 35|1@1+ (1.000000,0.000000) [0.000000|1.000000] "" Vector__XXX
 SG_ ESP_Anschleppstart_Freigabe  : 36|2@1+ (1.000000,0.000000) [0.000000|3.000000] "" Vector__XXX
 SG_ ESC_Unterdruckmangel_erkannt  : 38|1@1+ (1.000000,0.000000) [0.000000|1.000000] "" Vector__XXX
 SG_ ESP_Gierrate  : 40|14@1+ (0.010000,0.000000) [0.000000|163.820000] "Unit_DegreOfArcPerSecon" Airbag Motor_BEV
 SG_ ESP_VZ_Gierrate  : 54|1@1+ (1.000000,0.000000) [0.000000|1.000000] "" Airbag Motor_BEV
 SG_ ESP_Notbremsanzeige  : 55|1@1+ (1.000000,0.000000) [0.000000|1.000000] "" Vector__XXX
 SG_ ESP_SpannungsAnf  : 56|1@1+ (1.000000,0.000000) [0.000000|1.000000] "" Vector__XXX
 SG_ ESP_PLA_Abbruch  : 57|3@1+ (1.000000,0.000000) [0.000000|7.000000] "" Vector__XXX
 SG_ ESP_Status_ESP_PLA  : 60|4@1+ (1.000000,0.000000) [0.000000|15.000000] "" Vector__XXX
 SG_ ESP_QBit_Bremsdruck  : 76|1@1+ (1.000000,0.000000) [0.000000|1.000000] "" Airbag Motor_BEV
 SG_ ESP_QBit_Fahrer_bremst  : 77|1@1+ (1.000000,0.000000) [0.000000|1.000000] "" Vector__XXX
 SG_ ESP_Schwelle_Unterdruck  : 78|2@1+ (1.000000,0.000000) [0.000000|3.000000] "" Vector__XXX
 SG_ ESP_Bremsdruck  : 80|10@1+ (0.300000,-30.000000) [-30.000000|276.600000] "Unit_Bar" Motor_BEV
 SG_ ESP_Fahrer_bremst  : 90|1@1+ (1.000000,0.000000) [0.000000|1.000000] "" Vector__XXX
 SG_ ESP_Verz_TSK_aktiv  : 91|1@1+ (1.000000,0.000000) [0.000000|1.000000] "" Vector__XXX
 SG_ ESP_Lenkeingriff_ADS  : 92|1@1+ (1.000000,0.000000) [0.000000|1.000000] "" Vector__XXX
 SG_ ESP_Konsistenz_TSK  : 93|1@1+ (1.000000,0.000000) [0.000000|1.000000] "" Vector__XXX
 SG_ ESP_Bremsruck_AWV2  : 94|1@1+ (1.000000,0.000000) [0.000000|1.000000] "" Vector__XXX
 SG_ ESP_Konsistenz_AWV2  : 95|1@1+ (1.000000,0.000000) [0.000000|1.000000] "" Vector__XXX
 SG_ ECD_Fehler  : 96|1@1+ (1.000000,0.000000) [0.000000|1.000000] "" Vector__XXX
 SG_ ECD_nicht_verfuegbar  : 97|1@1+ (1.000000,0.000000) [0.000000|1.000000] "" Vector__XXX
 SG_ ESP_Status_Bremsentemp  : 98|1@1+ (1.000000,0.000000) [0.000000|1.000000] "" Vector__XXX
 SG_ ESP_Autohold_Standby  : 99|1@1+ (1.000000,0.000000) [0.000000|1.000000] "" Vector__XXX
 SG_ ESP_HDC_Standby  : 100|1@1+ (1.000000,0.000000) [0.000000|1.000000] "" Vector__XXX
 SG_ ESP_HBA_aktiv  : 101|1@1+ (1.000000,0.000000) [0.000000|1.000000] "" Vector__XXX
 SG_ ESP_Prefill_ausgeloest  : 102|1@1+ (1.000000,0.000000) [0.000000|1.000000] "" Vector__XXX
 SG_ ESP_Rueckwaertsfahrt_erkannt  : 103|1@1+ (1.000000,0.000000) [0.000000|1.000000] "" Vector__XXX
 SG_ ESP_Status_Anfahrhilfe  : 104|1@1+ (1.000000,0.000000) [0.000000|1.000000] "" Vector__XXX
 SG_ ESP_HDC_aktiv  : 105|1@1+ (1.000000,0.000000) [0.000000|1.000000] "" Vector__XXX
 SG_ ESP_StartStopp_Info  : 106|2@1+ (1.000000,0.000000) [0.000000|3.000000] "" Vector__XXX
 SG_ ESP_Eingr_HL  : 108|1@1+ (1.000000,0.000000) [0.000000|1.000000] "" Vector__XXX
 SG_ ESP_Eingr_HR  : 109|1@1+ (1.000000,0.000000) [0.000000|1.000000] "" Vector__XXX
 SG_ ESP_Eingr_VL  : 110|1@1+ (1.000000,0.000000) [0.000000|1.000000] "" Vector__XXX
 SG_ ESP_Eingr_VR  : 111|1@1+ (1.000000,0.000000) [0.000000|1.000000] "" Vector__XXX
 SG_ ESP_BKV_Unterdruck  : 112|8@1+ (4.000000,0.000000) [4.000000|1012.000000] "Unit_MilliBar" Vector__XXX
 SG_ ESP_Autohold_aktiv  : 120|1@1+ (1.000000,0.000000) [0.000000|1.000000] "" Vector__XXX
 SG_ ESP_FStatus_Anfahrhilfe  : 121|1@1+ (1.000000,0.000000) [0.000000|1.000000] "" Vector__XXX
 SG_ ESP_Verz_EPB_aktiv  : 122|1@1+ (1.000000,0.000000) [0.000000|1.000000] "" Vector__XXX
 SG_ ECD_Bremslicht  : 123|1@1+ (1.000000,0.000000) [0.000000|1.000000] "" Motor_BEV
 SG_ ESP_Verzoeg_EPB_verf  : 124|1@1+ (1.000000,0.000000) [0.000000|1.000000] "" Vector__XXX
 SG_ ESP_Status_Bremsdruck  : 125|1@1+ (1.000000,0.000000) [0.000000|1.000000] "" Vector__XXX
 SG_ ESP_Anforderung_EPB  : 126|2@1+ (1.000000,0.000000) [0.000000|3.000000] "" Vector__XXX
 SG_ ESP_ANB_CM_Rueckk_Umsetz  : 140|1@1+ (1.000000,0.000000) [0.000000|1.000000] "" Vector__XXX
 SG_ ESP_Konsistenz_ACC_Botschaft  : 141|1@1+ (1.000000,0.000000) [0.000000|1.000000] "" Vector__XXX
 SG_ ESP_Stillstandsphase_erschoepft  : 142|1@1+ (1.000000,0.000000) [0.000000|1.000000] "" Vector__XXX
 SG_ ESP_ZT_Rueckk_Umsetz  : 143|1@1+ (1.000000,0.000000) [0.000000|1.000000] "" Vector__XXX
 SG_ ESP_Tuerkontakt_Fahrertuer  : 144|1@1+ (1.000000,0.000000) [0.000000|1.000000] "" Vector__XXX
 SG_ ESP_Abrutschen_Stillstand  : 146|1@1+ (1.000000,0.000000) [0.000000|1.000000] "" Vector__XXX
 SG_ ESP_Fahrer_tritt_ZBR_Schw  : 147|1@1+ (1.000000,0.000000) [0.000000|1.000000] "" Vector__XXX
 SG_ ESP_QBit_v_ref  : 169|1@1+ (1.000000,0.000000) [0.000000|1.000000] "" Vector__XXX
 SG_ ESP_v_ref_Fahrtrichtung  : 170|2@1+ (1.000000,0.000000) [0.000000|3.000000] "" Motor_BEV
 SG_ ESC_Bremsdruckgradient  : 172|8@1+ (10.000000,0.000000) [0.000000|2500.000000] "Unit_BarPerSecon" Vector__XXX
 SG_ ESP_v_ref  : 180|12@1+ (0.125000,0.000000) [0.000000|511.500000] "Unit_KiloMeterPerHour" Airbag Motor_BEV
 SG_ ESC_Hydr_Fkt_aktiv  : 223|2@1+ (1.000000,0.000000) [0.000000|3.000000] "" Vector__XXX
 SG_ ESC_QBit_Fahrerbremswunsch  : 225|1@1+ (1.000000,0.000000) [0.000000|1.000000] "" Motor_BEV
 SG_ ESC_Fahrerbremswunsch  : 226|10@1+ (0.300000,-30.000000) [-30.000000|276.600000] "Unit_Bar" Motor_BEV
 SG_ ESCGeneratorSollMoment  : 236|12@1+ (3.000000,-12279.000000) [-12279.000000|0.000000] "" Motor_BEV
 SG_ ESC_Raddruck_max  : 248|8@1+ (1.000000,0.000000) [0.000000|250.000000] "Unit_Bar" Vector__XXX
 SG_ EPB_QBit_Pedalweg_Kuppl  : 269|1@1+ (1.000000,0.000000) [0.000000|1.000000] "" Vector__XXX
 SG_ EPB_Freig_Verzoeg_Anf  : 271|1@1+ (1.000000,0.000000) [0.000000|1.000000] "" Vector__XXX
 SG_ EPB_Verzoeg_Anf  : 272|8@1+ (0.048000,-7.968000) [-7.968000|4.224000] "Unit_MeterPerSeconSquar" Vector__XXX
 SG_ EPB_Pedalweg_Kuppl  : 288|8@1+ (0.400000,0.000000) [8.000000|92.000000] "Unit_PerCent" Vector__XXX
 SG_ EPB_DAA_Randbed_erf  : 305|1@1+ (1.000000,0.000000) [0.000000|1.000000] "" Vector__XXX
 SG_ EPB_Fehlerstatus_02  : 306|2@1+ (1.000000,0.000000) [0.000000|3.000000] "" Vector__XXX
 SG_ EPB_Schalterposition  : 308|2@1+ (1.000000,0.000000) [0.000000|3.000000] "" Airbag
 SG_ EPB_QBit_Schalterpos  : 310|1@1+ (1.000000,0.000000) [0.000000|1.000000] "" Vector__XXX
 SG_ EPB_Spannkraft  : 312|5@1+ (1.000000,0.000000) [0.000000|29.000000] "Unit_KiloNewto" Vector__XXX
 SG_ EPB_Status_02  : 317|3@1+ (1.000000,0.000000) [0.000000|7.000000] "" Motor_BEV
 SG_ EPB_Status  : 320|2@1+ (1.000000,0.000000) [0.000000|3.000000] "" Vector__XXX
 SG_ ESP_Status_Bremsentemp_02  : 322|2@1+ (1.000000,0.000000) [0.000000|3.000000] "" Motor_BEV

BO_ 252 ESC_51: 48 ICAS1_Gateway
 SG_ ESC_51_CRC  : 0|8@1+ (1.000000,0.000000) [0.000000|255.000000] "" Motor_BEV
 SG_ ESC_51_BZ  : 8|4@1+ (1.000000,0.000000) [0.000000|15.000000] "" Motor_BEV
 SG_ ESC_aktBr_Modus  : 12|2@1+ (1.000000,0.000000) [0.000000|3.000000] "" Vector__XXX
 SG_ ESC_Blending_Solldruck  : 14|10@1+ (0.250000,0.000000) [0.000000|250.000000] "Unit_Bar" Vector__XXX
 SG_ ESC_aktBr_Volumenstrom  : 24|16@1+ (0.007812,-252.000000) [-252.000000|252.000000] "Unit_MilliLiterPerSec" Vector__XXX
 SG_ ESC_EBKV_Kraftblending_Modus  : 40|2@1+ (1.000000,0.000000) [0.000000|3.000000] "" Vector__XXX
 SG_ ESC_Bremsdruck_Modell  : 42|10@1+ (0.250000,0.000000) [0.000000|250.000000] "Unit_Bar" Motor_BEV
 SG_ ESC_Bremsdruck_02  : 52|10@1+ (0.300000,-30.000000) [-30.000000|276.600000] "Unit_Bar" Vector__XXX
 SG_ ESC_QBit_Bremsdruck_02  : 62|1@1+ (1.000000,0.000000) [0.000000|1.000000] "" Vector__XXX
 SG_ ESP_HL_Radgeschw_02  : 64|16@1+ (0.007500,0.000000) [0.000000|491.490000] "Unit_KiloMeterPerHour" Airbag LE1 LE2 Motor_BEV
 SG_ ESP_HR_Radgeschw_02  : 80|16@1+ (0.007500,0.000000) [0.000000|491.490000] "Unit_KiloMeterPerHour" Airbag LE1 LE2 Motor_BEV
 SG_ ESP_VL_Radgeschw_02  : 96|16@1+ (0.007500,0.000000) [0.000000|491.490000] "Unit_KiloMeterPerHour" Airbag LE1 LE2 Motor_BEV
 SG_ ESP_VR_Radgeschw_02  : 112|16@1+ (0.007500,0.000000) [0.000000|491.490000] "Unit_KiloMeterPerHour" Airbag LE1 LE2 Motor_BEV
 SG_ ESP_FZR_uebersteuern  : 128|8@1+ (0.004000,0.000000) [0.000000|1.000000] "" Vector__XXX
 SG_ ESP_FZR_untersteuern  : 136|8@1+ (0.004000,0.000000) [0.000000|1.000000] "" Vector__XXX
 SG_ ESC_Anf_Mindestreku  : 144|1@1+ (1.000000,0.000000) [0.000000|1.000000] "" Motor_BEV
 SG_ ESC_GMV_aktiv  : 145|3@1+ (1.000000,0.000000) [0.000000|7.000000] "" Vector__XXX
 SG_ ESC_GMV_nicht_verfuegbar  : 148|1@1+ (1.000000,0.000000) [0.000000|1.000000] "" Vector__XXX
 SG_ ESC_Status_vRef_Stuetzeingriff  : 149|1@1+ (1.000000,0.000000) [0.000000|1.000000] "" Motor_BEV
 SG_ FDR_Allradverteilung_aktiv  : 150|1@1+ (1.000000,0.000000) [0.000000|1.000000] "" Vector__XXX
 SG_ FDR_Anf_Allradbetrieb  : 151|1@1+ (1.000000,0.000000) [0.000000|1.000000] "" Vector__XXX
 SG_ ESP_HL_Bremsmoment  : 152|8@1+ (20.000000,0.000000) [0.000000|5060.000000] "Unit_NewtoMeter" Motor_BEV
 SG_ ESP_HR_Bremsmoment  : 160|8@1+ (20.000000,0.000000) [0.000000|5060.000000] "Unit_NewtoMeter" Motor_BEV
 SG_ ESP_VR_Bremsmoment  : 168|8@1+ (40.000000,0.000000) [0.000000|10120.000000] "Unit_NewtoMeter" Motor_BEV
 SG_ ESP_VL_Bremsmoment  : 176|8@1+ (40.000000,0.000000) [0.000000|10120.000000] "Unit_NewtoMeter" Motor_BEV
 SG_ ESP_FDR_uebersteuern  : 184|8@1+ (0.004000,0.000000) [0.000000|1.000000] "" Motor_BEV
 SG_ ESP_FDR_untersteuern  : 192|8@1+ (0.004000,0.000000) [0.000000|1.000000] "" Motor_BEV
 SG_ TSMomBegrenzung  : 268|12@1+ (3.000000,-12279.000000) [-12279.000000|0.000000] "" Motor_BEV
 SG_ ESC_Allrad_Anteil_max_sek  : 280|9@1+ (0.200000,0.000000) [0.000000|100.000000] "Unit_PerCent" Motor_BEV
 SG_ ESC_Allrad_Anteil_min_sek  : 289|9@1+ (0.200000,0.000000) [0.000000|100.000000] "Unit_PerCent" Motor_BEV
 SG_ ESC_Status_Eingriff  : 298|2@1+ (1.000000,0.000000) [0.000000|3.000000] "" Motor_BEV
 SG_ ESC_Status_Eingriff_sek  : 300|2@1+ (1.000000,0.000000) [0.000000|3.000000] "" Motor_BEV
 SG_ ESC_MomRad_Eingriff  : 302|13@1+ (3.000000,-12279.000000) [-12279.000000|12279.000000] "Unit_None" Motor_BEV
 SG_ ESC_MomRad_Eingriff_sek  : 315|13@1+ (3.000000,-12279.000000) [-12279.000000|12279.000000] "Unit_None" Motor_BEV
 SG_ ESC_Achsdrehzahl_Max  : 328|14@1+ (0.400000,-800.000000) [-800.000000|5752.400000] "Unit_MinutInver" Motor_BEV
 SG_ ESC_Achsdrehzahl_Min  : 342|14@1+ (0.400000,-800.000000) [-800.000000|5752.400000] "Unit_MinutInver" Motor_BEV
 SG_ ESC_Achsdrehzahl_Max_sek  : 356|14@1+ (0.400000,-800.000000) [-800.000000|5752.400000] "Unit_MinutInver" Motor_BEV
 SG_ ESC_Achsdrehzahl_Min_sek  : 370|14@1+ (0.400000,-800.000000) [-800.000000|5752.400000] "Unit_MinutInver" Motor_BEV

BO_ 2463978647 ESC_52: 16 ICAS1_Gateway
 SG_ ESP_ACC_LDE  : 12|1@1+ (1.000000,0.000000) [0.000000|1.000000] "" Vector__XXX
 SG_ ESP_Allrad_Antrieb  : 13|1@1+ (1.000000,0.000000) [0.000000|1.000000] "" Vector__XXX
 SG_ ESP_Codierung_ADS  : 14|2@1+ (1.000000,0.000000) [0.000000|3.000000] "" Vector__XXX
 SG_ ESP_RTA_HL  : 16|8@1+ (0.048828,-6.201170) [-6.201170|6.152346] "Unit_PerCent" Motor_BEV
 SG_ ESP_RTA_HR  : 24|8@1+ (0.048828,-6.201170) [-6.201170|6.152346] "Unit_PerCent" Motor_BEV
 SG_ ESP_RTA_VR  : 32|8@1+ (0.048828,-6.201170) [-6.201170|6.152346] "Unit_PerCent" Motor_BEV
 SG_ OBD_Fehler_Radsensor_HL  : 40|4@1+ (1.000000,0.000000) [0.000000|15.000000] "" Motor_BEV
 SG_ OBD_Fehler_Radsensor_HR  : 44|4@1+ (1.000000,0.000000) [0.000000|15.000000] "" Motor_BEV
 SG_ OBD_Fehler_Radsensor_VL  : 48|4@1+ (1.000000,0.000000) [0.000000|15.000000] "" Motor_BEV
 SG_ OBD_Fehler_Radsensor_VR  : 52|4@1+ (1.000000,0.000000) [0.000000|15.000000] "" Motor_BEV
 SG_ ESP_Qualifizierung_Antriebsart  : 56|1@1+ (1.000000,0.000000) [0.000000|1.000000] "" Vector__XXX
 SG_ ESP_Offroad_Modus  : 57|1@1+ (1.000000,0.000000) [0.000000|1.000000] "" Vector__XXX
 SG_ ESP_MKB_ausloesbar  : 58|1@1+ (1.000000,0.000000) [0.000000|1.000000] "" Vector__XXX
 SG_ ESP_Stat_FallBack_eBKV  : 59|1@1+ (1.000000,0.000000) [0.000000|1.000000] "" Vector__XXX
 SG_ ESP_CM_Variante  : 60|1@1+ (1.000000,0.000000) [0.000000|1.000000] "" Vector__XXX
 SG_ ESP_OBD_Status  : 61|1@1+ (1.000000,0.000000) [0.000000|1.000000] "" Motor_BEV
 SG_ ESP_Rollenmodus_Deaktivieren  : 62|1@1+ (1.000000,0.000000) [0.000000|1.000000] "" Motor_BEV
 SG_ ESP_nachtr_Stopp_Anf  : 63|1@1+ (1.000000,0.000000) [0.000000|1.000000] "" Vector__XXX

BO_ 2527679683 ESC_ASM_01: 8 ICAS1_Gateway
 SG_ ESC_ASM_Ereignis  : 0|8@1+ (1.000000,0.000000) [1.000000|254.000000] "Unit_None" Airbag
 SG_ ESC_ASM_Zeitstempel  : 8|8@1+ (0.080000,0.000000) [0.000000|20.320000] "Unit_Secon" Airbag
 SG_ ESC_ASM_Data_1  : 16|8@1+ (1.000000,0.000000) [0.000000|255.000000] "" Airbag
 SG_ ESC_ASM_Data_2  : 24|8@1+ (1.000000,0.000000) [0.000000|255.000000] "" Airbag
 SG_ ESC_ASM_Data_3  : 32|8@1+ (1.000000,0.000000) [0.000000|255.000000] "" Airbag
 SG_ ESC_ASM_Data_4  : 40|8@1+ (1.000000,0.000000) [0.000000|255.000000] "" Airbag
 SG_ ESC_ASM_Data_5  : 48|8@1+ (1.000000,0.000000) [0.000000|255.000000] "" Airbag
 SG_ ESC_ASM_Data_6  : 56|8@1+ (1.000000,0.000000) [0.000000|255.000000] "" Airbag

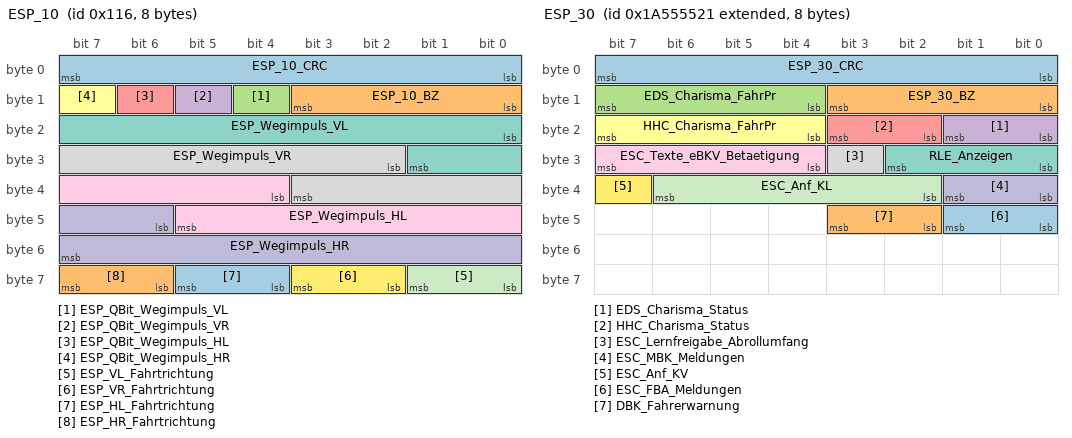
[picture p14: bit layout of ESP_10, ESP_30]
BO_ 278 ESP_10: 8 ICAS1_Gateway
 SG_ ESP_10_CRC  : 0|8@1+ (1.000000,0.000000) [0.000000|255.000000] "" Vector__XXX
 SG_ ESP_10_BZ  : 8|4@1+ (1.000000,0.000000) [0.000000|15.000000] "" Vector__XXX
 SG_ ESP_QBit_Wegimpuls_VL  : 12|1@1+ (1.000000,0.000000) [0.000000|1.000000] "" Motor_BEV
 SG_ ESP_QBit_Wegimpuls_VR  : 13|1@1+ (1.000000,0.000000) [0.000000|1.000000] "" Motor_BEV
 SG_ ESP_QBit_Wegimpuls_HL  : 14|1@1+ (1.000000,0.000000) [0.000000|1.000000] "" Motor_BEV
 SG_ ESP_QBit_Wegimpuls_HR  : 15|1@1+ (1.000000,0.000000) [0.000000|1.000000] "" Motor_BEV
 SG_ ESP_Wegimpuls_VL  : 16|10@1+ (1.000000,0.000000) [0.000000|1000.000000] "" Motor_BEV
 SG_ ESP_Wegimpuls_VR  : 26|10@1+ (1.000000,0.000000) [0.000000|1000.000000] "" Motor_BEV
 SG_ ESP_Wegimpuls_HL  : 36|10@1+ (1.000000,0.000000) [0.000000|1000.000000] "" Motor_BEV
 SG_ ESP_Wegimpuls_HR  : 46|10@1+ (1.000000,0.000000) [0.000000|1000.000000] "" Motor_BEV
 SG_ ESP_VL_Fahrtrichtung  : 56|2@1+ (1.000000,0.000000) [0.000000|3.000000] "" Motor_BEV
 SG_ ESP_VR_Fahrtrichtung  : 58|2@1+ (1.000000,0.000000) [0.000000|3.000000] "" Motor_BEV
 SG_ ESP_HL_Fahrtrichtung  : 60|2@1+ (1.000000,0.000000) [0.000000|3.000000] "" Motor_BEV
 SG_ ESP_HR_Fahrtrichtung  : 62|2@1+ (1.000000,0.000000) [0.000000|3.000000] "" Motor_BEV

BO_ 1629 ESP_20: 8 ICAS1_Gateway
 SG_ ESP_20_CRC  : 0|8@1+ (1.000000,0.000000) [0.000000|255.000000] "" Vector__XXX
 SG_ ESP_20_BZ  : 8|4@1+ (1.000000,0.000000) [0.000000|15.000000] "" Vector__XXX
 SG_ BR_Systemart  : 12|2@1+ (1.000000,0.000000) [0.000000|3.000000] "" Vector__XXX
 SG_ ESP_SpannungsAnf_02  : 14|2@1+ (1.000000,0.000000) [0.000000|3.000000] "" Vector__XXX
 SG_ ESP_Zaehnezahl  : 16|8@1+ (1.000000,0.000000) [0.000000|255.000000] "" Vector__XXX
 SG_ ESP_Charisma_FahrPr  : 24|4@1+ (1.000000,0.000000) [0.000000|15.000000] "" Vector__XXX
 SG_ ESP_Charisma_Status  : 28|2@1+ (1.000000,0.000000) [0.000000|3.000000] "" Vector__XXX
 SG_ ESP_Wiederstart_Anz_01  : 30|1@1+ (1.000000,0.000000) [0.000000|1.000000] "" Vector__XXX
 SG_ ESP_Wiederstart_Anz_02  : 31|1@1+ (1.000000,0.000000) [0.000000|1.000000] "" Vector__XXX
 SG_ ESP_Wiederstart_Anz_03  : 32|1@1+ (1.000000,0.000000) [0.000000|1.000000] "" Vector__XXX
 SG_ ESP_Wiederstart_Anz_04  : 33|1@1+ (1.000000,0.000000) [0.000000|1.000000] "" Vector__XXX
 SG_ ESP_Stoppverbot_Anz_01  : 34|1@1+ (1.000000,0.000000) [0.000000|1.000000] "" Vector__XXX
 SG_ ESP_Stoppverbot_Anz_02  : 35|1@1+ (1.000000,0.000000) [0.000000|1.000000] "" Vector__XXX
 SG_ ESP_Stoppverbot_Anz_03  : 36|1@1+ (1.000000,0.000000) [0.000000|1.000000] "" Vector__XXX
 SG_ ESP_Stoppverbot_Anz_04  : 37|1@1+ (1.000000,0.000000) [0.000000|1.000000] "" Vector__XXX
 SG_ ESP_Stoppverbot_Anz_05  : 38|1@1+ (1.000000,0.000000) [0.000000|1.000000] "" Vector__XXX
 SG_ ESP_Stoppverbot_Anz_06  : 39|1@1+ (1.000000,0.000000) [0.000000|1.000000] "" Vector__XXX
 SG_ ESP_Stoppverbot_Anz_07  : 40|1@1+ (1.000000,0.000000) [0.000000|1.000000] "" Vector__XXX
 SG_ ESP_Stoppverbot_Anz_Std  : 41|1@1+ (1.000000,0.000000) [0.000000|1.000000] "" Vector__XXX
 SG_ ESP_Dachrelingsensor  : 42|2@1+ (1.000000,0.000000) [0.000000|3.000000] "" Vector__XXX
 SG_ ESP_Stoppverbot_Anz_08  : 44|1@1+ (1.000000,0.000000) [0.000000|1.000000] "" Vector__XXX
 SG_ HDC_Charisma_FahrPr  : 45|4@1+ (1.000000,0.000000) [0.000000|15.000000] "" Vector__XXX
 SG_ HDC_Charisma_Status  : 49|2@1+ (1.000000,0.000000) [0.000000|3.000000] "" Vector__XXX
 SG_ BR_QBit_Reifenumfang  : 51|1@1+ (1.000000,0.000000) [0.000000|1.000000] "" LE1 LE2
 SG_ BR_Reifenumfang  : 52|12@1+ (1.000000,0.000000) [0.000000|4095.000000] "Unit_MilliMeter" LE1 LE2

BO_ 253 ESP_21: 8 ICAS1_Gateway
 SG_ ESP_21_CRC  : 0|8@1+ (1.000000,0.000000) [0.000000|255.000000] "" Airbag LE1 LE2 Motor_BEV
 SG_ ESP_21_BZ  : 8|4@1+ (1.000000,0.000000) [0.000000|15.000000] "" Airbag LE1 LE2 Motor_BEV
 SG_ BR_Eingriffsmoment  : 12|10@1+ (1.000000,-509.000000) [-509.000000|509.000000] "" Vector__XXX
 SG_ ESP_PLA_Bremseingriff  : 22|1@1+ (1.000000,0.000000) [0.000000|1.000000] "" Vector__XXX
 SG_ ESP_Diagnose  : 23|1@1+ (1.000000,0.000000) [0.000000|1.000000] "" Vector__XXX
 SG_ ESC_Reku_Freigabe  : 24|1@1+ (1.000000,0.000000) [0.000000|1.000000] "" Motor_BEV
 SG_ ESC_v_Signal_Qualifier_High_Low  : 25|3@1+ (1.000000,0.000000) [0.000000|7.000000] "" Airbag
 SG_ ESP_Vorsteuerung  : 28|1@1+ (1.000000,0.000000) [0.000000|1.000000] "" Motor_BEV
 SG_ ESP_AWV3_Brems_aktiv  : 29|1@1+ (1.000000,0.000000) [0.000000|1.000000] "" Vector__XXX
 SG_ OBD_Schlechtweg  : 30|1@1+ (1.000000,0.000000) [0.000000|1.000000] "" Vector__XXX
 SG_ OBD_QBit_Schlechtweg  : 31|1@1+ (1.000000,0.000000) [0.000000|1.000000] "" Vector__XXX
 SG_ ESP_v_Signal  : 32|16@1+ (0.010000,0.000000) [0.000000|655.320000] "Unit_KiloMeterPerHour" Airbag LE1 LE2 Motor_BEV
 SG_ ASR_Tastung_passiv  : 48|1@1+ (1.000000,0.000000) [0.000000|1.000000] "" Airbag Motor_BEV
 SG_ ESP_Tastung_passiv  : 49|1@1+ (1.000000,0.000000) [0.000000|1.000000] "" Airbag Motor_BEV
 SG_ ESP_Systemstatus  : 50|1@1+ (1.000000,0.000000) [0.000000|1.000000] "" Motor_BEV
 SG_ ASR_Schalteingriff  : 51|2@1+ (1.000000,0.000000) [0.000000|3.000000] "" Vector__XXX
 SG_ ESP_Haltebestaetigung  : 53|1@1+ (1.000000,0.000000) [0.000000|1.000000] "" Vector__XXX
 SG_ ESP_MKB_Abbruch_Geschw  : 54|1@1+ (1.000000,0.000000) [0.000000|1.000000] "" Vector__XXX
 SG_ ESP_QBit_v_Signal  : 55|1@1+ (1.000000,0.000000) [0.000000|1.000000] "" LE1 LE2 Motor_BEV
 SG_ ABS_Bremsung  : 56|1@1+ (1.000000,0.000000) [0.000000|1.000000] "" Airbag Motor_BEV
 SG_ ASR_Anf  : 57|1@1+ (1.000000,0.000000) [0.000000|1.000000] "" Vector__XXX
 SG_ MSR_Anf  : 58|1@1+ (1.000000,0.000000) [0.000000|1.000000] "" Vector__XXX
 SG_ EBV_Eingriff  : 59|1@1+ (1.000000,0.000000) [0.000000|1.000000] "" Vector__XXX
 SG_ EDS_Eingriff  : 60|1@1+ (1.000000,0.000000) [0.000000|1.000000] "" Motor_BEV
 SG_ ESP_Eingriff  : 61|1@1+ (1.000000,0.000000) [0.000000|1.000000] "" Airbag Motor_BEV
 SG_ ESP_ASP  : 62|1@1+ (1.000000,0.000000) [0.000000|1.000000] "" Vector__XXX
 SG_ ESP_Anhaltevorgang_ACC_aktiv  : 63|1@1+ (1.000000,0.000000) [0.000000|1.000000] "" Vector__XXX

BO_ 795 ESP_24: 8 ICAS1_Gateway
 SG_ ESP_24_CRC  : 0|8@1+ (1.000000,0.000000) [0.000000|255.000000] "" Vector__XXX
 SG_ ESP_24_BZ  : 8|4@1+ (1.000000,0.000000) [0.000000|15.000000] "" Vector__XXX
 SG_ ESP_Lampe  : 12|1@1+ (1.000000,0.000000) [0.000000|1.000000] "" Motor_BEV
 SG_ ABS_Lampe  : 13|1@1+ (1.000000,0.000000) [0.000000|1.000000] "" Vector__XXX
 SG_ BK_Lampe_02  : 14|2@1+ (1.000000,0.000000) [0.000000|3.000000] "" Vector__XXX
 SG_ TC_Lampe  : 16|1@1+ (1.000000,0.000000) [0.000000|1.000000] "" Vector__XXX
 SG_ ESP_m_Raddrehz  : 17|15@1+ (0.002000,0.000000) [0.000000|65.278000] "Unit_Hertz" Vector__XXX
 SG_ ESP_Textanzeigen_03  : 32|5@1+ (1.000000,0.000000) [0.000000|31.000000] "" Vector__XXX
 SG_ ESP_Meldungen  : 37|3@1+ (1.000000,0.000000) [0.000000|7.000000] "" Vector__XXX
 SG_ ESP_Wegimp_VA  : 40|11@1+ (1.000000,0.000000) [0.000000|2047.000000] "" Vector__XXX
 SG_ ESP_Fehlerstatus_Wegimp  : 51|1@1+ (1.000000,0.000000) [0.000000|1.000000] "" Vector__XXX
 SG_ ESP_Wegimp_Ueberlauf  : 52|1@1+ (1.000000,0.000000) [0.000000|1.000000] "" Vector__XXX
 SG_ ESP_QBit_Wegimp_VA  : 53|1@1+ (1.000000,0.000000) [0.000000|1.000000] "" Vector__XXX
 SG_ ESP_HDC_FktLampe  : 54|1@1+ (1.000000,0.000000) [0.000000|1.000000] "" Vector__XXX
 SG_ ESP_Off_Lampe  : 55|1@1+ (1.000000,0.000000) [0.000000|1.000000] "" Airbag
 SG_ ESP_HDC_Regelgeschw  : 56|7@1+ (0.320000,0.000000) [0.320000|39.680000] "Unit_KiloMeterPerHour" Vector__XXX
 SG_ ESP_BKV_Warnung  : 63|1@1+ (1.000000,0.000000) [0.000000|1.000000] "" Vector__XXX

BO_ 2589283617 ESP_30: 8 ICAS1_Gateway
 SG_ ESP_30_CRC  : 0|8@1+ (1.000000,0.000000) [0.000000|255.000000] "" Vector__XXX
 SG_ ESP_30_BZ  : 8|4@1+ (1.000000,0.000000) [0.000000|15.000000] "" Vector__XXX
 SG_ EDS_Charisma_FahrPr  : 12|4@1+ (1.000000,0.000000) [0.000000|15.000000] "" Vector__XXX
 SG_ EDS_Charisma_Status  : 16|2@1+ (1.000000,0.000000) [0.000000|3.000000] "" Vector__XXX
 SG_ HHC_Charisma_Status  : 18|2@1+ (1.000000,0.000000) [0.000000|3.000000] "" Vector__XXX
 SG_ HHC_Charisma_FahrPr  : 20|4@1+ (1.000000,0.000000) [0.000000|15.000000] "" Vector__XXX
 SG_ RLE_Anzeigen  : 24|3@1+ (1.000000,0.000000) [0.000000|7.000000] "" Vector__XXX
 SG_ ESC_Lernfreigabe_Abrollumfang  : 27|1@1+ (1.000000,0.000000) [0.000000|1.000000] "" Vector__XXX
 SG_ ESC_Texte_eBKV_Betaetigung  : 28|4@1+ (1.000000,0.000000) [0.000000|15.000000] "" Vector__XXX
 SG_ ESC_MBK_Meldungen  : 32|2@1+ (1.000000,0.000000) [0.000000|3.000000] "" Vector__XXX
 SG_ ESC_Anf_KL  : 34|5@1+ (3.225806,0.000000) [0.000000|100.000000] "Unit_PerCent" Motor_BEV
 SG_ ESC_Anf_KV  : 39|1@1+ (1.000000,0.000000) [0.000000|1.000000] "" Motor_BEV
 SG_ ESC_FBA_Meldungen  : 40|2@1+ (1.000000,0.000000) [0.000000|3.000000] "" Vector__XXX
 SG_ DBK_Fahrerwarnung  : 42|2@1+ (1.000000,0.000000) [0.000000|3.000000] "" Vector__XXX

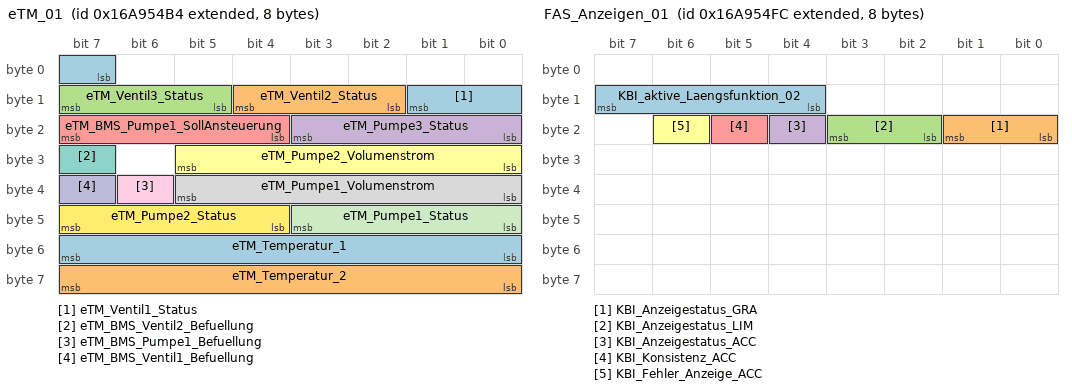
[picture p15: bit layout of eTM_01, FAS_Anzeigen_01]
BO_ 2527679668 eTM_01: 8 Motor_BEV
 SG_ eTM_Ventil1_Status  : 7|3@1+ (1.000000,0.000000) [0.000000|7.000000] "" ICAS1_Gateway
 SG_ eTM_Ventil2_Status  : 10|3@1+ (1.000000,0.000000) [0.000000|7.000000] "" ICAS1_Gateway
 SG_ eTM_Ventil3_Status  : 13|3@1+ (1.000000,0.000000) [0.000000|7.000000] "" ICAS1_Gateway
 SG_ eTM_Pumpe3_Status  : 16|4@1+ (10.000000,0.000000) [0.000000|130.000000] "Unit_PerCent" ICAS1_Gateway
 SG_ eTM_BMS_Pumpe1_SollAnsteuerung  : 20|4@1+ (10.000000,0.000000) [0.000000|130.000000] "Unit_PerCent" ICAS1_Gateway
 SG_ eTM_Pumpe2_Volumenstrom  : 24|6@1+ (0.500000,0.000000) [0.000000|30.500000] "Unit_LiterPerMinut" ICAS1_Gateway LE1 LE2
 SG_ eTM_BMS_Ventil2_Befuellung  : 31|1@1+ (1.000000,0.000000) [0.000000|1.000000] "" ICAS1_Gateway
 SG_ eTM_Pumpe1_Volumenstrom  : 32|6@1+ (0.500000,0.000000) [0.000000|30.500000] "Unit_LiterPerMinut" ICAS1_Gateway LE1 LE2
 SG_ eTM_BMS_Pumpe1_Befuellung  : 38|1@1+ (1.000000,0.000000) [0.000000|1.000000] "" ICAS1_Gateway
 SG_ eTM_BMS_Ventil1_Befuellung  : 39|1@1+ (1.000000,0.000000) [0.000000|1.000000] "" ICAS1_Gateway
 SG_ eTM_Pumpe1_Status  : 40|4@1+ (10.000000,0.000000) [0.000000|130.000000] "Unit_PerCent" ICAS1_Gateway LE1 LE2
 SG_ eTM_Pumpe2_Status  : 44|4@1+ (10.000000,0.000000) [0.000000|130.000000] "Unit_PerCent" ICAS1_Gateway LE1 LE2
 SG_ eTM_Temperatur_1  : 48|8@1+ (0.750000,-40.000000) [-40.000000|149.750000] "Unit_DegreCelsi" ICAS1_Gateway LE1 LE2
 SG_ eTM_Temperatur_2  : 56|8@1+ (0.750000,-40.000000) [-40.000000|149.750000] "Unit_DegreCelsi" ICAS1_Gateway LE1 LE2

BO_ 2527679740 FAS_Anzeigen_01: 8 ICAS1_KommunikationsServer
 SG_ KBI_aktive_Laengsfunktion_02  : 12|4@1+ (1.000000,0.000000) [0.000000|15.000000] "" Motor_BEV
 SG_ KBI_Anzeigestatus_GRA  : 16|2@1+ (1.000000,0.000000) [0.000000|3.000000] "" Motor_BEV
 SG_ KBI_Anzeigestatus_LIM  : 18|2@1+ (1.000000,0.000000) [0.000000|3.000000] "" Motor_BEV
 SG_ KBI_Anzeigestatus_ACC  : 20|1@1+ (1.000000,0.000000) [0.000000|1.000000] "" Vector__XXX
 SG_ KBI_Konsistenz_ACC  : 21|1@1+ (1.000000,0.000000) [0.000000|1.000000] "" Vector__XXX
 SG_ KBI_Fehler_Anzeige_ACC  : 22|1@1+ (1.000000,0.000000) [0.000000|1.000000] "" Vector__XXX

BO_ 2589283684 FoD_01: 8 ICAS1_Gateway
 SG_ GRA_FoD_Status  : 58|2@1+ (1.000000,0.000000) [0.000000|3.000000] "" Vector__XXX
 SG_ FoD_Transmission_Info  : 60|2@1+ (1.000000,0.000000) [0.000000|3.000000] "" Motor_BEV

BO_ 2549875574 FoD_MO_01_Req: 8 ICAS1_Gateway
 SG_ FoD_MO_01_Req_Data  : 0|64@1+ (1.000000,0.000000) [0.000000|18446744073709551616.000000] "" Motor_BEV

BO_ 2550006646 FoD_MO_01_Resp: 8 Motor_BEV
 SG_ FoD_MO_01_Resp_Data  : 0|64@1+ (1.000000,0.000000) [0.000000|18446744073709551616.000000] "" ICAS1_Gateway

BO_ 987 Gateway_72: 8 ICAS1_Gateway
 SG_ BCM_01_alt  : 0|1@1+ (1.000000,0.000000) [0.000000|1.000000] "" Airbag
 SG_ SMLS_01_alt  : 1|1@1+ (1.000000,0.000000) [0.000000|1.000000] "" Vector__XXX
 SG_ ZV_02_alt  : 2|1@1+ (1.000000,0.000000) [0.000000|1.000000] "" Vector__XXX
 SG_ Wischer_01_alt  : 3|1@1+ (1.000000,0.000000) [0.000000|1.000000] "" Vector__XXX
 SG_ Anhaenger_01_alt  : 4|1@1+ (1.000000,0.000000) [0.000000|1.000000] "" Airbag
 SG_ Klima_Sensor_02_alt  : 5|1@1+ (1.000000,0.000000) [0.000000|1.000000] "" Vector__XXX
 SG_ Verdeck_01_alt  : 6|1@1+ (1.000000,0.000000) [0.000000|1.000000] "" Vector__XXX
 SG_ Klima_11_alt  : 7|1@1+ (1.000000,0.000000) [0.000000|1.000000] "" Vector__XXX
 SG_ WFS_01_alt  : 8|1@1+ (1.000000,0.000000) [0.000000|1.000000] "" Vector__XXX
 SG_ Licht_Anf_01_alt  : 9|1@1+ (1.000000,0.000000) [0.000000|1.000000] "" Vector__XXX
 SG_ ZV_verriegelt_extern_soll  : 10|1@1+ (1.000000,0.000000) [0.000000|1.000000] "" Vector__XXX
 SG_ BH_Lichthupe  : 11|1@1+ (1.000000,0.000000) [0.000000|1.000000] "" Vector__XXX
 SG_ WFS_Klemmenfreigabe  : 12|1@1+ (1.000000,0.000000) [0.000000|1.000000] "" Vector__XXX
 SG_ ZV_Tankklappe_offen  : 13|1@1+ (1.000000,0.000000) [0.000000|1.000000] "" Vector__XXX
 SG_ AAG_Anhaenger_abgesteckt  : 14|1@1+ (1.000000,0.000000) [0.000000|1.000000] "" Vector__XXX
 SG_ BCM1_LDS_Stellung  : 15|3@1+ (1.000000,0.000000) [0.000000|7.000000] "" Vector__XXX
 SG_ VS_Verdeck_Anf  : 18|1@1+ (1.000000,0.000000) [0.000000|1.000000] "" Vector__XXX
 SG_ VS_VD_entriegelt  : 19|1@1+ (1.000000,0.000000) [0.000000|1.000000] "" Vector__XXX
 SG_ ZV_HFS_offen  : 20|1@1+ (1.000000,0.000000) [0.000000|1.000000] "" Vector__XXX
 SG_ ZV_HBFS_offen  : 21|1@1+ (1.000000,0.000000) [0.000000|1.000000] "" Vector__XXX
 SG_ VS_VD_offen_ver  : 22|1@1+ (1.000000,0.000000) [0.000000|1.000000] "" Vector__XXX
 SG_ VS_VD_zu_ver  : 23|1@1+ (1.000000,0.000000) [0.000000|1.000000] "" Vector__XXX
 SG_ ZV_BT_offen  : 24|1@1+ (1.000000,0.000000) [0.000000|1.000000] "" Vector__XXX
 SG_ BCM1_Rueckfahrlicht_Schalter  : 25|1@1+ (1.000000,0.000000) [0.000000|1.000000] "" Airbag Motor_BEV
 SG_ ZV_FT_offen  : 26|1@1+ (1.000000,0.000000) [0.000000|1.000000] "" Vector__XXX
 SG_ Wischer_vorne_aktiv  : 27|1@1+ (1.000000,0.000000) [0.000000|1.000000] "" Vector__XXX
 SG_ AAG_Anhaenger_erkannt  : 28|1@1+ (1.000000,0.000000) [0.000000|1.000000] "" Airbag
 SG_ BCM1_MH_Schalter  : 29|1@1+ (1.000000,0.000000) [0.000000|1.000000] "" Vector__XXX
 SG_ ZV_HD_offen  : 30|1@1+ (1.000000,0.000000) [0.000000|1.000000] "" Vector__XXX
 SG_ Waschen_vorne_aktiv  : 31|1@1+ (1.000000,0.000000) [0.000000|1.000000] "" Vector__XXX
 SG_ KL_Thermomanagement  : 32|2@1+ (1.000000,0.000000) [0.000000|3.000000] "" Vector__XXX
 SG_ WFS_Schluessel_Fahrberecht  : 34|4@1+ (1.000000,0.000000) [0.000000|15.000000] "" Vector__XXX
 SG_ BCM_Rueckfahrlicht_Anf  : 38|1@1+ (1.000000,0.000000) [0.000000|1.000000] "" Vector__XXX
 SG_ WWSs_01_alt  : 39|1@1+ (1.000000,0.000000) [0.000000|1.000000] "" Vector__XXX
 SG_ BCM_Tankklappensteller_Fehler  : 40|1@1+ (1.000000,0.000000) [0.000000|1.000000] "" Vector__XXX
 SG_ AAG_LED_aktiv  : 41|1@1+ (1.000000,0.000000) [0.000000|1.000000] "" Vector__XXX
 SG_ ZV_verriegelt_soll  : 42|2@1+ (1.000000,0.000000) [0.000000|3.000000] "" Vector__XXX
 SG_ ZV_Schluessel_Zugang  : 44|4@1+ (1.000000,0.000000) [0.000000|15.000000] "" Vector__XXX
 SG_ WFS_ID_Geb_autorisiert_in_Kl15  : 48|1@1+ (1.000000,0.000000) [0.000000|1.000000] "" Vector__XXX
 SG_ BH_Fernlicht  : 49|1@1+ (1.000000,0.000000) [0.000000|1.000000] "" Vector__XXX
 SG_ BH_Blinker_li  : 50|1@1+ (1.000000,0.000000) [0.000000|1.000000] "" Vector__XXX
 SG_ BH_Blinker_re  : 51|1@1+ (1.000000,0.000000) [0.000000|1.000000] "" Vector__XXX
 SG_ BCM1_OBD_FStatus_ATemp  : 52|4@1+ (1.000000,0.000000) [0.000000|15.000000] "" Vector__XXX
 SG_ BCM1_Aussen_Temp_ungef  : 56|8@1+ (0.500000,-50.000000) [-50.000000|76.000000] "Unit_DegreCelsi" Vector__XXX

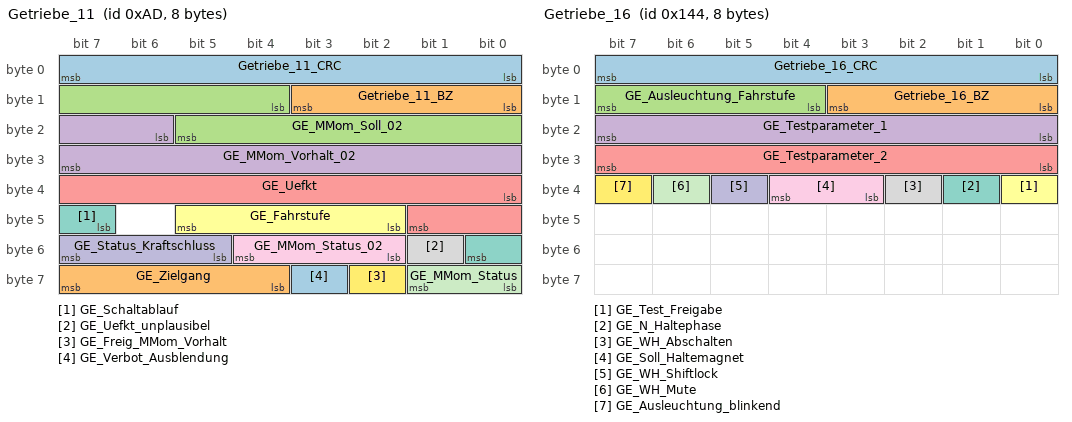
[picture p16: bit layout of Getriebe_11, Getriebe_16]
BO_ 173 Getriebe_11: 8 Motor_BEV
 SG_ Getriebe_11_CRC  : 0|8@1+ (1.000000,0.000000) [0.000000|255.000000] "" ICAS1_Gateway
 SG_ Getriebe_11_BZ  : 8|4@1+ (1.000000,0.000000) [0.000000|15.000000] "" ICAS1_Gateway
 SG_ GE_MMom_Soll_02  : 12|10@1+ (1.000000,-509.000000) [-509.000000|509.000000] "" ICAS1_Gateway
 SG_ GE_MMom_Vorhalt_02  : 22|10@1+ (1.000000,-509.000000) [-509.000000|509.000000] "" ICAS1_Gateway
 SG_ GE_Uefkt  : 32|10@1+ (0.100000,0.000000) [0.000000|102.200000] "" ICAS1_Gateway
 SG_ GE_Fahrstufe  : 42|4@1+ (1.000000,0.000000) [0.000000|15.000000] "" ICAS1_Gateway
 SG_ GE_Schaltablauf  : 47|2@1+ (1.000000,0.000000) [0.000000|3.000000] "" ICAS1_Gateway
 SG_ GE_Uefkt_unplausibel  : 49|1@1+ (1.000000,0.000000) [0.000000|1.000000] "" ICAS1_Gateway
 SG_ GE_MMom_Status_02  : 50|3@1+ (1.000000,0.000000) [0.000000|7.000000] "" ICAS1_Gateway
 SG_ GE_Status_Kraftschluss  : 53|3@1+ (1.000000,0.000000) [0.000000|7.000000] "" ICAS1_Gateway
 SG_ GE_MMom_Status  : 56|2@1+ (1.000000,0.000000) [0.000000|3.000000] "" ICAS1_Gateway
 SG_ GE_Freig_MMom_Vorhalt  : 58|1@1+ (1.000000,0.000000) [0.000000|1.000000] "" ICAS1_Gateway
 SG_ GE_Verbot_Ausblendung  : 59|1@1+ (1.000000,0.000000) [0.000000|1.000000] "" ICAS1_Gateway
 SG_ GE_Zielgang  : 60|4@1+ (1.000000,0.000000) [0.000000|15.000000] "" ICAS1_Gateway

BO_ 324 Getriebe_16: 8 Motor_BEV
 SG_ Getriebe_16_CRC  : 0|8@1+ (1.000000,0.000000) [0.000000|255.000000] "" ICAS1_Gateway Schaltbetaetigung
 SG_ Getriebe_16_BZ  : 8|4@1+ (1.000000,0.000000) [0.000000|15.000000] "" ICAS1_Gateway Schaltbetaetigung
 SG_ GE_Ausleuchtung_Fahrstufe  : 12|4@1+ (1.000000,0.000000) [0.000000|15.000000] "" ICAS1_Gateway Schaltbetaetigung
 SG_ GE_Testparameter_1  : 16|8@1+ (1.000000,0.000000) [0.000000|255.000000] "" ICAS1_Gateway Schaltbetaetigung
 SG_ GE_Testparameter_2  : 24|8@1+ (1.000000,0.000000) [0.000000|255.000000] "" ICAS1_Gateway Schaltbetaetigung
 SG_ GE_Test_Freigabe  : 32|1@1+ (1.000000,0.000000) [0.000000|1.000000] "" ICAS1_Gateway Schaltbetaetigung
 SG_ GE_N_Haltephase  : 33|1@1+ (1.000000,0.000000) [0.000000|1.000000] "" ICAS1_Gateway Schaltbetaetigung
 SG_ GE_WH_Abschalten  : 34|1@1+ (1.000000,0.000000) [0.000000|1.000000] "" ICAS1_Gateway Schaltbetaetigung
 SG_ GE_Soll_Haltemagnet  : 35|2@1+ (1.000000,0.000000) [0.000000|3.000000] "" ICAS1_Gateway Schaltbetaetigung
 SG_ GE_WH_Shiftlock  : 37|1@1+ (1.000000,0.000000) [0.000000|1.000000] "" ICAS1_Gateway Schaltbetaetigung
 SG_ GE_WH_Mute  : 38|1@1+ (1.000000,0.000000) [0.000000|1.000000] "" ICAS1_Gateway Schaltbetaetigung
 SG_ GE_Ausleuchtung_blinkend  : 39|1@1+ (1.000000,0.000000) [0.000000|1.000000] "" ICAS1_Gateway Schaltbetaetigung

BO_ 299 GRA_ACC_01: 8 ICAS1_Gateway
 SG_ GRA_ACC_01_CRC  : 0|8@1+ (1.000000,0.000000) [0.000000|255.000000] "" Motor_BEV
 SG_ GRA_ACC_01_BZ  : 8|4@1+ (1.000000,0.000000) [0.000000|15.000000] "" Motor_BEV
 SG_ GRA_Hauptschalter  : 12|1@1+ (1.000000,0.000000) [0.000000|1.000000] "" Motor_BEV
 SG_ GRA_Abbrechen  : 13|1@1+ (1.000000,0.000000) [0.000000|1.000000] "" Motor_BEV
 SG_ GRA_Typ_Hauptschalter  : 14|1@1+ (1.000000,0.000000) [0.000000|1.000000] "" Motor_BEV
 SG_ GRA_Limiter  : 15|1@1+ (1.000000,0.000000) [0.000000|1.000000] "" Motor_BEV
 SG_ GRA_Tip_Setzen  : 16|1@1+ (1.000000,0.000000) [0.000000|1.000000] "" Motor_BEV
 SG_ GRA_Tip_Hoch  : 17|1@1+ (1.000000,0.000000) [0.000000|1.000000] "" Motor_BEV
 SG_ GRA_Tip_Runter  : 18|1@1+ (1.000000,0.000000) [0.000000|1.000000] "" Motor_BEV
 SG_ GRA_Tip_Wiederaufnahme  : 19|1@1+ (1.000000,0.000000) [0.000000|1.000000] "" Motor_BEV
 SG_ GRA_Verstellung_Zeitluecke  : 20|2@1+ (1.000000,0.000000) [0.000000|3.000000] "" Vector__XXX
 SG_ GRA_Codierung  : 22|2@1+ (1.000000,0.000000) [0.000000|3.000000] "" Motor_BEV
 SG_ GRA_Fehler  : 24|1@1+ (1.000000,0.000000) [0.000000|1.000000] "" Motor_BEV
 SG_ GRA_LIM_Taste_verfuegbar  : 25|1@1+ (1.000000,0.000000) [0.000000|1.000000] "" Motor_BEV
 SG_ GRA_Tip_Stufe_2  : 26|1@1+ (1.000000,0.000000) [0.000000|1.000000] "" Motor_BEV
 SG_ GRA_Typ_Bedienteil  : 27|3@1+ (1.000000,0.000000) [0.000000|7.000000] "" Motor_BEV
 SG_ GRA_TravelAssist  : 30|1@1+ (1.000000,0.000000) [0.000000|1.000000] "" Vector__XXX
 SG_ GRA_reserveByte4  : 31|1@1+ (1.000000,0.000000) [0.000000|1.000000] "" Vector__XXX
 SG_ GRA_reserveByte5  : 32|8@1+ (1.000000,0.000000) [0.000000|255.000000] "" Vector__XXX
 SG_ GRA_reserveByte6  : 40|8@1+ (1.000000,0.000000) [0.000000|255.000000] "" Vector__XXX
 SG_ GRA_reserveByte7  : 48|8@1+ (1.000000,0.000000) [0.000000|255.000000] "" Vector__XXX
 SG_ GRA_reserveByte8  : 56|8@1+ (1.000000,0.000000) [0.000000|255.000000] "" Vector__XXX

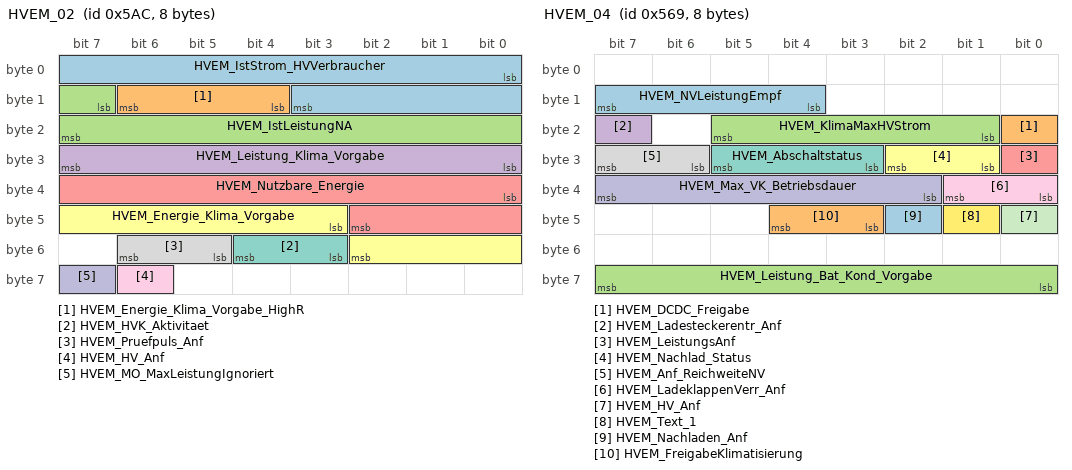
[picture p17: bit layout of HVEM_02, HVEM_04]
BO_ 1452 HVEM_02: 8 ICAS1_Gateway
 SG_ HVEM_IstStrom_HVVerbraucher  : 0|12@1+ (0.100000,-204.700000) [-204.700000|204.600000] "Unit_Amper" Vector__XXX
 SG_ HVEM_Energie_Klima_Vorgabe_HighR  : 12|3@1+ (10.000000,0.000000) [0.000000|50.000000] "Unit_WattHour" Vector__XXX
 SG_ HVEM_IstLeistungNA  : 15|9@1+ (50.000000,0.000000) [0.000000|25450.000000] "Unit_Watt" Motor_BEV
 SG_ HVEM_Leistung_Klima_Vorgabe  : 24|8@1+ (50.000000,0.000000) [0.000000|12650.000000] "Unit_Watt" Vector__XXX
 SG_ HVEM_Nutzbare_Energie  : 32|11@1+ (50.000000,0.000000) [0.000000|102200.000000] "Unit_WattHour" Vector__XXX
 SG_ HVEM_Energie_Klima_Vorgabe  : 43|8@1+ (50.000000,0.000000) [0.000000|12650.000000] "Unit_WattHour" Vector__XXX
 SG_ HVEM_HVK_Aktivitaet  : 51|2@1+ (1.000000,0.000000) [0.000000|3.000000] "" Motor_BEV
 SG_ HVEM_Pruefpuls_Anf  : 53|2@1+ (1.000000,0.000000) [0.000000|3.000000] "" Motor_BEV
 SG_ HVEM_HV_Anf  : 62|1@1+ (1.000000,0.000000) [0.000000|1.000000] "" Motor_BEV
 SG_ HVEM_MO_MaxLeistungIgnoriert  : 63|1@1+ (1.000000,0.000000) [0.000000|1.000000] "" Vector__XXX

BO_ 1385 HVEM_04: 8 ICAS1_Gateway
 SG_ HVEM_NVLeistungEmpf  : 12|4@1+ (100.000000,0.000000) [0.000000|1500.000000] "Unit_Watt" Vector__XXX
 SG_ HVEM_DCDC_Freigabe  : 16|1@1+ (1.000000,0.000000) [0.000000|1.000000] "" Motor_BEV
 SG_ HVEM_KlimaMaxHVStrom  : 17|5@1+ (1.000000,0.000000) [0.000000|31.000000] "Unit_Amper" Vector__XXX
 SG_ HVEM_Ladesteckerentr_Anf  : 23|1@1+ (1.000000,0.000000) [0.000000|1.000000] "" Vector__XXX
 SG_ HVEM_LeistungsAnf  : 24|1@1+ (1.000000,0.000000) [0.000000|1.000000] "" Vector__XXX
 SG_ HVEM_Nachlad_Status  : 25|2@1+ (1.000000,0.000000) [0.000000|3.000000] "" Vector__XXX
 SG_ HVEM_Abschaltstatus  : 27|3@1+ (1.000000,0.000000) [0.000000|7.000000] "" Vector__XXX
 SG_ HVEM_Anf_ReichweiteNV  : 30|2@1+ (1.000000,0.000000) [0.000000|3.000000] "" Vector__XXX
 SG_ HVEM_LadeklappenVerr_Anf  : 32|2@1+ (1.000000,0.000000) [0.000000|3.000000] "" Vector__XXX
 SG_ HVEM_Max_VK_Betriebsdauer  : 34|6@1+ (1.000000,0.000000) [0.000000|60.000000] "Unit_Minut" Vector__XXX
 SG_ HVEM_HV_Anf  : 40|1@1+ (1.000000,0.000000) [0.000000|1.000000] "" Vector__XXX
 SG_ HVEM_Text_1  : 41|1@1+ (1.000000,0.000000) [0.000000|1.000000] "" Vector__XXX
 SG_ HVEM_Nachladen_Anf  : 42|1@1+ (1.000000,0.000000) [0.000000|1.000000] "" Vector__XXX
 SG_ HVEM_FreigabeKlimatisierung  : 43|2@1+ (1.000000,0.000000) [0.000000|3.000000] "" Vector__XXX
 SG_ HVEM_Leistung_Bat_Kond_Vorgabe  : 56|8@1+ (50.000000,0.000000) [0.000000|12650.000000] "Unit_Watt" Vector__XXX

BO_ 1283 HVK_01: 8 Motor_BEV
 SG_ HVK_01_CRC  : 0|8@1+ (1.000000,0.000000) [0.000000|255.000000] "" ICAS1_Gateway LE1 LE2
 SG_ HVK_01_BZ  : 8|4@1+ (1.000000,0.000000) [0.000000|15.000000] "" ICAS1_Gateway LE1 LE2
 SG_ HVK_Istmodus_Anf  : 12|1@1+ (1.000000,0.000000) [0.000000|1.000000] "" ICAS1_Gateway
 SG_ HVK_TN1_Sollmodus  : 13|2@1+ (1.000000,0.000000) [0.000000|3.000000] "" ICAS1_Gateway
 SG_ HVK_Vorladung_aktiv  : 15|1@1+ (1.000000,0.000000) [0.000000|1.000000] "" ICAS1_Gateway
 SG_ HVK_BMS_Sollmodus  : 24|3@1+ (1.000000,0.000000) [0.000000|7.000000] "" ICAS1_Gateway
 SG_ HVK_DCDC_Sollmodus  : 27|3@1+ (1.000000,0.000000) [0.000000|7.000000] "" ICAS1_Gateway
 SG_ HVK_EKK_Sollmodus  : 30|3@1+ (1.000000,0.000000) [0.000000|7.000000] "" ICAS1_Gateway
 SG_ HVK_HVPTC_Sollmodus  : 33|3@1+ (1.000000,0.000000) [0.000000|7.000000] "" ICAS1_Gateway
 SG_ HVK_HVLM_Sollmodus  : 36|3@1+ (1.000000,0.000000) [0.000000|7.000000] "" ICAS1_Gateway
 SG_ HVK_HV_Netz_Warnungen  : 39|2@1+ (1.000000,0.000000) [0.000000|3.000000] "" ICAS1_Gateway ICAS1_KommunikationsServer
 SG_ HV_Bordnetz_aktiv  : 41|1@1+ (1.000000,0.000000) [0.000000|1.000000] "" ICAS1_Gateway LE1 LE2
 SG_ HV_Bordnetz_Fehler  : 42|1@1+ (1.000000,0.000000) [0.000000|1.000000] "" ICAS1_Gateway
 SG_ HVK_Gesamtst_Spgfreiheit  : 43|2@1+ (1.000000,0.000000) [0.000000|3.000000] "" ICAS1_Gateway ICAS1_KommunikationsServer
 SG_ HVK_AktiveEntladung_Anf  : 45|1@1+ (1.000000,0.000000) [0.000000|1.000000] "" ICAS1_Gateway LE1 LE2
 SG_ HVK_HVEM_Freigabe  : 46|2@1+ (1.000000,0.000000) [0.000000|3.000000] "" ICAS1_Gateway
 SG_ HVK_Notentladung_Anf  : 48|2@1+ (1.000000,0.000000) [0.000000|3.000000] "" ICAS1_Gateway LE1 LE2
 SG_ HVK_Iso_Messung_Start  : 50|3@1+ (1.000000,0.000000) [0.000000|7.000000] "" ICAS1_Gateway
 SG_ HVK_Ladebereit  : 53|3@1+ (1.000000,0.000000) [0.000000|7.000000] "" ICAS1_Gateway
 SG_ HVK_PPulsFreigabe  : 56|2@1+ (1.000000,0.000000) [0.000000|3.000000] "" ICAS1_Gateway

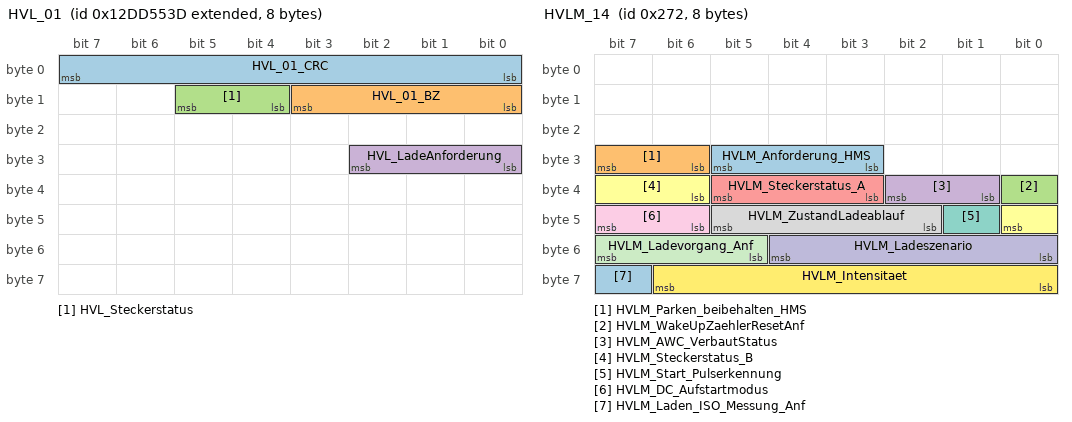
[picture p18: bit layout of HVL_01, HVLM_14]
BO_ 2463978813 HVL_01: 8 ICAS1_Gateway
 SG_ HVL_01_CRC  : 0|8@1+ (1.000000,0.000000) [0.000000|255.000000] "" Motor_BEV
 SG_ HVL_01_BZ  : 8|4@1+ (1.000000,0.000000) [0.000000|15.000000] "" Motor_BEV
 SG_ HVL_Steckerstatus  : 12|2@1+ (1.000000,0.000000) [0.000000|3.000000] "" Motor_BEV
 SG_ HVL_LadeAnforderung  : 24|3@1+ (1.000000,0.000000) [0.000000|7.000000] "" Motor_BEV

BO_ 626 HVLM_14: 8 ICAS1_Gateway
 SG_ HVLM_Anforderung_HMS  : 27|3@1+ (1.000000,0.000000) [0.000000|7.000000] "" Vector__XXX
 SG_ HVLM_Parken_beibehalten_HMS  : 30|2@1+ (1.000000,0.000000) [0.000000|3.000000] "" Vector__XXX
 SG_ HVLM_WakeUpZaehlerResetAnf  : 32|1@1+ (1.000000,0.000000) [0.000000|1.000000] "" Vector__XXX
 SG_ HVLM_AWC_VerbautStatus  : 33|2@1+ (1.000000,0.000000) [0.000000|3.000000] "" Motor_BEV
 SG_ HVLM_Steckerstatus_A  : 35|3@1+ (1.000000,0.000000) [0.000000|7.000000] "" Motor_BEV
 SG_ HVLM_Steckerstatus_B  : 38|3@1+ (1.000000,0.000000) [0.000000|7.000000] "" Vector__XXX
 SG_ HVLM_Start_Pulserkennung  : 41|1@1+ (1.000000,0.000000) [0.000000|1.000000] "" Vector__XXX
 SG_ HVLM_ZustandLadeablauf  : 42|4@1+ (1.000000,0.000000) [0.000000|15.000000] "" Motor_BEV
 SG_ HVLM_DC_Aufstartmodus  : 46|2@1+ (1.000000,0.000000) [0.000000|3.000000] "" Motor_BEV
 SG_ HVLM_Ladeszenario  : 48|5@1+ (1.000000,0.000000) [0.000000|31.000000] "" Vector__XXX
 SG_ HVLM_Ladevorgang_Anf  : 53|3@1+ (1.000000,0.000000) [0.000000|7.000000] "" Motor_BEV
 SG_ HVLM_Intensitaet  : 56|7@1+ (1.000000,0.000000) [0.000000|100.000000] "Unit_PerCent" Vector__XXX
 SG_ HVLM_Laden_ISO_Messung_Anf  : 63|1@1+ (1.000000,0.000000) [0.000000|1.000000] "" Motor_BEV

BO_ 268 IMMO_CORD_01: 8 Motor_BEV
 SG_ ImoCord_Auth_Aufforderung_WFS  : 63|1@1+ (1.000000,0.000000) [0.000000|1.000000] "" LE1 LE2

BO_ 23 IMMO_MSG3_Antwort: 8 ICAS1_Gateway
 SG_ WFS_IMMO_MSG3_CRC  : 0|32@1+ (1.000000,0.000000) [0.000000|4294967295.000000] "" LE2
 SG_ WFS_IMMO_MSG3_Status  : 56|8@1+ (1.000000,0.000000) [0.000000|255.000000] "" LE2

BO_ 25 IMMO_MSG4_Antwort: 8 ICAS1_Gateway
 SG_ WFS_IMMO_MSG4_CRC  : 0|32@1+ (1.000000,0.000000) [0.000000|4294967295.000000] "" LE1
 SG_ WFS_IMMO_MSG4_Status  : 56|8@1+ (1.000000,0.000000) [0.000000|255.000000] "" LE1

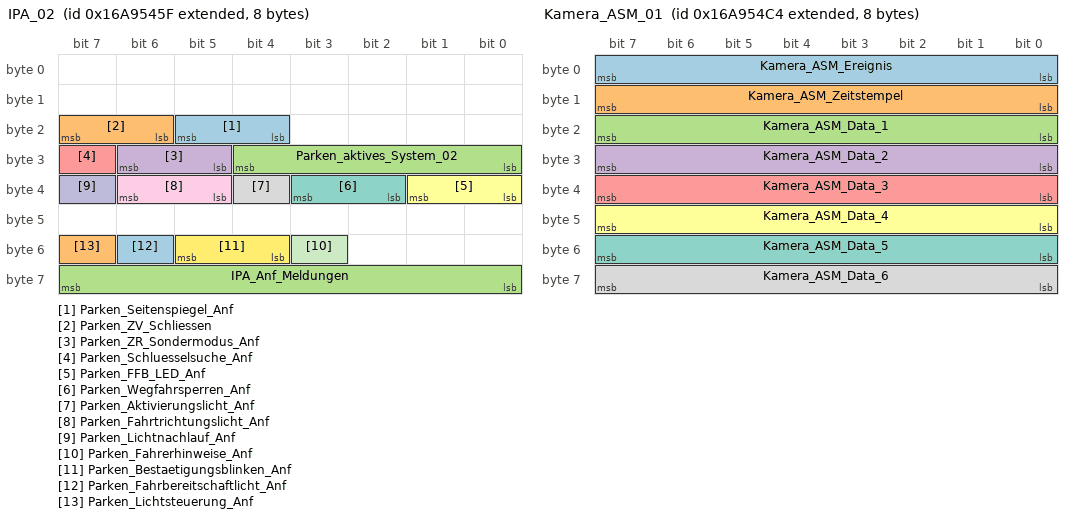
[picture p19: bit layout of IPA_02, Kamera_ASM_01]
BO_ 2527679583 IPA_02: 8 ICAS1_Gateway
 SG_ Parken_Seitenspiegel_Anf  : 20|2@1+ (1.000000,0.000000) [0.000000|3.000000] "" Vector__XXX
 SG_ Parken_ZV_Schliessen  : 22|2@1+ (1.000000,0.000000) [0.000000|3.000000] "" Vector__XXX
 SG_ Parken_aktives_System_02  : 24|5@1+ (1.000000,0.000000) [0.000000|31.000000] "" Vector__XXX
 SG_ Parken_ZR_Sondermodus_Anf  : 29|2@1+ (1.000000,0.000000) [0.000000|3.000000] "" Vector__XXX
 SG_ Parken_Schluesselsuche_Anf  : 31|1@1+ (1.000000,0.000000) [0.000000|1.000000] "" Vector__XXX
 SG_ Parken_FFB_LED_Anf  : 32|2@1+ (1.000000,0.000000) [0.000000|3.000000] "" Vector__XXX
 SG_ Parken_Wegfahrsperren_Anf  : 34|2@1+ (1.000000,0.000000) [0.000000|3.000000] "" LE1 LE2
 SG_ Parken_Aktivierungslicht_Anf  : 36|1@1+ (1.000000,0.000000) [0.000000|1.000000] "" Vector__XXX
 SG_ Parken_Fahrtrichtungslicht_Anf  : 37|2@1+ (1.000000,0.000000) [0.000000|3.000000] "" Vector__XXX
 SG_ Parken_Lichtnachlauf_Anf  : 39|1@1+ (1.000000,0.000000) [0.000000|1.000000] "" Vector__XXX
 SG_ Parken_Fahrerhinweise_Anf  : 51|1@1+ (1.000000,0.000000) [0.000000|1.000000] "" Vector__XXX
 SG_ Parken_Bestaetigungsblinken_Anf  : 52|2@1+ (1.000000,0.000000) [0.000000|3.000000] "" Vector__XXX
 SG_ Parken_Fahrbereitschaftlicht_Anf  : 54|1@1+ (1.000000,0.000000) [0.000000|1.000000] "" Vector__XXX
 SG_ Parken_Lichtsteuerung_Anf  : 55|1@1+ (1.000000,0.000000) [0.000000|1.000000] "" Vector__XXX
 SG_ IPA_Anf_Meldungen  : 56|8@1+ (1.000000,0.000000) [0.000000|255.000000] "" Vector__XXX

BO_ 1813 ISO_Airbag_01_Req: 8 ICAS1_Gateway
 SG_ ISO_Airbag_01_Req_Data  : 0|64@1+ (1.000000,0.000000) [0.000000|18446744073709551616.000000] "" Airbag

BO_ 1919 ISO_Airbag_01_Resp: 8 Airbag
 SG_ ISO_Airbag_01_Resp_Data  : 0|64@1+ (1.000000,0.000000) [0.000000|18446744073709551616.000000] "" ICAS1_Gateway

BO_ 1792 ISO_Funktionaler_Req_All: 8 ICAS1_Gateway
 SG_ ISO_ALL_01_Req_Data  : 0|64@1+ (1.000000,0.000000) [0.000000|18446744073709551616.000000] "" Airbag LE1 LE2 Motor_BEV

BO_ 2621440021 ISOx_Airbag_01_Req_FD: 64 ICAS1_Gateway
 SG_ ISOx_Airbag_01_Req_FD_Data  : 0|512@1+ (1.000000,0.000000) [0.000000|13407807929942597099574024998205846127479365820592393377723561443721764030073546976801874298166903427690031858186486050853753882811946569946433649006084096.000000] "" Airbag

BO_ 2621571093 ISOx_Airbag_01_Resp_FD: 64 Airbag
 SG_ ISOx_Airbag_01_Resp_FD_Data  : 0|512@1+ (1.000000,0.000000) [0.000000|13407807929942597099574024998205846127479365820592393377723561443721764030073546976801874298166903427690031858186486050853753882811946569946433649006084096.000000] "" ICAS1_Gateway

BO_ 2549874812 ISOx_EMotor_01_Req: 8 ICAS1_Gateway
 SG_ ISO_EMotor_01_Req_Data  : 0|64@1+ (1.000000,0.000000) [0.000000|18446744073709551616.000000] "" LE1

BO_ 2621440124 ISOx_EMotor_01_Req_FD: 64 ICAS1_Gateway
 SG_ ISOx_EMotor_01_Req_FD_Data  : 0|512@1+ (1.000000,0.000000) [0.000000|13407807929942597099574024998205846127479365820592393377723561443721764030073546976801874298166903427690031858186486050853753882811946569946433649006084096.000000] "" LE1

BO_ 2550005884 ISOx_EMotor_01_Resp: 8 LE1
 SG_ ISO_EMotor_01_Resp_Data  : 0|64@1+ (1.000000,0.000000) [0.000000|18446744073709551616.000000] "" ICAS1_Gateway

BO_ 2621571196 ISOx_EMotor_01_Resp_FD: 64 LE1
 SG_ ISOx_EMotor_01_Resp_FD_Data  : 0|512@1+ (1.000000,0.000000) [0.000000|13407807929942597099574024998205846127479365820592393377723561443721764030073546976801874298166903427690031858186486050853753882811946569946433649006084096.000000] "" ICAS1_Gateway

BO_ 2549874872 ISOx_EMotor_02_Req: 8 ICAS1_Gateway
 SG_ ISO_EMotor_02_Req_Data  : 0|64@1+ (1.000000,0.000000) [0.000000|18446744073709551616.000000] "" LE2

BO_ 2621440184 ISOx_EMotor_02_Req_FD: 64 ICAS1_Gateway
 SG_ ISOx_EMotor_02_Req_FD_Data  : 0|512@1+ (1.000000,0.000000) [0.000000|13407807929942597099574024998205846127479365820592393377723561443721764030073546976801874298166903427690031858186486050853753882811946569946433649006084096.000000] "" LE2

BO_ 2550005944 ISOx_EMotor_02_Resp: 8 LE2
 SG_ ISO_EMotor_02_Resp_Data  : 0|64@1+ (1.000000,0.000000) [0.000000|18446744073709551616.000000] "" ICAS1_Gateway

BO_ 2621571256 ISOx_EMotor_02_Resp_FD: 64 LE2
 SG_ ISOx_EMotor_02_Resp_FD_Data  : 0|512@1+ (1.000000,0.000000) [0.000000|13407807929942597099574024998205846127479365820592393377723561443721764030073546976801874298166903427690031858186486050853753882811946569946433649006084096.000000] "" ICAS1_Gateway

BO_ 2621505536 ISOx_Funkt_Req_All_FD: 64 ICAS1_Gateway
 SG_ ISOx_Funkt_Req_All_FD_Data  : 0|512@1+ (1.000000,0.000000) [0.000000|13407807929942597099574024998205846127479365820592393377723561443721764030073546976801874298166903427690031858186486050853753882811946569946433649006084096.000000] "" Airbag LE1 LE2 Motor_BEV

BO_ 2549874806 ISOx_MO_01_Req: 8 ICAS1_Gateway
 SG_ ISOx_MO_01_Req_Data  : 0|64@1+ (1.000000,0.000000) [0.000000|18446744073709551616.000000] "" Motor_BEV

BO_ 2621440118 ISOx_MO_01_Req_FD: 64 ICAS1_Gateway
 SG_ ISOx_MO_01_Req_FD_Data  : 0|512@1+ (1.000000,0.000000) [0.000000|13407807929942597099574024998205846127479365820592393377723561443721764030073546976801874298166903427690031858186486050853753882811946569946433649006084096.000000] "" Motor_BEV

BO_ 2550005878 ISOx_MO_01_Resp: 8 Motor_BEV
 SG_ ISOx_MO_01_Resp_Data  : 0|64@1+ (1.000000,0.000000) [0.000000|18446744073709551616.000000] "" ICAS1_Gateway

BO_ 2621571190 ISOx_MO_01_Resp_FD: 64 Motor_BEV
 SG_ ISOx_MO_01_Resp_FD_Data  : 0|512@1+ (1.000000,0.000000) [0.000000|13407807929942597099574024998205846127479365820592393377723561443721764030073546976801874298166903427690031858186486050853753882811946569946433649006084096.000000] "" ICAS1_Gateway

BO_ 2527679684 Kamera_ASM_01: 8 ICAS1_Gateway
 SG_ Kamera_ASM_Ereignis  : 0|8@1+ (1.000000,0.000000) [1.000000|254.000000] "" Airbag
 SG_ Kamera_ASM_Zeitstempel  : 8|8@1+ (0.080000,0.000000) [0.000000|20.320000] "Unit_Secon" Airbag
 SG_ Kamera_ASM_Data_1  : 16|8@1+ (1.000000,0.000000) [0.000000|255.000000] "" Airbag
 SG_ Kamera_ASM_Data_2  : 24|8@1+ (1.000000,0.000000) [0.000000|255.000000] "" Airbag
 SG_ Kamera_ASM_Data_3  : 32|8@1+ (1.000000,0.000000) [0.000000|255.000000] "" Airbag
 SG_ Kamera_ASM_Data_4  : 40|8@1+ (1.000000,0.000000) [0.000000|255.000000] "" Airbag
 SG_ Kamera_ASM_Data_5  : 48|8@1+ (1.000000,0.000000) [0.000000|255.000000] "" Airbag
 SG_ Kamera_ASM_Data_6  : 56|8@1+ (1.000000,0.000000) [0.000000|255.000000] "" Airbag

BO_ 960 Klemmen_Status_01: 4 ICAS1_Gateway
 SG_ Klemmen_Status_01_CRC  : 0|8@1+ (1.000000,0.000000) [0.000000|255.000000] "" Motor_BEV
 SG_ Klemmen_Status_01_BZ  : 8|4@1+ (1.000000,0.000000) [0.000000|15.000000] "" Motor_BEV
 SG_ RSt_Fahrerhinweise  : 12|4@1+ (1.000000,0.000000) [0.000000|15.000000] "" Vector__XXX
 SG_ ZAS_Kl_S  : 16|1@1+ (1.000000,0.000000) [0.000000|1.000000] "" Vector__XXX
 SG_ ZAS_Kl_15  : 17|1@1+ (1.000000,0.000000) [0.000000|1.000000] "" Airbag LE1 LE2 Motor_BEV Schaltbetaetigung
 SG_ ZAS_Kl_X  : 18|1@1+ (1.000000,0.000000) [0.000000|1.000000] "" Vector__XXX
 SG_ ZAS_Kl_50_Startanforderung  : 19|1@1+ (1.000000,0.000000) [0.000000|1.000000] "" Motor_BEV
 SG_ BCM_Remotestart_Betrieb  : 20|1@1+ (1.000000,0.000000) [0.000000|1.000000] "" Vector__XXX
 SG_ ZAS_Kl_Infotainment  : 21|1@1+ (1.000000,0.000000) [0.000000|1.000000] "" Vector__XXX
 SG_ BCM_Remotestart_KL15_Anf  : 22|1@1+ (1.000000,0.000000) [0.000000|1.000000] "" Vector__XXX
 SG_ BCM_Remotestart_MO_Start  : 23|1@1+ (1.000000,0.000000) [0.000000|1.000000] "" Vector__XXX
 SG_ KST_Warn_P1_ZST_def  : 24|1@1+ (1.000000,0.000000) [0.000000|1.000000] "" Vector__XXX
 SG_ KST_Warn_P2_ZST_def  : 25|1@1+ (1.000000,0.000000) [0.000000|1.000000] "" Vector__XXX
 SG_ KST_Fahrerhinweis_1  : 26|1@1+ (1.000000,0.000000) [0.000000|1.000000] "" Vector__XXX
 SG_ KST_Fahrerhinweis_2  : 27|1@1+ (1.000000,0.000000) [0.000000|1.000000] "" Vector__XXX
 SG_ BCM_Ausparken_Betrieb  : 28|1@1+ (1.000000,0.000000) [0.000000|1.000000] "" Vector__XXX
 SG_ KST_Fahrerhinweis_4  : 29|1@1+ (1.000000,0.000000) [0.000000|1.000000] "" Vector__XXX
 SG_ KST_Fahrerhinweis_5  : 30|1@1+ (1.000000,0.000000) [0.000000|1.000000] "" Vector__XXX
 SG_ KST_Fahrerhinweis_6  : 31|1@1+ (1.000000,0.000000) [0.000000|1.000000] "" Vector__XXX

BO_ 2463978753 Klemmen_Status_02: 8 ICAS1_Gateway
 SG_ KST_WFS_Fahrfreigabe_Anforderung  : 12|2@1+ (1.000000,0.000000) [0.000000|3.000000] "" LE1 LE2
 SG_ KST_Sonderzustand_Status  : 14|2@1+ (1.000000,0.000000) [0.000000|3.000000] "" LE1 LE2
 SG_ KST_Sonderzustand_Anforderung  : 16|5@1+ (1.000000,0.000000) [0.000000|31.000000] "" LE1 LE2

BO_ 1420 Klemmen_Steuerung_01: 8 ICAS1_Gateway
 SG_ Klemmen_Steuerung_01_CRC  : 0|8@1+ (1.000000,0.000000) [0.000000|255.000000] "" Vector__XXX
 SG_ Klemmen_Steuerung_01_BZ  : 8|4@1+ (1.000000,0.000000) [0.000000|15.000000] "" Vector__XXX
 SG_ KST_Anf_Klemme_15  : 12|1@1+ (1.000000,0.000000) [0.000000|1.000000] "" Vector__XXX
 SG_ KST_Anf_Klemme_50  : 13|1@1+ (1.000000,0.000000) [0.000000|1.000000] "" Motor_BEV
 SG_ KST_Anf_Klemme_S  : 14|1@1+ (1.000000,0.000000) [0.000000|1.000000] "" Vector__XXX
 SG_ KST_Txt_Werkstatt  : 15|1@1+ (1.000000,0.000000) [0.000000|1.000000] "" Vector__XXX
 SG_ KST_Txt_P_Gang  : 16|1@1+ (1.000000,0.000000) [0.000000|1.000000] "" Vector__XXX
 SG_ KST_Txt_Panikabschaltung  : 17|1@1+ (1.000000,0.000000) [0.000000|1.000000] "" Vector__XXX
 SG_ KST_Anf_Klemmenfreigabe_ELV  : 18|1@1+ (1.000000,0.000000) [0.000000|1.000000] "" Vector__XXX
 SG_ KST_Txt_Komfortabschaltung  : 19|1@1+ (1.000000,0.000000) [0.000000|1.000000] "" Vector__XXX
 SG_ KST_ZAT_betaetigt  : 20|1@1+ (1.000000,0.000000) [0.000000|1.000000] "" Vector__XXX
 SG_ KST_Unterdr_Zuendungsmeldung  : 21|1@1+ (1.000000,0.000000) [0.000000|1.000000] "" Vector__XXX
 SG_ KST_aut_Abschaltung_Zuendung  : 22|1@1+ (1.000000,0.000000) [0.000000|1.000000] "" Vector__XXX
 SG_ KST_Anf_Klemmenfreigabe_WFS  : 23|1@1+ (1.000000,0.000000) [0.000000|1.000000] "" Vector__XXX
 SG_ KST_Anf_ZV_Verriegelung  : 24|1@1+ (1.000000,0.000000) [0.000000|1.000000] "" Vector__XXX
 SG_ Relais_VoKo_angesteuert  : 25|1@1+ (1.000000,0.000000) [0.000000|1.000000] "" Vector__XXX
 SG_ RSt_Anforderung_HMS  : 26|3@1+ (1.000000,0.000000) [0.000000|7.000000] "" Vector__XXX
 SG_ KST_Zuendungswarnung  : 29|2@1+ (1.000000,0.000000) [0.000000|3.000000] "" Vector__XXX
 SG_ KST_Fahrer_Info_Text  : 31|3@1+ (1.000000,0.000000) [0.000000|7.000000] "" Vector__XXX

BA_DEF_  "NmhMessageCount" INT 0 1024;
BA_DEF_  "VersionDay" INT 1 31;
BA_DEF_  "VersionMonth" INT 1 12;
BA_DEF_  "VersionWeek" INT 1 52;
BA_DEF_  "VersionYear" INT 0 99;
BA_DEF_  "Baudrate" INT 1 1000000;
BA_DEF_  "BaudrateCANFD" INT 1 16000000;
BA_DEF_ BU_ "GenNodAutoGenDsp" ENUM "No", "Yes";
BA_DEF_ BU_ "GenNodAutoGenSnd" ENUM "No", "Yes";
BA_DEF_ BU_ "GenNodSleepTime" INT 0 1000000;
BA_DEF_ BU_ "ILUsed" ENUM "No", "Yes";
BA_DEF_ BU_ "ECUVariantDefault" ENUM "No", "Yes";
BA_DEF_ BU_ "ECUVariantGroup" STRING;
BA_DEF_ BU_ "NodeLayerModules" STRING;
BA_DEF_ BU_ "NmhNode" ENUM "No", "Yes";
BA_DEF_ BU_ "NmNode" ENUM "No", "Yes";
BA_DEF_ BU_ "SamplePointMin" FLOAT 50.000000 99.900000;
BA_DEF_ BU_ "SamplePointMax" FLOAT 50.000000 99.900000;
BA_DEF_ BU_ "SyncJumpWidthMin" FLOAT 0.000000 50.000000;
BA_DEF_ BU_ "SyncJumpWidthMax" FLOAT 0.000000 50.000000;
BA_DEF_ BU_ "SyncJumpWidthCANFDMin" FLOAT 0.000000 50.000000;
BA_DEF_ BU_ "SyncJumpWidthCANFDMax" FLOAT 0.000000 50.000000;
BA_DEF_ BU_ "SamplePointCANFDMin" FLOAT 50.000000 99.900000;
BA_DEF_ BU_ "SamplePointCANFDMax" FLOAT 50.000000 99.900000;
BA_DEF_ BU_ "SSPOffsetCANFDMin" FLOAT 50.000000 99.900000;
BA_DEF_ BU_ "SSPOffsetCANFDMax" FLOAT 50.000000 99.900000;
BA_DEF_ BU_ "TimeQuantaMin" INT 4 257;
BA_DEF_ BU_ "TimeQuantaMax" INT 4 257;
BA_DEF_ BU_ "TimeQuantaCANFDMin" INT 4 257;
BA_DEF_ BU_ "TimeQuantaCANFDMax" INT 4 257;
BA_DEF_ BO_ "DiagRequest" ENUM "No", "Yes";
BA_DEF_ BO_ "DiagResponse" ENUM "No", "Yes";
BA_DEF_ BO_ "DiagState" ENUM "No", "Yes";
BA_DEF_ BO_ "GenMsgChkConstant" HEX 0 4095;
BA_DEF_ BO_ "GenMsgCycleTime" INT 0 65535;
BA_DEF_ BO_ "GenMsgCycleTimeFast" INT 0 65535;
BA_DEF_ BO_ "GenMsgDelayTime" INT 0 100000;
BA_DEF_ BO_ "GenMsgILSupport" ENUM "No", "Yes";
BA_DEF_ BO_ "GenMsgNrOfRepetition" INT 0 100;
BA_DEF_ BO_ "GenMsgPDUConstants" STRING;
BA_DEF_ BO_ "GenMsgSendType" ENUM "Cyclic", "not_used", "not_used", "not_used", "not_used", "not_used", "not_used", "IfActive", "NoMsgSendType";
BA_DEF_ BO_ "GenMsgStartDelayTime" INT 0 100000;
BA_DEF_ BO_ "NmMessage" ENUM "No", "Yes";
BA_DEF_ BO_ "NmhMessage" ENUM "No", "Yes";
BA_DEF_ BO_ "MsgType" ENUM "Application", "NM", "NMH", "TP2.0", "ISO-TP", "BAP", "EID", "KS";
BA_DEF_ BO_ "VAGTP20_API" HEX 0 255;
BA_DEF_ BO_ "VAGTP20_DynConnection" ENUM "No", "Yes";
BA_DEF_ BO_ "VAGTP20_DynSetup" ENUM "No", "Yes";
BA_DEF_ BO_ "VAGTP20_StatConnection" ENUM "No", "Yes";
BA_DEF_ BO_ "CANFD_BRS" ENUM "0", "1";
BA_DEF_ BO_ "VFrameFormat" ENUM "StandardCAN", "ExtendedCAN", "reserved", "reserved", "reserved", "reserved", "reserved", "reserved", "reserved", "reserved", "reserved", "reserved", "reserved", "reserved", "StandardCAN_FD", "ExtendedCAN_FD";
BA_DEF_ SG_ "GenSigSendType" ENUM "Cyclic", "OnWrite", "OnWriteWithRepetition", "OnChange", "OnChangeWithRepetition", "IfActive", "IfActiveWithRepetition", "NoSigSendType", "OnChangeAndIfActive", "OnChangeAndIfActiveWithRepetition";
BA_DEF_ SG_ "GenSigFuncType" ENUM "NoFunction", "MsgCounter", "CRC-8", "XOR", "XOR-2", "DatedBit", "SW-Kl15", "CHK", "Constant", "Protocol", "CRC-8-SAE_J1850";
BA_DEF_ SG_ "GenSigSwitchedByIgnition" ENUM "No", "Yes";
BA_DEF_DEF_  "NmhMessageCount" 1;
BA_DEF_DEF_  "VersionDay" 8;
BA_DEF_DEF_  "VersionMonth" 2;
BA_DEF_DEF_  "VersionWeek" 6;
BA_DEF_DEF_  "VersionYear" 18;
BA_DEF_DEF_  "Baudrate" 500000;
BA_DEF_DEF_  "BaudrateCANFD" 2000000;
BA_DEF_DEF_  "GenNodAutoGenDsp" "Yes";
BA_DEF_DEF_  "GenNodAutoGenSnd" "Yes";
BA_DEF_DEF_  "GenNodSleepTime" 0;
BA_DEF_DEF_  "ILUsed" "Yes";
BA_DEF_DEF_  "ECUVariantDefault" "Yes";
BA_DEF_DEF_  "ECUVariantGroup" "";
BA_DEF_DEF_  "NodeLayerModules" "";
BA_DEF_DEF_  "NmhNode" "Yes";
BA_DEF_DEF_  "NmNode" "No";
BA_DEF_DEF_  "SamplePointMin" 75.000000;
BA_DEF_DEF_  "SamplePointMax" 75.000000;
BA_DEF_DEF_  "SyncJumpWidthMin" 50.000000;
BA_DEF_DEF_  "SyncJumpWidthMax" 50.000000;
BA_DEF_DEF_  "SyncJumpWidthCANFDMin" 50.000000;
BA_DEF_DEF_  "SyncJumpWidthCANFDMax" 50.000000;
BA_DEF_DEF_  "SamplePointCANFDMin" 75.000000;
BA_DEF_DEF_  "SamplePointCANFDMax" 75.000000;
BA_DEF_DEF_  "SSPOffsetCANFDMin" 75.000000;
BA_DEF_DEF_  "SSPOffsetCANFDMax" 75.000000;
BA_DEF_DEF_  "TimeQuantaMin" 160;
BA_DEF_DEF_  "TimeQuantaMax" 160;
BA_DEF_DEF_  "TimeQuantaCANFDMin" 40;
BA_DEF_DEF_  "TimeQuantaCANFDMax" 40;
BA_DEF_DEF_  "DiagRequest" "No";
BA_DEF_DEF_  "DiagResponse" "No";
BA_DEF_DEF_  "DiagState" "No";
BA_DEF_DEF_  "GenMsgChkConstant" 0;
BA_DEF_DEF_  "GenMsgCycleTime" 0;
BA_DEF_DEF_  "GenMsgCycleTimeFast" 0;
BA_DEF_DEF_  "GenMsgDelayTime" 0;
BA_DEF_DEF_  "GenMsgILSupport" "No";
BA_DEF_DEF_  "GenMsgNrOfRepetition" 0;
BA_DEF_DEF_  "GenMsgPDUConstants" "";
BA_DEF_DEF_  "GenMsgSendType" "NoMsgSendType";
BA_DEF_DEF_  "GenMsgStartDelayTime" 0;
BA_DEF_DEF_  "NmMessage" "No";
BA_DEF_DEF_  "NmhMessage" "No";
BA_DEF_DEF_  "MsgType" "Application";
BA_DEF_DEF_  "VAGTP20_API" 0;
BA_DEF_DEF_  "VAGTP20_DynConnection" "No";
BA_DEF_DEF_  "VAGTP20_DynSetup" "No";
BA_DEF_DEF_  "VAGTP20_StatConnection" "No";
BA_DEF_DEF_  "CANFD_BRS" "1";
BA_DEF_DEF_  "VFrameFormat" "StandardCAN";
BA_DEF_DEF_  "GenSigSendType" "NoSigSendType";
BA_DEF_DEF_  "GenSigFuncType" "NoFunction";
BA_DEF_DEF_  "GenSigSwitchedByIgnition" "Yes";
BA_ "GenNodSleepTime" BU_ Airbag 4000;
BA_ "NodeLayerModules" BU_ Airbag "NMHigh.DLL";
BA_ "SamplePointMin" BU_ Airbag 80.000000;
BA_ "SamplePointMax" BU_ Airbag 80.000000;
BA_ "SyncJumpWidthMin" BU_ Airbag 16.000000;
BA_ "SyncJumpWidthMax" BU_ Airbag 16.000000;
BA_ "SyncJumpWidthCANFDMin" BU_ Airbag 6.000000;
BA_ "SyncJumpWidthCANFDMax" BU_ Airbag 6.000000;
BA_ "SamplePointCANFDMin" BU_ Airbag 70.000000;
BA_ "SamplePointCANFDMax" BU_ Airbag 70.000000;
BA_ "SSPOffsetCANFDMin" BU_ Airbag 70.000000;
BA_ "SSPOffsetCANFDMax" BU_ Airbag 70.000000;
BA_ "TimeQuantaMin" BU_ Airbag 80;
BA_ "TimeQuantaMax" BU_ Airbag 80;
BA_ "TimeQuantaCANFDMin" BU_ Airbag 20;
BA_ "TimeQuantaCANFDMax" BU_ Airbag 20;
BA_ "GenNodSleepTime" BU_ BAP_Tester 4000;
BA_ "ECUVariantGroup" BU_ BAP_Tester "BAP";
BA_ "NmhNode" BU_ BAP_Tester "No";
BA_ "SamplePointMin" BU_ BAP_Tester 80.000000;
BA_ "SamplePointMax" BU_ BAP_Tester 80.000000;
BA_ "SyncJumpWidthMin" BU_ BAP_Tester 16.000000;
BA_ "SyncJumpWidthMax" BU_ BAP_Tester 16.000000;
BA_ "SyncJumpWidthCANFDMin" BU_ BAP_Tester 6.000000;
BA_ "SyncJumpWidthCANFDMax" BU_ BAP_Tester 6.000000;
BA_ "SamplePointCANFDMin" BU_ BAP_Tester 70.000000;
BA_ "SamplePointCANFDMax" BU_ BAP_Tester 70.000000;
BA_ "SSPOffsetCANFDMin" BU_ BAP_Tester 70.000000;
BA_ "SSPOffsetCANFDMax" BU_ BAP_Tester 70.000000;
BA_ "TimeQuantaMin" BU_ BAP_Tester 80;
BA_ "TimeQuantaMax" BU_ BAP_Tester 80;
BA_ "TimeQuantaCANFDMin" BU_ BAP_Tester 20;
BA_ "TimeQuantaCANFDMax" BU_ BAP_Tester 20;
BA_ "GenNodSleepTime" BU_ ICAS1_Gateway 4000;
BA_ "ECUVariantGroup" BU_ ICAS1_Gateway "Gateway";
BA_ "NodeLayerModules" BU_ ICAS1_Gateway "NMHigh.DLL";
BA_ "SamplePointMin" BU_ ICAS1_Gateway 80.000000;
BA_ "SamplePointMax" BU_ ICAS1_Gateway 80.000000;
BA_ "SyncJumpWidthMin" BU_ ICAS1_Gateway 16.000000;
BA_ "SyncJumpWidthMax" BU_ ICAS1_Gateway 16.000000;
BA_ "SyncJumpWidthCANFDMin" BU_ ICAS1_Gateway 6.000000;
BA_ "SyncJumpWidthCANFDMax" BU_ ICAS1_Gateway 6.000000;
BA_ "SamplePointCANFDMin" BU_ ICAS1_Gateway 70.000000;
BA_ "SamplePointCANFDMax" BU_ ICAS1_Gateway 70.000000;
BA_ "SSPOffsetCANFDMin" BU_ ICAS1_Gateway 70.000000;
BA_ "SSPOffsetCANFDMax" BU_ ICAS1_Gateway 70.000000;
BA_ "TimeQuantaMin" BU_ ICAS1_Gateway 80;
BA_ "TimeQuantaMax" BU_ ICAS1_Gateway 80;
BA_ "TimeQuantaCANFDMin" BU_ ICAS1_Gateway 20;
BA_ "TimeQuantaCANFDMax" BU_ ICAS1_Gateway 20;
BA_ "GenNodSleepTime" BU_ ICAS1_KommunikationsServer 4000;
BA_ "NmhNode" BU_ ICAS1_KommunikationsServer "No";
BA_ "SamplePointMin" BU_ ICAS1_KommunikationsServer 80.000000;
BA_ "SamplePointMax" BU_ ICAS1_KommunikationsServer 80.000000;
BA_ "SyncJumpWidthMin" BU_ ICAS1_KommunikationsServer 16.000000;
BA_ "SyncJumpWidthMax" BU_ ICAS1_KommunikationsServer 16.000000;
BA_ "SyncJumpWidthCANFDMin" BU_ ICAS1_KommunikationsServer 6.000000;
BA_ "SyncJumpWidthCANFDMax" BU_ ICAS1_KommunikationsServer 6.000000;
BA_ "SamplePointCANFDMin" BU_ ICAS1_KommunikationsServer 70.000000;
BA_ "SamplePointCANFDMax" BU_ ICAS1_KommunikationsServer 70.000000;
BA_ "SSPOffsetCANFDMin" BU_ ICAS1_KommunikationsServer 70.000000;
BA_ "SSPOffsetCANFDMax" BU_ ICAS1_KommunikationsServer 70.000000;
BA_ "TimeQuantaMin" BU_ ICAS1_KommunikationsServer 80;
BA_ "TimeQuantaMax" BU_ ICAS1_KommunikationsServer 80;
BA_ "TimeQuantaCANFDMin" BU_ ICAS1_KommunikationsServer 20;
BA_ "TimeQuantaCANFDMax" BU_ ICAS1_KommunikationsServer 20;
BA_ "GenNodSleepTime" BU_ LE1 4000;
BA_ "ECUVariantDefault" BU_ LE1 "No";
BA_ "ECUVariantGroup" BU_ LE1 "EMotor";
BA_ "NodeLayerModules" BU_ LE1 "NMHigh.DLL";
BA_ "SamplePointMin" BU_ LE1 80.000000;
BA_ "SamplePointMax" BU_ LE1 80.000000;
BA_ "SyncJumpWidthMin" BU_ LE1 16.000000;
BA_ "SyncJumpWidthMax" BU_ LE1 16.000000;
BA_ "SyncJumpWidthCANFDMin" BU_ LE1 6.000000;
BA_ "SyncJumpWidthCANFDMax" BU_ LE1 6.000000;
BA_ "SamplePointCANFDMin" BU_ LE1 70.000000;
BA_ "SamplePointCANFDMax" BU_ LE1 70.000000;
BA_ "SSPOffsetCANFDMin" BU_ LE1 70.000000;
BA_ "SSPOffsetCANFDMax" BU_ LE1 70.000000;
BA_ "TimeQuantaMin" BU_ LE1 80;
BA_ "TimeQuantaMax" BU_ LE1 80;
BA_ "TimeQuantaCANFDMin" BU_ LE1 20;
BA_ "TimeQuantaCANFDMax" BU_ LE1 20;
BA_ "GenNodSleepTime" BU_ LE2 4000;
BA_ "NodeLayerModules" BU_ LE2 "NMHigh.DLL";
BA_ "SamplePointMin" BU_ LE2 80.000000;
BA_ "SamplePointMax" BU_ LE2 80.000000;
BA_ "SyncJumpWidthMin" BU_ LE2 16.000000;
BA_ "SyncJumpWidthMax" BU_ LE2 16.000000;
BA_ "SyncJumpWidthCANFDMin" BU_ LE2 6.000000;
BA_ "SyncJumpWidthCANFDMax" BU_ LE2 6.000000;
BA_ "SamplePointCANFDMin" BU_ LE2 70.000000;
BA_ "SamplePointCANFDMax" BU_ LE2 70.000000;
BA_ "SSPOffsetCANFDMin" BU_ LE2 70.000000;
BA_ "SSPOffsetCANFDMax" BU_ LE2 70.000000;
BA_ "TimeQuantaMin" BU_ LE2 80;
BA_ "TimeQuantaMax" BU_ LE2 80;
BA_ "TimeQuantaCANFDMin" BU_ LE2 20;
BA_ "TimeQuantaCANFDMax" BU_ LE2 20;
BA_ "GenNodSleepTime" BU_ Motor_BEV 4000;
BA_ "ECUVariantGroup" BU_ Motor_BEV "Motor";
BA_ "NodeLayerModules" BU_ Motor_BEV "NMHigh.DLL";
BA_ "SamplePointMin" BU_ Motor_BEV 80.000000;
BA_ "SamplePointMax" BU_ Motor_BEV 80.000000;
BA_ "SyncJumpWidthMin" BU_ Motor_BEV 16.000000;
BA_ "SyncJumpWidthMax" BU_ Motor_BEV 16.000000;
BA_ "SyncJumpWidthCANFDMin" BU_ Motor_BEV 6.000000;
BA_ "SyncJumpWidthCANFDMax" BU_ Motor_BEV 6.000000;
BA_ "SamplePointCANFDMin" BU_ Motor_BEV 70.000000;
BA_ "SamplePointCANFDMax" BU_ Motor_BEV 70.000000;
BA_ "SSPOffsetCANFDMin" BU_ Motor_BEV 70.000000;
BA_ "SSPOffsetCANFDMax" BU_ Motor_BEV 70.000000;
BA_ "TimeQuantaMin" BU_ Motor_BEV 80;
BA_ "TimeQuantaMax" BU_ Motor_BEV 80;
BA_ "TimeQuantaCANFDMin" BU_ Motor_BEV 20;
BA_ "TimeQuantaCANFDMax" BU_ Motor_BEV 20;
BA_ "GenNodSleepTime" BU_ Schaltbetaetigung 4000;
BA_ "ECUVariantGroup" BU_ Schaltbetaetigung "Waehlhebel";
BA_ "NodeLayerModules" BU_ Schaltbetaetigung "NMHigh.DLL";
BA_ "SamplePointMin" BU_ Schaltbetaetigung 80.000000;
BA_ "SamplePointMax" BU_ Schaltbetaetigung 80.000000;
BA_ "SyncJumpWidthMin" BU_ Schaltbetaetigung 16.000000;
BA_ "SyncJumpWidthMax" BU_ Schaltbetaetigung 16.000000;
BA_ "SyncJumpWidthCANFDMin" BU_ Schaltbetaetigung 6.000000;
BA_ "SyncJumpWidthCANFDMax" BU_ Schaltbetaetigung 6.000000;
BA_ "SamplePointCANFDMin" BU_ Schaltbetaetigung 70.000000;
BA_ "SamplePointCANFDMax" BU_ Schaltbetaetigung 70.000000;
BA_ "SSPOffsetCANFDMin" BU_ Schaltbetaetigung 70.000000;
BA_ "SSPOffsetCANFDMax" BU_ Schaltbetaetigung 70.000000;
BA_ "TimeQuantaMin" BU_ Schaltbetaetigung 80;
BA_ "TimeQuantaMax" BU_ Schaltbetaetigung 80;
BA_ "TimeQuantaCANFDMin" BU_ Schaltbetaetigung 20;
BA_ "TimeQuantaCANFDMax" BU_ Schaltbetaetigung 20;
BA_ "GenMsgCycleTime" BO_ 333 20;
BA_ "GenMsgILSupport" BO_ 333 "Yes";
BA_ "GenMsgPDUConstants" BO_ 333 "0x1a,0x65,0x81,0x96,0xc0,0xdf,0x11,0x92,0xd3,0x61,0xc6,0x95,0x8c,0x29,0x21,0xb5";
BA_ "GenMsgSendType" BO_ 333 "Cyclic";
BA_ "VFrameFormat" BO_ 333 "StandardCAN_FD";
BA_ "GenMsgCycleTime" BO_ 2527679682 2000;
BA_ "GenMsgDelayTime" BO_ 2527679682 100;
BA_ "GenMsgILSupport" BO_ 2527679682 "Yes";
BA_ "GenMsgSendType" BO_ 2527679682 "Cyclic";
BA_ "VFrameFormat" BO_ 2527679682 "ExtendedCAN_FD";
BA_ "GenMsgChkConstant" BO_ 64 64;
BA_ "GenMsgCycleTime" BO_ 64 40;
BA_ "GenMsgCycleTimeFast" BO_ 64 10;
BA_ "GenMsgDelayTime" BO_ 64 10;
BA_ "GenMsgILSupport" BO_ 64 "Yes";
BA_ "GenMsgNrOfRepetition" BO_ 64 5;
BA_ "GenMsgPDUConstants" BO_ 64 "0x40,0x40,0x40,0x40,0x40,0x40,0x40,0x40,0x40,0x40,0x40,0x40,0x40,0x40,0x40,0x40";
BA_ "GenMsgSendType" BO_ 64 "Cyclic";
BA_ "CANFD_BRS" BO_ 64 "0";
BA_ "GenMsgChkConstant" BO_ 1312 68;
BA_ "GenMsgCycleTime" BO_ 1312 200;
BA_ "GenMsgDelayTime" BO_ 1312 20;
BA_ "GenMsgILSupport" BO_ 1312 "Yes";
BA_ "GenMsgPDUConstants" BO_ 1312 "0x44,0x44,0x44,0x44,0x44,0x44,0x44,0x44,0x44,0x44,0x44,0x44,0x44,0x44,0x44,0x44";
BA_ "GenMsgSendType" BO_ 1312 "Cyclic";
BA_ "CANFD_BRS" BO_ 1312 "0";
BA_ "GenMsgCycleTime" BO_ 65 1000;
BA_ "GenMsgCycleTimeFast" BO_ 65 10;
BA_ "GenMsgDelayTime" BO_ 65 10;
BA_ "GenMsgILSupport" BO_ 65 "Yes";
BA_ "GenMsgNrOfRepetition" BO_ 65 5;
BA_ "GenMsgPDUConstants" BO_ 65 "0x93,0xb0,0x9d,0xf1,0x09,0xe8,0x88,0x5e,0x36,0xfa,0xa8,0xa1,0x67,0x84,0xca,0x4f";
BA_ "GenMsgSendType" BO_ 65 "Cyclic";
BA_ "CANFD_BRS" BO_ 65 "0";
BA_ "GenMsgCycleTime" BO_ 1349 200;
BA_ "GenMsgDelayTime" BO_ 1349 40;
BA_ "GenMsgILSupport" BO_ 1349 "Yes";
BA_ "GenMsgSendType" BO_ 1349 "Cyclic";
BA_ "CANFD_BRS" BO_ 1349 "0";
BA_ "GenMsgCycleTime" BO_ 2527679722 200;
BA_ "GenMsgILSupport" BO_ 2527679722 "Yes";
BA_ "GenMsgSendType" BO_ 2527679722 "Cyclic";
BA_ "CANFD_BRS" BO_ 2527679722 "0";
BA_ "VFrameFormat" BO_ 2527679722 "ExtendedCAN";
BA_ "GenMsgCycleTime" BO_ 1633 100;
BA_ "GenMsgILSupport" BO_ 1633 "Yes";
BA_ "GenMsgSendType" BO_ 1633 "Cyclic";
BA_ "VFrameFormat" BO_ 1633 "StandardCAN_FD";
BA_ "GenMsgCycleTime" BO_ 345 100;
BA_ "GenMsgDelayTime" BO_ 345 10;
BA_ "GenMsgILSupport" BO_ 345 "Yes";
BA_ "GenMsgSendType" BO_ 345 "Cyclic";
BA_ "VFrameFormat" BO_ 345 "StandardCAN_FD";
BA_ "GenMsgCycleTime" BO_ 2589283607 200;
BA_ "GenMsgDelayTime" BO_ 2589283607 100;
BA_ "GenMsgILSupport" BO_ 2589283607 "Yes";
BA_ "GenMsgNrOfRepetition" BO_ 2589283607 5;
BA_ "GenMsgPDUConstants" BO_ 2589283607 "0xfb,0xee,0x5d,0x2d,0xfa,0x85,0x27,0xd4,0xc9,0xc4,0xa5,0x45,0x5f,0x76,0xa3,0x89";
BA_ "GenMsgSendType" BO_ 2589283607 "Cyclic";
BA_ "VFrameFormat" BO_ 2589283607 "ExtendedCAN_FD";
BA_ "GenMsgCycleTime" BO_ 219 1000;
BA_ "GenMsgCycleTimeFast" BO_ 219 20;
BA_ "GenMsgDelayTime" BO_ 219 20;
BA_ "GenMsgILSupport" BO_ 219 "Yes";
BA_ "GenMsgNrOfRepetition" BO_ 219 5;
BA_ "GenMsgPDUConstants" BO_ 219 "0x09,0xfa,0xca,0x8e,0x62,0xd5,0xd1,0xf0,0x31,0xa0,0xaf,0xda,0x4d,0x1a,0x0a,0x97";
BA_ "GenMsgSendType" BO_ 219 "Cyclic";
BA_ "VFrameFormat" BO_ 219 "StandardCAN_FD";
BA_ "MsgType" BO_ 2536767264 "BAP";
BA_ "VFrameFormat" BO_ 2536767264 "ExtendedCAN_FD";
BA_ "MsgType" BO_ 2536767280 "BAP";
BA_ "VFrameFormat" BO_ 2536767280 "ExtendedCAN_FD";
BA_ "GenMsgCycleTimeFast" BO_ 2536717313 80;
BA_ "GenMsgSendType" BO_ 2536717313 "IfActive";
BA_ "MsgType" BO_ 2536717313 "BAP";
BA_ "VFrameFormat" BO_ 2536717313 "ExtendedCAN_FD";
BA_ "GenMsgCycleTimeFast" BO_ 2536717314 80;
BA_ "GenMsgSendType" BO_ 2536717314 "IfActive";
BA_ "MsgType" BO_ 2536717314 "BAP";
BA_ "VFrameFormat" BO_ 2536717314 "ExtendedCAN_FD";
BA_ "GenMsgCycleTime" BO_ 2536717328 1000;
BA_ "GenMsgCycleTimeFast" BO_ 2536717328 50;
BA_ "GenMsgSendType" BO_ 2536717328 "IfActive";
BA_ "MsgType" BO_ 2536717328 "BAP";
BA_ "VFrameFormat" BO_ 2536717328 "ExtendedCAN_FD";
BA_ "GenMsgCycleTimeFast" BO_ 2536709120 80;
BA_ "GenMsgSendType" BO_ 2536709120 "IfActive";
BA_ "MsgType" BO_ 2536709120 "BAP";
BA_ "VFrameFormat" BO_ 2536709120 "ExtendedCAN_FD";
BA_ "GenMsgCycleTime" BO_ 2536709136 1000;
BA_ "GenMsgCycleTimeFast" BO_ 2536709136 50;
BA_ "GenMsgSendType" BO_ 2536709136 "IfActive";
BA_ "MsgType" BO_ 2536709136 "BAP";
BA_ "VFrameFormat" BO_ 2536709136 "ExtendedCAN_FD";
BA_ "GenMsgCycleTime" BO_ 869 50;
BA_ "GenMsgILSupport" BO_ 869 "Yes";
BA_ "GenMsgSendType" BO_ 869 "Cyclic";
BA_ "VFrameFormat" BO_ 869 "StandardCAN_FD";
BA_ "GenMsgCycleTime" BO_ 1442 500;
BA_ "GenMsgCycleTimeFast" BO_ 1442 100;
BA_ "GenMsgDelayTime" BO_ 1442 20;
BA_ "GenMsgILSupport" BO_ 1442 "Yes";
BA_ "GenMsgNrOfRepetition" BO_ 1442 5;
BA_ "GenMsgPDUConstants" BO_ 1442 "0xeb,0x4c,0x44,0xaf,0x21,0x8d,0x01,0x58,0xfa,0x93,0xdb,0x89,0x15,0x10,0x4a,0x61";
BA_ "GenMsgSendType" BO_ 1442 "Cyclic";
BA_ "VFrameFormat" BO_ 1442 "StandardCAN_FD";
BA_ "GenMsgCycleTime" BO_ 2527679654 200;
BA_ "GenMsgILSupport" BO_ 2527679654 "Yes";
BA_ "GenMsgPDUConstants" BO_ 2527679654 "0x79,0xb9,0x67,0xad,0xd5,0xf7,0x70,0xaa,0x44,0x61,0x5a,0xdc,0x26,0xb4,0xd2,0xc3";
BA_ "GenMsgSendType" BO_ 2527679654 "Cyclic";
BA_ "VFrameFormat" BO_ 2527679654 "ExtendedCAN_FD";
BA_ "GenMsgCycleTime" BO_ 207 10;
BA_ "GenMsgILSupport" BO_ 207 "Yes";
BA_ "GenMsgPDUConstants" BO_ 207 "0xee,0x80,0x6e,0x4e,0x29,0xc6,0x92,0xc0,0x65,0xaa,0x3a,0xa1,0x8f,0xcd,0xe6,0x90";
BA_ "GenMsgSendType" BO_ 207 "Cyclic";
BA_ "VFrameFormat" BO_ 207 "StandardCAN_FD";
BA_ "GenMsgCycleTime" BO_ 2463978704 100;
BA_ "GenMsgILSupport" BO_ 2463978704 "Yes";
BA_ "GenMsgSendType" BO_ 2463978704 "Cyclic";
BA_ "VFrameFormat" BO_ 2463978704 "ExtendedCAN_FD";
BA_ "GenMsgCycleTime" BO_ 2463978705 100;
BA_ "GenMsgILSupport" BO_ 2463978705 "Yes";
BA_ "GenMsgSendType" BO_ 2463978705 "Cyclic";
BA_ "VFrameFormat" BO_ 2463978705 "ExtendedCAN_FD";
BA_ "GenMsgCycleTime" BO_ 2589283664 500;
BA_ "GenMsgILSupport" BO_ 2589283664 "Yes";
BA_ "GenMsgSendType" BO_ 2589283664 "Cyclic";
BA_ "VFrameFormat" BO_ 2589283664 "ExtendedCAN_FD";
BA_ "GenMsgCycleTime" BO_ 2589283665 500;
BA_ "GenMsgILSupport" BO_ 2589283665 "Yes";
BA_ "GenMsgSendType" BO_ 2589283665 "Cyclic";
BA_ "VFrameFormat" BO_ 2589283665 "ExtendedCAN_FD";
BA_ "GenMsgCycleTime" BO_ 2589283760 1000;
BA_ "GenMsgILSupport" BO_ 2589283760 "Yes";
BA_ "GenMsgSendType" BO_ 2589283760 "Cyclic";
BA_ "VFrameFormat" BO_ 2589283760 "ExtendedCAN_FD";
BA_ "GenMsgCycleTime" BO_ 2463978646 1000;
BA_ "GenMsgDelayTime" BO_ 2463978646 50;
BA_ "GenMsgILSupport" BO_ 2463978646 "Yes";
BA_ "GenMsgSendType" BO_ 2463978646 "Cyclic";
BA_ "VFrameFormat" BO_ 2463978646 "ExtendedCAN_FD";
BA_ "GenMsgCycleTime" BO_ 514 20;
BA_ "GenMsgILSupport" BO_ 514 "Yes";
BA_ "GenMsgSendType" BO_ 514 "Cyclic";
BA_ "VFrameFormat" BO_ 514 "StandardCAN_FD";
BA_ "GenMsgCycleTime" BO_ 1485 500;
BA_ "GenMsgCycleTimeFast" BO_ 1485 100;
BA_ "GenMsgDelayTime" BO_ 1485 50;
BA_ "GenMsgILSupport" BO_ 1485 "Yes";
BA_ "GenMsgNrOfRepetition" BO_ 1485 5;
BA_ "GenMsgPDUConstants" BO_ 1485 "0x93,0x04,0x18,0x69,0xce,0x8f,0xb1,0x53,0x40,0x2d,0xe4,0xca,0x90,0x25,0x79,0x8c";
BA_ "GenMsgSendType" BO_ 1485 "Cyclic";
BA_ "VFrameFormat" BO_ 1485 "StandardCAN_FD";
BA_ "GenMsgCycleTime" BO_ 247 10;
BA_ "GenMsgILSupport" BO_ 247 "Yes";
BA_ "GenMsgPDUConstants" BO_ 247 "0x5f,0xa0,0x44,0xd0,0x63,0x59,0x5b,0xa2,0x68,0x04,0x90,0x87,0x52,0x12,0xb4,0x9e";
BA_ "GenMsgSendType" BO_ 247 "Cyclic";
BA_ "VFrameFormat" BO_ 247 "StandardCAN_FD";
BA_ "MsgType" BO_ 2617027088 "EID";
BA_ "CANFD_BRS" BO_ 2617027088 "0";
BA_ "VFrameFormat" BO_ 2617027088 "ExtendedCAN";
BA_ "MsgType" BO_ 2617027072 "EID";
BA_ "CANFD_BRS" BO_ 2617027072 "0";
BA_ "VFrameFormat" BO_ 2617027072 "ExtendedCAN";
BA_ "MsgType" BO_ 2617027073 "EID";
BA_ "CANFD_BRS" BO_ 2617027073 "0";
BA_ "VFrameFormat" BO_ 2617027073 "ExtendedCAN";
BA_ "MsgType" BO_ 2617027074 "EID";
BA_ "CANFD_BRS" BO_ 2617027074 "0";
BA_ "VFrameFormat" BO_ 2617027074 "ExtendedCAN";
BA_ "MsgType" BO_ 2617027075 "EID";
BA_ "CANFD_BRS" BO_ 2617027075 "0";
BA_ "VFrameFormat" BO_ 2617027075 "ExtendedCAN";
BA_ "MsgType" BO_ 2617027076 "EID";
BA_ "CANFD_BRS" BO_ 2617027076 "0";
BA_ "VFrameFormat" BO_ 2617027076 "ExtendedCAN";
BA_ "MsgType" BO_ 2617027077 "EID";
BA_ "CANFD_BRS" BO_ 2617027077 "0";
BA_ "VFrameFormat" BO_ 2617027077 "ExtendedCAN";
BA_ "MsgType" BO_ 2617027078 "EID";
BA_ "CANFD_BRS" BO_ 2617027078 "0";
BA_ "VFrameFormat" BO_ 2617027078 "ExtendedCAN";
BA_ "MsgType" BO_ 2617027079 "EID";
BA_ "CANFD_BRS" BO_ 2617027079 "0";
BA_ "VFrameFormat" BO_ 2617027079 "ExtendedCAN";
BA_ "MsgType" BO_ 2617027080 "EID";
BA_ "CANFD_BRS" BO_ 2617027080 "0";
BA_ "VFrameFormat" BO_ 2617027080 "ExtendedCAN";
BA_ "MsgType" BO_ 2617027081 "EID";
BA_ "CANFD_BRS" BO_ 2617027081 "0";
BA_ "VFrameFormat" BO_ 2617027081 "ExtendedCAN";
BA_ "MsgType" BO_ 2617027082 "EID";
BA_ "CANFD_BRS" BO_ 2617027082 "0";
BA_ "VFrameFormat" BO_ 2617027082 "ExtendedCAN";
BA_ "MsgType" BO_ 2617027083 "EID";
BA_ "CANFD_BRS" BO_ 2617027083 "0";
BA_ "VFrameFormat" BO_ 2617027083 "ExtendedCAN";
BA_ "MsgType" BO_ 2617154048 "EID";
BA_ "VFrameFormat" BO_ 2617154048 "ExtendedCAN_FD";
BA_ "MsgType" BO_ 2617154049 "EID";
BA_ "VFrameFormat" BO_ 2617154049 "ExtendedCAN_FD";
BA_ "MsgType" BO_ 2617154050 "EID";
BA_ "VFrameFormat" BO_ 2617154050 "ExtendedCAN_FD";
BA_ "MsgType" BO_ 2617154051 "EID";
BA_ "VFrameFormat" BO_ 2617154051 "ExtendedCAN_FD";
BA_ "MsgType" BO_ 2617154052 "EID";
BA_ "VFrameFormat" BO_ 2617154052 "ExtendedCAN_FD";
BA_ "MsgType" BO_ 2617154053 "EID";
BA_ "VFrameFormat" BO_ 2617154053 "ExtendedCAN_FD";
BA_ "DiagRequest" BO_ 2549876269 "Yes";
BA_ "MsgType" BO_ 2549876269 "ISO-TP";
BA_ "VFrameFormat" BO_ 2549876269 "ExtendedCAN_FD";
BA_ "DiagResponse" BO_ 2550007341 "Yes";
BA_ "MsgType" BO_ 2550007341 "ISO-TP";
BA_ "VFrameFormat" BO_ 2550007341 "ExtendedCAN_FD";
BA_ "GenMsgCycleTime" BO_ 1714 1000;
BA_ "GenMsgILSupport" BO_ 1714 "Yes";
BA_ "GenMsgSendType" BO_ 1714 "Cyclic";
BA_ "VFrameFormat" BO_ 1714 "StandardCAN_FD";
BA_ "GenMsgCycleTime" BO_ 851 80;
BA_ "GenMsgILSupport" BO_ 851 "Yes";
BA_ "GenMsgPDUConstants" BO_ 851 "0x3a,0x97,0x6b,0x70,0x1e,0x84,0xe1,0xb4,0xde,0xb8,0x03,0xe7,0x33,0x20,0x3f,0x7c";
BA_ "GenMsgSendType" BO_ 851 "Cyclic";
BA_ "VFrameFormat" BO_ 851 "StandardCAN_FD";
BA_ "GenMsgCycleTime" BO_ 1520 200;
BA_ "GenMsgDelayTime" BO_ 1520 50;
BA_ "GenMsgILSupport" BO_ 1520 "Yes";
BA_ "GenMsgSendType" BO_ 1520 "Cyclic";
BA_ "VFrameFormat" BO_ 1520 "StandardCAN_FD";
BA_ "GenMsgCycleTime" BO_ 420 500;
BA_ "GenMsgCycleTimeFast" BO_ 420 20;
BA_ "GenMsgDelayTime" BO_ 420 20;
BA_ "GenMsgILSupport" BO_ 420 "Yes";
BA_ "GenMsgNrOfRepetition" BO_ 420 5;
BA_ "GenMsgPDUConstants" BO_ 420 "0x69,0xbb,0x54,0xe6,0x4e,0x46,0x8d,0x7b,0xea,0x87,0xe9,0xb3,0x63,0xce,0xf8,0xbf";
BA_ "GenMsgSendType" BO_ 420 "Cyclic";
BA_ "VFrameFormat" BO_ 420 "StandardCAN_FD";
BA_ "GenMsgCycleTime" BO_ 374 20;
BA_ "GenMsgILSupport" BO_ 374 "Yes";
BA_ "GenMsgPDUConstants" BO_ 374 "0x3c,0x60,0xeb,0x76,0x91,0x27,0x04,0x02,0xa4,0x3a,0x3f,0xa8,0x24,0x32,0x38,0x51";
BA_ "GenMsgSendType" BO_ 374 "Cyclic";
BA_ "VFrameFormat" BO_ 374 "StandardCAN_FD";
BA_ "GenMsgCycleTime" BO_ 1603 1000;
BA_ "GenMsgDelayTime" BO_ 1603 100;
BA_ "GenMsgILSupport" BO_ 1603 "Yes";
BA_ "GenMsgSendType" BO_ 1603 "Cyclic";
BA_ "VFrameFormat" BO_ 1603 "StandardCAN_FD";
BA_ "GenMsgCycleTime" BO_ 192 10;
BA_ "GenMsgILSupport" BO_ 192 "Yes";
BA_ "GenMsgPDUConstants" BO_ 192 "0x2f,0x44,0x72,0xd3,0x07,0xf2,0x39,0x09,0x8d,0x6f,0x57,0x20,0x37,0xf9,0x9b,0xfa";
BA_ "GenMsgSendType" BO_ 192 "Cyclic";
BA_ "VFrameFormat" BO_ 192 "StandardCAN_FD";
BA_ "GenMsgCycleTime" BO_ 2463978673 100;
BA_ "GenMsgILSupport" BO_ 2463978673 "Yes";
BA_ "GenMsgSendType" BO_ 2463978673 "Cyclic";
BA_ "VFrameFormat" BO_ 2463978673 "ExtendedCAN_FD";
BA_ "GenMsgCycleTime" BO_ 2589283657 500;
BA_ "GenMsgILSupport" BO_ 2589283657 "Yes";
BA_ "GenMsgSendType" BO_ 2589283657 "Cyclic";
BA_ "VFrameFormat" BO_ 2589283657 "ExtendedCAN_FD";
BA_ "GenMsgCycleTime" BO_ 184 500;
BA_ "GenMsgDelayTime" BO_ 184 20;
BA_ "GenMsgILSupport" BO_ 184 "Yes";
BA_ "GenMsgSendType" BO_ 184 "Cyclic";
BA_ "VFrameFormat" BO_ 184 "StandardCAN_FD";
BA_ "GenMsgCycleTime" BO_ 2527679712 1000;
BA_ "GenMsgILSupport" BO_ 2527679712 "Yes";
BA_ "GenMsgSendType" BO_ 2527679712 "Cyclic";
BA_ "VFrameFormat" BO_ 2527679712 "ExtendedCAN_FD";
BA_ "GenMsgCycleTime" BO_ 193 10;
BA_ "GenMsgILSupport" BO_ 193 "Yes";
BA_ "GenMsgPDUConstants" BO_ 193 "0xd7,0x12,0x85,0x7e,0x0b,0x34,0xfa,0x16,0x7a,0x25,0x2d,0x8f,0x04,0x8e,0x5d,0x35";
BA_ "GenMsgSendType" BO_ 193 "Cyclic";
BA_ "VFrameFormat" BO_ 193 "StandardCAN_FD";
BA_ "GenMsgCycleTime" BO_ 2463978674 100;
BA_ "GenMsgILSupport" BO_ 2463978674 "Yes";
BA_ "GenMsgSendType" BO_ 2463978674 "Cyclic";
BA_ "VFrameFormat" BO_ 2463978674 "ExtendedCAN_FD";
BA_ "GenMsgCycleTime" BO_ 2589283660 500;
BA_ "GenMsgILSupport" BO_ 2589283660 "Yes";
BA_ "GenMsgSendType" BO_ 2589283660 "Cyclic";
BA_ "VFrameFormat" BO_ 2589283660 "ExtendedCAN_FD";
BA_ "GenMsgCycleTime" BO_ 199 500;
BA_ "GenMsgDelayTime" BO_ 199 20;
BA_ "GenMsgILSupport" BO_ 199 "Yes";
BA_ "GenMsgSendType" BO_ 199 "Cyclic";
BA_ "VFrameFormat" BO_ 199 "StandardCAN_FD";
BA_ "GenMsgCycleTime" BO_ 2527679713 1000;
BA_ "GenMsgILSupport" BO_ 2527679713 "Yes";
BA_ "GenMsgSendType" BO_ 2527679713 "Cyclic";
BA_ "VFrameFormat" BO_ 2527679713 "ExtendedCAN_FD";
BA_ "GenMsgCycleTime" BO_ 2589283649 200;
BA_ "GenMsgILSupport" BO_ 2589283649 "Yes";
BA_ "GenMsgPDUConstants" BO_ 2589283649 "0x3e,0xb4,0x25,0xc1,0x31,0x1f,0xf1,0xd7,0xb1,0xbe,0xcc,0xe0,0x0f,0x46,0x51,0xb2";
BA_ "GenMsgSendType" BO_ 2589283649 "Cyclic";
BA_ "VFrameFormat" BO_ 2589283649 "ExtendedCAN_FD";
BA_ "GenMsgCycleTime" BO_ 608 50;
BA_ "GenMsgILSupport" BO_ 608 "Yes";
BA_ "GenMsgSendType" BO_ 608 "Cyclic";
BA_ "VFrameFormat" BO_ 608 "StandardCAN_FD";
BA_ "GenMsgCycleTime" BO_ 2589283751 500;
BA_ "GenMsgILSupport" BO_ 2589283751 "Yes";
BA_ "GenMsgSendType" BO_ 2589283751 "Cyclic";
BA_ "VFrameFormat" BO_ 2589283751 "ExtendedCAN_FD";
BA_ "GenMsgCycleTime" BO_ 2527679687 2000;
BA_ "GenMsgDelayTime" BO_ 2527679687 100;
BA_ "GenMsgILSupport" BO_ 2527679687 "Yes";
BA_ "GenMsgSendType" BO_ 2527679687 "Cyclic";
BA_ "VFrameFormat" BO_ 2527679687 "ExtendedCAN_FD";
BA_ "GenMsgCycleTime" BO_ 258 20;
BA_ "GenMsgILSupport" BO_ 258 "Yes";
BA_ "GenMsgPDUConstants" BO_ 258 "0xd7,0x12,0x85,0x7e,0x0b,0x34,0xfa,0x16,0x7a,0x25,0x2d,0x8f,0x04,0x8e,0x5d,0x35";
BA_ "GenMsgSendType" BO_ 258 "Cyclic";
BA_ "VFrameFormat" BO_ 258 "StandardCAN_FD";
BA_ "GenMsgCycleTime" BO_ 252 10;
BA_ "GenMsgILSupport" BO_ 252 "Yes";
BA_ "GenMsgPDUConstants" BO_ 252 "0x77,0x5c,0xa0,0x89,0x4b,0x7c,0xbb,0xd6,0x1f,0x6c,0x4f,0xf6,0x20,0x2b,0x43,0xdd";
BA_ "GenMsgSendType" BO_ 252 "Cyclic";
BA_ "VFrameFormat" BO_ 252 "StandardCAN_FD";
BA_ "GenMsgCycleTime" BO_ 2463978647 100;
BA_ "GenMsgILSupport" BO_ 2463978647 "Yes";
BA_ "GenMsgSendType" BO_ 2463978647 "Cyclic";
BA_ "VFrameFormat" BO_ 2463978647 "ExtendedCAN_FD";
BA_ "GenMsgCycleTime" BO_ 2527679683 2000;
BA_ "GenMsgDelayTime" BO_ 2527679683 100;
BA_ "GenMsgILSupport" BO_ 2527679683 "Yes";
BA_ "GenMsgSendType" BO_ 2527679683 "Cyclic";
BA_ "VFrameFormat" BO_ 2527679683 "ExtendedCAN_FD";
BA_ "GenMsgChkConstant" BO_ 278 172;
BA_ "GenMsgCycleTime" BO_ 278 20;
BA_ "GenMsgILSupport" BO_ 278 "Yes";
BA_ "GenMsgPDUConstants" BO_ 278 "0xac,0xac,0xac,0xac,0xac,0xac,0xac,0xac,0xac,0xac,0xac,0xac,0xac,0xac,0xac,0xac";
BA_ "GenMsgSendType" BO_ 278 "Cyclic";
BA_ "VFrameFormat" BO_ 278 "StandardCAN_FD";
BA_ "GenMsgCycleTime" BO_ 1629 1000;
BA_ "GenMsgDelayTime" BO_ 1629 200;
BA_ "GenMsgILSupport" BO_ 1629 "Yes";
BA_ "GenMsgPDUConstants" BO_ 1629 "0xac,0xb3,0xab,0xeb,0x7a,0xe1,0x3b,0xf7,0x73,0xba,0x7c,0x9e,0x06,0x5f,0x02,0xd9";
BA_ "GenMsgSendType" BO_ 1629 "Cyclic";
BA_ "VFrameFormat" BO_ 1629 "StandardCAN_FD";
BA_ "GenMsgCycleTime" BO_ 253 20;
BA_ "GenMsgILSupport" BO_ 253 "Yes";
BA_ "GenMsgPDUConstants" BO_ 253 "0xb4,0xef,0xf8,0x49,0x1e,0xe5,0xc2,0xc0,0x97,0x19,0x3c,0xc9,0xf1,0x98,0xd6,0x61";
BA_ "GenMsgSendType" BO_ 253 "Cyclic";
BA_ "VFrameFormat" BO_ 253 "StandardCAN_FD";
BA_ "GenMsgCycleTime" BO_ 795 50;
BA_ "GenMsgILSupport" BO_ 795 "Yes";
BA_ "GenMsgPDUConstants" BO_ 795 "0x67,0x8a,0xae,0x22,0x4d,0xd0,0x51,0x80,0x5c,0xb9,0xce,0x1e,0xdf,0x02,0x2d,0xd4";
BA_ "GenMsgSendType" BO_ 795 "Cyclic";
BA_ "VFrameFormat" BO_ 795 "StandardCAN_FD";
BA_ "GenMsgCycleTime" BO_ 2589283617 1000;
BA_ "GenMsgDelayTime" BO_ 2589283617 50;
BA_ "GenMsgILSupport" BO_ 2589283617 "Yes";
BA_ "GenMsgPDUConstants" BO_ 2589283617 "0xad,0xbd,0x5e,0x44,0x5b,0x90,0xb4,0x8d,0x9a,0x74,0xba,0xfa,0x2b,0x91,0xe2,0x89";
BA_ "GenMsgSendType" BO_ 2589283617 "Cyclic";
BA_ "VFrameFormat" BO_ 2589283617 "ExtendedCAN_FD";
BA_ "GenMsgCycleTime" BO_ 2527679668 500;
BA_ "GenMsgDelayTime" BO_ 2527679668 100;
BA_ "GenMsgILSupport" BO_ 2527679668 "Yes";
BA_ "GenMsgSendType" BO_ 2527679668 "Cyclic";
BA_ "VFrameFormat" BO_ 2527679668 "ExtendedCAN_FD";
BA_ "GenMsgCycleTime" BO_ 2527679740 200;
BA_ "GenMsgDelayTime" BO_ 2527679740 50;
BA_ "GenMsgILSupport" BO_ 2527679740 "Yes";
BA_ "GenMsgSendType" BO_ 2527679740 "Cyclic";
BA_ "VFrameFormat" BO_ 2527679740 "ExtendedCAN_FD";
BA_ "GenMsgCycleTime" BO_ 2589283684 1000;
BA_ "GenMsgDelayTime" BO_ 2589283684 200;
BA_ "GenMsgILSupport" BO_ 2589283684 "Yes";
BA_ "GenMsgSendType" BO_ 2589283684 "Cyclic";
BA_ "VFrameFormat" BO_ 2589283684 "ExtendedCAN_FD";
BA_ "MsgType" BO_ 2549875574 "ISO-TP";
BA_ "VFrameFormat" BO_ 2549875574 "ExtendedCAN_FD";
BA_ "MsgType" BO_ 2550006646 "ISO-TP";
BA_ "VFrameFormat" BO_ 2550006646 "ExtendedCAN_FD";
BA_ "GenMsgCycleTime" BO_ 987 100;
BA_ "GenMsgDelayTime" BO_ 987 10;
BA_ "GenMsgILSupport" BO_ 987 "Yes";
BA_ "GenMsgSendType" BO_ 987 "Cyclic";
BA_ "VFrameFormat" BO_ 987 "StandardCAN_FD";
BA_ "GenMsgCycleTime" BO_ 173 10;
BA_ "GenMsgILSupport" BO_ 173 "Yes";
BA_ "GenMsgPDUConstants" BO_ 173 "0x3f,0x69,0x39,0xdc,0x94,0xf9,0x14,0x64,0xd8,0x6a,0x34,0xce,0xa2,0x55,0xb5,0x2c";
BA_ "GenMsgSendType" BO_ 173 "Cyclic";
BA_ "VFrameFormat" BO_ 173 "StandardCAN_FD";
BA_ "GenMsgChkConstant" BO_ 324 227;
BA_ "GenMsgCycleTime" BO_ 324 20;
BA_ "GenMsgILSupport" BO_ 324 "Yes";
BA_ "GenMsgPDUConstants" BO_ 324 "0xe3,0xe3,0xe3,0xe3,0xe3,0xe3,0xe3,0xe3,0xe3,0xe3,0xe3,0xe3,0xe3,0xe3,0xe3,0xe3";
BA_ "GenMsgSendType" BO_ 324 "Cyclic";
BA_ "VFrameFormat" BO_ 324 "StandardCAN_FD";
BA_ "GenMsgCycleTime" BO_ 299 30;
BA_ "GenMsgILSupport" BO_ 299 "Yes";
BA_ "GenMsgPDUConstants" BO_ 299 "0x6a,0x38,0xb4,0x27,0x22,0xef,0xe1,0xbb,0xf8,0x80,0x84,0x49,0xc7,0x9e,0x1e,0x2b";
BA_ "GenMsgSendType" BO_ 299 "Cyclic";
BA_ "VFrameFormat" BO_ 299 "StandardCAN_FD";
BA_ "GenMsgCycleTime" BO_ 1452 100;
BA_ "GenMsgILSupport" BO_ 1452 "Yes";
BA_ "GenMsgSendType" BO_ 1452 "Cyclic";
BA_ "VFrameFormat" BO_ 1452 "StandardCAN_FD";
BA_ "GenMsgCycleTime" BO_ 1385 500;
BA_ "GenMsgDelayTime" BO_ 1385 50;
BA_ "GenMsgILSupport" BO_ 1385 "Yes";
BA_ "GenMsgSendType" BO_ 1385 "Cyclic";
BA_ "VFrameFormat" BO_ 1385 "StandardCAN_FD";
BA_ "GenMsgCycleTime" BO_ 1283 100;
BA_ "GenMsgDelayTime" BO_ 1283 10;
BA_ "GenMsgILSupport" BO_ 1283 "Yes";
BA_ "GenMsgPDUConstants" BO_ 1283 "0xed,0xd6,0x96,0x63,0xa5,0x12,0xd5,0x9a,0x1e,0x0d,0x24,0xcd,0x8c,0xa6,0x2f,0x41";
BA_ "GenMsgSendType" BO_ 1283 "Cyclic";
BA_ "VFrameFormat" BO_ 1283 "StandardCAN_FD";
BA_ "GenMsgCycleTime" BO_ 2463978813 100;
BA_ "GenMsgDelayTime" BO_ 2463978813 10;
BA_ "GenMsgILSupport" BO_ 2463978813 "Yes";
BA_ "GenMsgPDUConstants" BO_ 2463978813 "0x1d,0x82,0x7b,0x79,0xa5,0xee,0x3a,0xb9,0xb7,0xf9,0xe4,0x67,0x7f,0x97,0x11,0xad";
BA_ "GenMsgSendType" BO_ 2463978813 "Cyclic";
BA_ "VFrameFormat" BO_ 2463978813 "ExtendedCAN_FD";
BA_ "GenMsgCycleTime" BO_ 626 100;
BA_ "GenMsgDelayTime" BO_ 626 10;
BA_ "GenMsgILSupport" BO_ 626 "Yes";
BA_ "GenMsgSendType" BO_ 626 "Cyclic";
BA_ "VFrameFormat" BO_ 626 "StandardCAN_FD";
BA_ "GenMsgILSupport" BO_ 268 "Yes";
BA_ "VFrameFormat" BO_ 268 "StandardCAN_FD";
BA_ "GenMsgILSupport" BO_ 23 "Yes";
BA_ "VFrameFormat" BO_ 23 "StandardCAN_FD";
BA_ "GenMsgILSupport" BO_ 25 "Yes";
BA_ "VFrameFormat" BO_ 25 "StandardCAN_FD";
BA_ "GenMsgCycleTime" BO_ 2527679583 1000;
BA_ "GenMsgCycleTimeFast" BO_ 2527679583 100;
BA_ "GenMsgDelayTime" BO_ 2527679583 50;
BA_ "GenMsgILSupport" BO_ 2527679583 "Yes";
BA_ "GenMsgNrOfRepetition" BO_ 2527679583 5;
BA_ "GenMsgSendType" BO_ 2527679583 "Cyclic";
BA_ "VFrameFormat" BO_ 2527679583 "ExtendedCAN_FD";
BA_ "DiagRequest" BO_ 1813 "Yes";
BA_ "MsgType" BO_ 1813 "ISO-TP";
BA_ "VFrameFormat" BO_ 1813 "StandardCAN_FD";
BA_ "DiagResponse" BO_ 1919 "Yes";
BA_ "MsgType" BO_ 1919 "ISO-TP";
BA_ "VFrameFormat" BO_ 1919 "StandardCAN_FD";
BA_ "DiagState" BO_ 1792 "Yes";
BA_ "MsgType" BO_ 1792 "ISO-TP";
BA_ "VFrameFormat" BO_ 1792 "StandardCAN_FD";
BA_ "DiagRequest" BO_ 2621440021 "Yes";
BA_ "MsgType" BO_ 2621440021 "ISO-TP";
BA_ "VFrameFormat" BO_ 2621440021 "ExtendedCAN_FD";
BA_ "DiagResponse" BO_ 2621571093 "Yes";
BA_ "MsgType" BO_ 2621571093 "ISO-TP";
BA_ "VFrameFormat" BO_ 2621571093 "ExtendedCAN_FD";
BA_ "DiagRequest" BO_ 2549874812 "Yes";
BA_ "MsgType" BO_ 2549874812 "ISO-TP";
BA_ "VFrameFormat" BO_ 2549874812 "ExtendedCAN_FD";
BA_ "DiagRequest" BO_ 2621440124 "Yes";
BA_ "MsgType" BO_ 2621440124 "ISO-TP";
BA_ "VFrameFormat" BO_ 2621440124 "ExtendedCAN_FD";
BA_ "DiagResponse" BO_ 2550005884 "Yes";
BA_ "MsgType" BO_ 2550005884 "ISO-TP";
BA_ "VFrameFormat" BO_ 2550005884 "ExtendedCAN_FD";
BA_ "DiagResponse" BO_ 2621571196 "Yes";
BA_ "MsgType" BO_ 2621571196 "ISO-TP";
BA_ "VFrameFormat" BO_ 2621571196 "ExtendedCAN_FD";
BA_ "DiagRequest" BO_ 2549874872 "Yes";
BA_ "MsgType" BO_ 2549874872 "ISO-TP";
BA_ "VFrameFormat" BO_ 2549874872 "ExtendedCAN_FD";
BA_ "DiagRequest" BO_ 2621440184 "Yes";
BA_ "MsgType" BO_ 2621440184 "ISO-TP";
BA_ "VFrameFormat" BO_ 2621440184 "ExtendedCAN_FD";
BA_ "DiagResponse" BO_ 2550005944 "Yes";
BA_ "MsgType" BO_ 2550005944 "ISO-TP";
BA_ "VFrameFormat" BO_ 2550005944 "ExtendedCAN_FD";
BA_ "DiagResponse" BO_ 2621571256 "Yes";
BA_ "MsgType" BO_ 2621571256 "ISO-TP";
BA_ "VFrameFormat" BO_ 2621571256 "ExtendedCAN_FD";
BA_ "DiagState" BO_ 2621505536 "Yes";
BA_ "MsgType" BO_ 2621505536 "ISO-TP";
BA_ "VFrameFormat" BO_ 2621505536 "ExtendedCAN_FD";
BA_ "DiagRequest" BO_ 2549874806 "Yes";
BA_ "MsgType" BO_ 2549874806 "ISO-TP";
BA_ "VFrameFormat" BO_ 2549874806 "ExtendedCAN_FD";
BA_ "DiagRequest" BO_ 2621440118 "Yes";
BA_ "MsgType" BO_ 2621440118 "ISO-TP";
BA_ "VFrameFormat" BO_ 2621440118 "ExtendedCAN_FD";
BA_ "DiagResponse" BO_ 2550005878 "Yes";
BA_ "MsgType" BO_ 2550005878 "ISO-TP";
BA_ "VFrameFormat" BO_ 2550005878 "ExtendedCAN_FD";
BA_ "DiagResponse" BO_ 2621571190 "Yes";
BA_ "MsgType" BO_ 2621571190 "ISO-TP";
BA_ "VFrameFormat" BO_ 2621571190 "ExtendedCAN_FD";
BA_ "GenMsgCycleTime" BO_ 2527679684 2000;
BA_ "GenMsgDelayTime" BO_ 2527679684 100;
BA_ "GenMsgILSupport" BO_ 2527679684 "Yes";
BA_ "GenMsgSendType" BO_ 2527679684 "Cyclic";
BA_ "VFrameFormat" BO_ 2527679684 "ExtendedCAN_FD";
BA_ "GenMsgChkConstant" BO_ 960 195;
BA_ "GenMsgCycleTime" BO_ 960 100;
BA_ "GenMsgDelayTime" BO_ 960 10;
BA_ "GenMsgILSupport" BO_ 960 "Yes";
BA_ "GenMsgPDUConstants" BO_ 960 "0xc3,0xc3,0xc3,0xc3,0xc3,0xc3,0xc3,0xc3,0xc3,0xc3,0xc3,0xc3,0xc3,0xc3,0xc3,0xc3";
BA_ "GenMsgSendType" BO_ 960 "Cyclic";
BA_ "VFrameFormat" BO_ 960 "StandardCAN_FD";
BA_ "GenMsgCycleTime" BO_ 2463978753 1000;
BA_ "GenMsgCycleTimeFast" BO_ 2463978753 100;
BA_ "GenMsgDelayTime" BO_ 2463978753 100;
BA_ "GenMsgILSupport" BO_ 2463978753 "Yes";
BA_ "GenMsgNrOfRepetition" BO_ 2463978753 5;
BA_ "GenMsgSendType" BO_ 2463978753 "Cyclic";
BA_ "VFrameFormat" BO_ 2463978753 "ExtendedCAN_FD";
BA_ "GenMsgCycleTime" BO_ 1420 1000;
BA_ "GenMsgCycleTimeFast" BO_ 1420 20;
BA_ "GenMsgDelayTime" BO_ 1420 10;
BA_ "GenMsgILSupport" BO_ 1420 "Yes";
BA_ "GenMsgNrOfRepetition" BO_ 1420 5;
BA_ "GenMsgPDUConstants" BO_ 1420 "0x9b,0xb5,0x9d,0x06,0x01,0xe7,0x8f,0xc1,0xd0,0x10,0x47,0xe9,0xd3,0xca,0x05,0xf0";
BA_ "GenMsgSendType" BO_ 1420 "Cyclic";
BA_ "VFrameFormat" BO_ 1420 "StandardCAN_FD";
BA_ "GenMsgCycleTime" BO_ 333 20;
BA_ "GenMsgILSupport" BO_ 333 "Yes";
BA_ "GenMsgPDUConstants" BO_ 333 "0x1a,0x65,0x81,0x96,0xc0,0xdf,0x11,0x92,0xd3,0x61,0xc6,0x95,0x8c,0x29,0x21,0xb5";
BA_ "GenMsgSendType" BO_ 333 "Cyclic";
BA_ "VFrameFormat" BO_ 333 "StandardCAN_FD";
BA_ "GenMsgCycleTime" BO_ 2527679682 2000;
BA_ "GenMsgDelayTime" BO_ 2527679682 100;
BA_ "GenMsgILSupport" BO_ 2527679682 "Yes";
BA_ "GenMsgSendType" BO_ 2527679682 "Cyclic";
BA_ "VFrameFormat" BO_ 2527679682 "ExtendedCAN_FD";
BA_ "GenMsgChkConstant" BO_ 64 64;
BA_ "GenMsgCycleTime" BO_ 64 40;
BA_ "GenMsgCycleTimeFast" BO_ 64 10;
BA_ "GenMsgDelayTime" BO_ 64 10;
BA_ "GenMsgILSupport" BO_ 64 "Yes";
BA_ "GenMsgNrOfRepetition" BO_ 64 5;
BA_ "GenMsgPDUConstants" BO_ 64 "0x40,0x40,0x40,0x40,0x40,0x40,0x40,0x40,0x40,0x40,0x40,0x40,0x40,0x40,0x40,0x40";
BA_ "GenMsgSendType" BO_ 64 "Cyclic";
BA_ "CANFD_BRS" BO_ 64 "0";
BA_ "GenMsgChkConstant" BO_ 1312 68;
BA_ "GenMsgCycleTime" BO_ 1312 200;
BA_ "GenMsgDelayTime" BO_ 1312 20;
BA_ "GenMsgILSupport" BO_ 1312 "Yes";
BA_ "GenMsgPDUConstants" BO_ 1312 "0x44,0x44,0x44,0x44,0x44,0x44,0x44,0x44,0x44,0x44,0x44,0x44,0x44,0x44,0x44,0x44";
BA_ "GenMsgSendType" BO_ 1312 "Cyclic";
BA_ "CANFD_BRS" BO_ 1312 "0";
BA_ "GenMsgCycleTime" BO_ 65 1000;
BA_ "GenMsgCycleTimeFast" BO_ 65 10;
BA_ "GenMsgDelayTime" BO_ 65 10;
BA_ "GenMsgILSupport" BO_ 65 "Yes";
BA_ "GenMsgNrOfRepetition" BO_ 65 5;
BA_ "GenMsgPDUConstants" BO_ 65 "0x93,0xb0,0x9d,0xf1,0x09,0xe8,0x88,0x5e,0x36,0xfa,0xa8,0xa1,0x67,0x84,0xca,0x4f";
BA_ "GenMsgSendType" BO_ 65 "Cyclic";
BA_ "CANFD_BRS" BO_ 65 "0";
BA_ "GenMsgCycleTime" BO_ 1349 200;
BA_ "GenMsgDelayTime" BO_ 1349 40;
BA_ "GenMsgILSupport" BO_ 1349 "Yes";
BA_ "GenMsgSendType" BO_ 1349 "Cyclic";
BA_ "CANFD_BRS" BO_ 1349 "0";
BA_ "GenMsgCycleTime" BO_ 2527679722 200;
BA_ "GenMsgILSupport" BO_ 2527679722 "Yes";
BA_ "GenMsgSendType" BO_ 2527679722 "Cyclic";
BA_ "CANFD_BRS" BO_ 2527679722 "0";
BA_ "VFrameFormat" BO_ 2527679722 "ExtendedCAN";
BA_ "GenMsgCycleTime" BO_ 1633 100;
BA_ "GenMsgILSupport" BO_ 1633 "Yes";
BA_ "GenMsgSendType" BO_ 1633 "Cyclic";
BA_ "VFrameFormat" BO_ 1633 "StandardCAN_FD";
BA_ "GenMsgCycleTime" BO_ 345 100;
BA_ "GenMsgDelayTime" BO_ 345 10;
BA_ "GenMsgILSupport" BO_ 345 "Yes";
BA_ "GenMsgSendType" BO_ 345 "Cyclic";
BA_ "VFrameFormat" BO_ 345 "StandardCAN_FD";
BA_ "GenMsgCycleTime" BO_ 2589283607 200;
BA_ "GenMsgDelayTime" BO_ 2589283607 100;
BA_ "GenMsgILSupport" BO_ 2589283607 "Yes";
BA_ "GenMsgNrOfRepetition" BO_ 2589283607 5;
BA_ "GenMsgPDUConstants" BO_ 2589283607 "0xfb,0xee,0x5d,0x2d,0xfa,0x85,0x27,0xd4,0xc9,0xc4,0xa5,0x45,0x5f,0x76,0xa3,0x89";
BA_ "GenMsgSendType" BO_ 2589283607 "Cyclic";
BA_ "VFrameFormat" BO_ 2589283607 "ExtendedCAN_FD";
BA_ "GenMsgCycleTime" BO_ 219 1000;
BA_ "GenMsgCycleTimeFast" BO_ 219 20;
BA_ "GenMsgDelayTime" BO_ 219 20;
BA_ "GenMsgILSupport" BO_ 219 "Yes";
BA_ "GenMsgNrOfRepetition" BO_ 219 5;
BA_ "GenMsgPDUConstants" BO_ 219 "0x09,0xfa,0xca,0x8e,0x62,0xd5,0xd1,0xf0,0x31,0xa0,0xaf,0xda,0x4d,0x1a,0x0a,0x97";
BA_ "GenMsgSendType" BO_ 219 "Cyclic";
BA_ "VFrameFormat" BO_ 219 "StandardCAN_FD";
BA_ "MsgType" BO_ 2536767264 "BAP";
BA_ "VFrameFormat" BO_ 2536767264 "ExtendedCAN_FD";
BA_ "MsgType" BO_ 2536767280 "BAP";
BA_ "VFrameFormat" BO_ 2536767280 "ExtendedCAN_FD";
BA_ "GenMsgCycleTimeFast" BO_ 2536717313 80;
BA_ "GenMsgSendType" BO_ 2536717313 "IfActive";
BA_ "MsgType" BO_ 2536717313 "BAP";
BA_ "VFrameFormat" BO_ 2536717313 "ExtendedCAN_FD";
BA_ "GenMsgCycleTimeFast" BO_ 2536717314 80;
BA_ "GenMsgSendType" BO_ 2536717314 "IfActive";
BA_ "MsgType" BO_ 2536717314 "BAP";
BA_ "VFrameFormat" BO_ 2536717314 "ExtendedCAN_FD";
BA_ "GenMsgCycleTime" BO_ 2536717328 1000;
BA_ "GenMsgCycleTimeFast" BO_ 2536717328 50;
BA_ "GenMsgSendType" BO_ 2536717328 "IfActive";
BA_ "MsgType" BO_ 2536717328 "BAP";
BA_ "VFrameFormat" BO_ 2536717328 "ExtendedCAN_FD";
BA_ "GenMsgCycleTimeFast" BO_ 2536709120 80;
BA_ "GenMsgSendType" BO_ 2536709120 "IfActive";
BA_ "MsgType" BO_ 2536709120 "BAP";
BA_ "VFrameFormat" BO_ 2536709120 "ExtendedCAN_FD";
BA_ "GenMsgCycleTime" BO_ 2536709136 1000;
BA_ "GenMsgCycleTimeFast" BO_ 2536709136 50;
BA_ "GenMsgSendType" BO_ 2536709136 "IfActive";
BA_ "MsgType" BO_ 2536709136 "BAP";
BA_ "VFrameFormat" BO_ 2536709136 "ExtendedCAN_FD";
BA_ "GenMsgCycleTime" BO_ 869 50;
BA_ "GenMsgILSupport" BO_ 869 "Yes";
BA_ "GenMsgSendType" BO_ 869 "Cyclic";
BA_ "VFrameFormat" BO_ 869 "StandardCAN_FD";
BA_ "GenMsgCycleTime" BO_ 1442 500;
BA_ "GenMsgCycleTimeFast" BO_ 1442 100;
BA_ "GenMsgDelayTime" BO_ 1442 20;
BA_ "GenMsgILSupport" BO_ 1442 "Yes";
BA_ "GenMsgNrOfRepetition" BO_ 1442 5;
BA_ "GenMsgPDUConstants" BO_ 1442 "0xeb,0x4c,0x44,0xaf,0x21,0x8d,0x01,0x58,0xfa,0x93,0xdb,0x89,0x15,0x10,0x4a,0x61";
BA_ "GenMsgSendType" BO_ 1442 "Cyclic";
BA_ "VFrameFormat" BO_ 1442 "StandardCAN_FD";
BA_ "GenMsgCycleTime" BO_ 2527679654 200;
BA_ "GenMsgILSupport" BO_ 2527679654 "Yes";
BA_ "GenMsgPDUConstants" BO_ 2527679654 "0x79,0xb9,0x67,0xad,0xd5,0xf7,0x70,0xaa,0x44,0x61,0x5a,0xdc,0x26,0xb4,0xd2,0xc3";
BA_ "GenMsgSendType" BO_ 2527679654 "Cyclic";
BA_ "VFrameFormat" BO_ 2527679654 "ExtendedCAN_FD";
BA_ "GenMsgCycleTime" BO_ 207 10;
BA_ "GenMsgILSupport" BO_ 207 "Yes";
BA_ "GenMsgPDUConstants" BO_ 207 "0xee,0x80,0x6e,0x4e,0x29,0xc6,0x92,0xc0,0x65,0xaa,0x3a,0xa1,0x8f,0xcd,0xe6,0x90";
BA_ "GenMsgSendType" BO_ 207 "Cyclic";
BA_ "VFrameFormat" BO_ 207 "StandardCAN_FD";
BA_ "GenMsgCycleTime" BO_ 2463978704 100;
BA_ "GenMsgILSupport" BO_ 2463978704 "Yes";
BA_ "GenMsgSendType" BO_ 2463978704 "Cyclic";
BA_ "VFrameFormat" BO_ 2463978704 "ExtendedCAN_FD";
BA_ "GenMsgCycleTime" BO_ 2463978705 100;
BA_ "GenMsgILSupport" BO_ 2463978705 "Yes";
BA_ "GenMsgSendType" BO_ 2463978705 "Cyclic";
BA_ "VFrameFormat" BO_ 2463978705 "ExtendedCAN_FD";
BA_ "GenMsgCycleTime" BO_ 2589283664 500;
BA_ "GenMsgILSupport" BO_ 2589283664 "Yes";
BA_ "GenMsgSendType" BO_ 2589283664 "Cyclic";
BA_ "VFrameFormat" BO_ 2589283664 "ExtendedCAN_FD";
BA_ "GenMsgCycleTime" BO_ 2589283665 500;
BA_ "GenMsgILSupport" BO_ 2589283665 "Yes";
BA_ "GenMsgSendType" BO_ 2589283665 "Cyclic";
BA_ "VFrameFormat" BO_ 2589283665 "ExtendedCAN_FD";
BA_ "GenMsgCycleTime" BO_ 2589283760 1000;
BA_ "GenMsgILSupport" BO_ 2589283760 "Yes";
BA_ "GenMsgSendType" BO_ 2589283760 "Cyclic";
BA_ "VFrameFormat" BO_ 2589283760 "ExtendedCAN_FD";
BA_ "GenMsgCycleTime" BO_ 2463978646 1000;
BA_ "GenMsgDelayTime" BO_ 2463978646 50;
BA_ "GenMsgILSupport" BO_ 2463978646 "Yes";
BA_ "GenMsgSendType" BO_ 2463978646 "Cyclic";
BA_ "VFrameFormat" BO_ 2463978646 "ExtendedCAN_FD";
BA_ "GenMsgCycleTime" BO_ 514 20;
BA_ "GenMsgILSupport" BO_ 514 "Yes";
BA_ "GenMsgSendType" BO_ 514 "Cyclic";
BA_ "VFrameFormat" BO_ 514 "StandardCAN_FD";
BA_ "GenMsgCycleTime" BO_ 1485 500;
BA_ "GenMsgCycleTimeFast" BO_ 1485 100;
BA_ "GenMsgDelayTime" BO_ 1485 50;
BA_ "GenMsgILSupport" BO_ 1485 "Yes";
BA_ "GenMsgNrOfRepetition" BO_ 1485 5;
BA_ "GenMsgPDUConstants" BO_ 1485 "0x93,0x04,0x18,0x69,0xce,0x8f,0xb1,0x53,0x40,0x2d,0xe4,0xca,0x90,0x25,0x79,0x8c";
BA_ "GenMsgSendType" BO_ 1485 "Cyclic";
BA_ "VFrameFormat" BO_ 1485 "StandardCAN_FD";
BA_ "GenMsgCycleTime" BO_ 247 10;
BA_ "GenMsgILSupport" BO_ 247 "Yes";
BA_ "GenMsgPDUConstants" BO_ 247 "0x5f,0xa0,0x44,0xd0,0x63,0x59,0x5b,0xa2,0x68,0x04,0x90,0x87,0x52,0x12,0xb4,0x9e";
BA_ "GenMsgSendType" BO_ 247 "Cyclic";
BA_ "VFrameFormat" BO_ 247 "StandardCAN_FD";
BA_ "MsgType" BO_ 2617027088 "EID";
BA_ "CANFD_BRS" BO_ 2617027088 "0";
BA_ "VFrameFormat" BO_ 2617027088 "ExtendedCAN";
BA_ "MsgType" BO_ 2617027072 "EID";
BA_ "CANFD_BRS" BO_ 2617027072 "0";
BA_ "VFrameFormat" BO_ 2617027072 "ExtendedCAN";
BA_ "MsgType" BO_ 2617027073 "EID";
BA_ "CANFD_BRS" BO_ 2617027073 "0";
BA_ "VFrameFormat" BO_ 2617027073 "ExtendedCAN";
BA_ "MsgType" BO_ 2617027074 "EID";
BA_ "CANFD_BRS" BO_ 2617027074 "0";
BA_ "VFrameFormat" BO_ 2617027074 "ExtendedCAN";
BA_ "MsgType" BO_ 2617027075 "EID";
BA_ "CANFD_BRS" BO_ 2617027075 "0";
BA_ "VFrameFormat" BO_ 2617027075 "ExtendedCAN";
BA_ "MsgType" BO_ 2617027076 "EID";
BA_ "CANFD_BRS" BO_ 2617027076 "0";
BA_ "VFrameFormat" BO_ 2617027076 "ExtendedCAN";
BA_ "MsgType" BO_ 2617027077 "EID";
BA_ "CANFD_BRS" BO_ 2617027077 "0";
BA_ "VFrameFormat" BO_ 2617027077 "ExtendedCAN";
BA_ "MsgType" BO_ 2617027078 "EID";
BA_ "CANFD_BRS" BO_ 2617027078 "0";
BA_ "VFrameFormat" BO_ 2617027078 "ExtendedCAN";
BA_ "MsgType" BO_ 2617027079 "EID";
BA_ "CANFD_BRS" BO_ 2617027079 "0";
BA_ "VFrameFormat" BO_ 2617027079 "ExtendedCAN";
BA_ "MsgType" BO_ 2617027080 "EID";
BA_ "CANFD_BRS" BO_ 2617027080 "0";
BA_ "VFrameFormat" BO_ 2617027080 "ExtendedCAN";
BA_ "MsgType" BO_ 2617027081 "EID";
BA_ "CANFD_BRS" BO_ 2617027081 "0";
BA_ "VFrameFormat" BO_ 2617027081 "ExtendedCAN";
BA_ "MsgType" BO_ 2617027082 "EID";
BA_ "CANFD_BRS" BO_ 2617027082 "0";
BA_ "VFrameFormat" BO_ 2617027082 "ExtendedCAN";
BA_ "MsgType" BO_ 2617027083 "EID";
BA_ "CANFD_BRS" BO_ 2617027083 "0";
BA_ "VFrameFormat" BO_ 2617027083 "ExtendedCAN";
BA_ "MsgType" BO_ 2617154048 "EID";
BA_ "VFrameFormat" BO_ 2617154048 "ExtendedCAN_FD";
BA_ "MsgType" BO_ 2617154049 "EID";
BA_ "VFrameFormat" BO_ 2617154049 "ExtendedCAN_FD";
BA_ "MsgType" BO_ 2617154050 "EID";
BA_ "VFrameFormat" BO_ 2617154050 "ExtendedCAN_FD";
BA_ "MsgType" BO_ 2617154051 "EID";
BA_ "VFrameFormat" BO_ 2617154051 "ExtendedCAN_FD";
BA_ "MsgType" BO_ 2617154052 "EID";
BA_ "VFrameFormat" BO_ 2617154052 "ExtendedCAN_FD";
BA_ "MsgType" BO_ 2617154053 "EID";
BA_ "VFrameFormat" BO_ 2617154053 "ExtendedCAN_FD";
BA_ "DiagRequest" BO_ 2549876269 "Yes";
BA_ "MsgType" BO_ 2549876269 "ISO-TP";
BA_ "VFrameFormat" BO_ 2549876269 "ExtendedCAN_FD";
BA_ "DiagResponse" BO_ 2550007341 "Yes";
BA_ "MsgType" BO_ 2550007341 "ISO-TP";
BA_ "VFrameFormat" BO_ 2550007341 "ExtendedCAN_FD";
BA_ "GenMsgCycleTime" BO_ 1714 1000;
BA_ "GenMsgILSupport" BO_ 1714 "Yes";
BA_ "GenMsgSendType" BO_ 1714 "Cyclic";
BA_ "VFrameFormat" BO_ 1714 "StandardCAN_FD";
BA_ "GenMsgCycleTime" BO_ 851 80;
BA_ "GenMsgILSupport" BO_ 851 "Yes";
BA_ "GenMsgPDUConstants" BO_ 851 "0x3a,0x97,0x6b,0x70,0x1e,0x84,0xe1,0xb4,0xde,0xb8,0x03,0xe7,0x33,0x20,0x3f,0x7c";
BA_ "GenMsgSendType" BO_ 851 "Cyclic";
BA_ "VFrameFormat" BO_ 851 "StandardCAN_FD";
BA_ "GenMsgCycleTime" BO_ 1520 200;
BA_ "GenMsgDelayTime" BO_ 1520 50;
BA_ "GenMsgILSupport" BO_ 1520 "Yes";
BA_ "GenMsgSendType" BO_ 1520 "Cyclic";
BA_ "VFrameFormat" BO_ 1520 "StandardCAN_FD";
BA_ "GenMsgCycleTime" BO_ 420 500;
BA_ "GenMsgCycleTimeFast" BO_ 420 20;
BA_ "GenMsgDelayTime" BO_ 420 20;
BA_ "GenMsgILSupport" BO_ 420 "Yes";
BA_ "GenMsgNrOfRepetition" BO_ 420 5;
BA_ "GenMsgPDUConstants" BO_ 420 "0x69,0xbb,0x54,0xe6,0x4e,0x46,0x8d,0x7b,0xea,0x87,0xe9,0xb3,0x63,0xce,0xf8,0xbf";
BA_ "GenMsgSendType" BO_ 420 "Cyclic";
BA_ "VFrameFormat" BO_ 420 "StandardCAN_FD";
BA_ "GenMsgCycleTime" BO_ 374 20;
BA_ "GenMsgILSupport" BO_ 374 "Yes";
BA_ "GenMsgPDUConstants" BO_ 374 "0x3c,0x60,0xeb,0x76,0x91,0x27,0x04,0x02,0xa4,0x3a,0x3f,0xa8,0x24,0x32,0x38,0x51";
BA_ "GenMsgSendType" BO_ 374 "Cyclic";
BA_ "VFrameFormat" BO_ 374 "StandardCAN_FD";
BA_ "GenMsgCycleTime" BO_ 1603 1000;
BA_ "GenMsgDelayTime" BO_ 1603 100;
BA_ "GenMsgILSupport" BO_ 1603 "Yes";
BA_ "GenMsgSendType" BO_ 1603 "Cyclic";
BA_ "VFrameFormat" BO_ 1603 "StandardCAN_FD";
BA_ "GenMsgCycleTime" BO_ 192 10;
BA_ "GenMsgILSupport" BO_ 192 "Yes";
BA_ "GenMsgPDUConstants" BO_ 192 "0x2f,0x44,0x72,0xd3,0x07,0xf2,0x39,0x09,0x8d,0x6f,0x57,0x20,0x37,0xf9,0x9b,0xfa";
BA_ "GenMsgSendType" BO_ 192 "Cyclic";
BA_ "VFrameFormat" BO_ 192 "StandardCAN_FD";
BA_ "GenMsgCycleTime" BO_ 2463978673 100;
BA_ "GenMsgILSupport" BO_ 2463978673 "Yes";
BA_ "GenMsgSendType" BO_ 2463978673 "Cyclic";
BA_ "VFrameFormat" BO_ 2463978673 "ExtendedCAN_FD";
BA_ "GenMsgCycleTime" BO_ 2589283657 500;
BA_ "GenMsgILSupport" BO_ 2589283657 "Yes";
BA_ "GenMsgSendType" BO_ 2589283657 "Cyclic";
BA_ "VFrameFormat" BO_ 2589283657 "ExtendedCAN_FD";
BA_ "GenMsgCycleTime" BO_ 184 500;
BA_ "GenMsgDelayTime" BO_ 184 20;
BA_ "GenMsgILSupport" BO_ 184 "Yes";
BA_ "GenMsgSendType" BO_ 184 "Cyclic";
BA_ "VFrameFormat" BO_ 184 "StandardCAN_FD";
BA_ "GenMsgCycleTime" BO_ 2527679712 1000;
BA_ "GenMsgILSupport" BO_ 2527679712 "Yes";
BA_ "GenMsgSendType" BO_ 2527679712 "Cyclic";
BA_ "VFrameFormat" BO_ 2527679712 "ExtendedCAN_FD";
BA_ "GenMsgCycleTime" BO_ 193 10;
BA_ "GenMsgILSupport" BO_ 193 "Yes";
BA_ "GenMsgPDUConstants" BO_ 193 "0xd7,0x12,0x85,0x7e,0x0b,0x34,0xfa,0x16,0x7a,0x25,0x2d,0x8f,0x04,0x8e,0x5d,0x35";
BA_ "GenMsgSendType" BO_ 193 "Cyclic";
BA_ "VFrameFormat" BO_ 193 "StandardCAN_FD";
BA_ "GenMsgCycleTime" BO_ 2463978674 100;
BA_ "GenMsgILSupport" BO_ 2463978674 "Yes";
BA_ "GenMsgSendType" BO_ 2463978674 "Cyclic";
BA_ "VFrameFormat" BO_ 2463978674 "ExtendedCAN_FD";
BA_ "GenMsgCycleTime" BO_ 2589283660 500;
BA_ "GenMsgILSupport" BO_ 2589283660 "Yes";
BA_ "GenMsgSendType" BO_ 2589283660 "Cyclic";
BA_ "VFrameFormat" BO_ 2589283660 "ExtendedCAN_FD";
BA_ "GenMsgCycleTime" BO_ 199 500;
BA_ "GenMsgDelayTime" BO_ 199 20;
BA_ "GenMsgILSupport" BO_ 199 "Yes";
BA_ "GenMsgSendType" BO_ 199 "Cyclic";
BA_ "VFrameFormat" BO_ 199 "StandardCAN_FD";
BA_ "GenMsgCycleTime" BO_ 2527679713 1000;
BA_ "GenMsgILSupport" BO_ 2527679713 "Yes";
BA_ "GenMsgSendType" BO_ 2527679713 "Cyclic";
BA_ "VFrameFormat" BO_ 2527679713 "ExtendedCAN_FD";
BA_ "GenMsgCycleTime" BO_ 2589283649 200;
BA_ "GenMsgILSupport" BO_ 2589283649 "Yes";
BA_ "GenMsgPDUConstants" BO_ 2589283649 "0x3e,0xb4,0x25,0xc1,0x31,0x1f,0xf1,0xd7,0xb1,0xbe,0xcc,0xe0,0x0f,0x46,0x51,0xb2";
BA_ "GenMsgSendType" BO_ 2589283649 "Cyclic";
BA_ "VFrameFormat" BO_ 2589283649 "ExtendedCAN_FD";
BA_ "GenMsgCycleTime" BO_ 608 50;
BA_ "GenMsgILSupport" BO_ 608 "Yes";
BA_ "GenMsgSendType" BO_ 608 "Cyclic";
BA_ "VFrameFormat" BO_ 608 "StandardCAN_FD";
BA_ "GenMsgCycleTime" BO_ 2589283751 500;
BA_ "GenMsgILSupport" BO_ 2589283751 "Yes";
BA_ "GenMsgSendType" BO_ 2589283751 "Cyclic";
BA_ "VFrameFormat" BO_ 2589283751 "ExtendedCAN_FD";
BA_ "GenMsgCycleTime" BO_ 2527679687 2000;
BA_ "GenMsgDelayTime" BO_ 2527679687 100;
BA_ "GenMsgILSupport" BO_ 2527679687 "Yes";
BA_ "GenMsgSendType" BO_ 2527679687 "Cyclic";
BA_ "VFrameFormat" BO_ 2527679687 "ExtendedCAN_FD";
BA_ "GenMsgCycleTime" BO_ 258 20;
BA_ "GenMsgILSupport" BO_ 258 "Yes";
BA_ "GenMsgPDUConstants" BO_ 258 "0xd7,0x12,0x85,0x7e,0x0b,0x34,0xfa,0x16,0x7a,0x25,0x2d,0x8f,0x04,0x8e,0x5d,0x35";
BA_ "GenMsgSendType" BO_ 258 "Cyclic";
BA_ "VFrameFormat" BO_ 258 "StandardCAN_FD";
BA_ "GenMsgCycleTime" BO_ 252 10;
BA_ "GenMsgILSupport" BO_ 252 "Yes";
BA_ "GenMsgPDUConstants" BO_ 252 "0x77,0x5c,0xa0,0x89,0x4b,0x7c,0xbb,0xd6,0x1f,0x6c,0x4f,0xf6,0x20,0x2b,0x43,0xdd";
BA_ "GenMsgSendType" BO_ 252 "Cyclic";
BA_ "VFrameFormat" BO_ 252 "StandardCAN_FD";
BA_ "GenMsgCycleTime" BO_ 2463978647 100;
BA_ "GenMsgILSupport" BO_ 2463978647 "Yes";
BA_ "GenMsgSendType" BO_ 2463978647 "Cyclic";
BA_ "VFrameFormat" BO_ 2463978647 "ExtendedCAN_FD";
BA_ "GenMsgCycleTime" BO_ 2527679683 2000;
BA_ "GenMsgDelayTime" BO_ 2527679683 100;
BA_ "GenMsgILSupport" BO_ 2527679683 "Yes";
BA_ "GenMsgSendType" BO_ 2527679683 "Cyclic";
BA_ "VFrameFormat" BO_ 2527679683 "ExtendedCAN_FD";
BA_ "GenMsgChkConstant" BO_ 278 172;
BA_ "GenMsgCycleTime" BO_ 278 20;
BA_ "GenMsgILSupport" BO_ 278 "Yes";
BA_ "GenMsgPDUConstants" BO_ 278 "0xac,0xac,0xac,0xac,0xac,0xac,0xac,0xac,0xac,0xac,0xac,0xac,0xac,0xac,0xac,0xac";
BA_ "GenMsgSendType" BO_ 278 "Cyclic";
BA_ "VFrameFormat" BO_ 278 "StandardCAN_FD";
BA_ "GenMsgCycleTime" BO_ 1629 1000;
BA_ "GenMsgDelayTime" BO_ 1629 200;
BA_ "GenMsgILSupport" BO_ 1629 "Yes";
BA_ "GenMsgPDUConstants" BO_ 1629 "0xac,0xb3,0xab,0xeb,0x7a,0xe1,0x3b,0xf7,0x73,0xba,0x7c,0x9e,0x06,0x5f,0x02,0xd9";
BA_ "GenMsgSendType" BO_ 1629 "Cyclic";
BA_ "VFrameFormat" BO_ 1629 "StandardCAN_FD";
BA_ "GenMsgCycleTime" BO_ 253 20;
BA_ "GenMsgILSupport" BO_ 253 "Yes";
BA_ "GenMsgPDUConstants" BO_ 253 "0xb4,0xef,0xf8,0x49,0x1e,0xe5,0xc2,0xc0,0x97,0x19,0x3c,0xc9,0xf1,0x98,0xd6,0x61";
BA_ "GenMsgSendType" BO_ 253 "Cyclic";
BA_ "VFrameFormat" BO_ 253 "StandardCAN_FD";
BA_ "GenMsgCycleTime" BO_ 795 50;
BA_ "GenMsgILSupport" BO_ 795 "Yes";
BA_ "GenMsgPDUConstants" BO_ 795 "0x67,0x8a,0xae,0x22,0x4d,0xd0,0x51,0x80,0x5c,0xb9,0xce,0x1e,0xdf,0x02,0x2d,0xd4";
BA_ "GenMsgSendType" BO_ 795 "Cyclic";
BA_ "VFrameFormat" BO_ 795 "StandardCAN_FD";
BA_ "GenMsgCycleTime" BO_ 2589283617 1000;
BA_ "GenMsgDelayTime" BO_ 2589283617 50;
BA_ "GenMsgILSupport" BO_ 2589283617 "Yes";
BA_ "GenMsgPDUConstants" BO_ 2589283617 "0xad,0xbd,0x5e,0x44,0x5b,0x90,0xb4,0x8d,0x9a,0x74,0xba,0xfa,0x2b,0x91,0xe2,0x89";
BA_ "GenMsgSendType" BO_ 2589283617 "Cyclic";
BA_ "VFrameFormat" BO_ 2589283617 "ExtendedCAN_FD";
BA_ "GenMsgCycleTime" BO_ 2527679668 500;
BA_ "GenMsgDelayTime" BO_ 2527679668 100;
BA_ "GenMsgILSupport" BO_ 2527679668 "Yes";
BA_ "GenMsgSendType" BO_ 2527679668 "Cyclic";
BA_ "VFrameFormat" BO_ 2527679668 "ExtendedCAN_FD";
BA_ "GenMsgCycleTime" BO_ 2527679740 200;
BA_ "GenMsgDelayTime" BO_ 2527679740 50;
BA_ "GenMsgILSupport" BO_ 2527679740 "Yes";
BA_ "GenMsgSendType" BO_ 2527679740 "Cyclic";
BA_ "VFrameFormat" BO_ 2527679740 "ExtendedCAN_FD";
BA_ "GenMsgCycleTime" BO_ 2589283684 1000;
BA_ "GenMsgDelayTime" BO_ 2589283684 200;
BA_ "GenMsgILSupport" BO_ 2589283684 "Yes";
BA_ "GenMsgSendType" BO_ 2589283684 "Cyclic";
BA_ "VFrameFormat" BO_ 2589283684 "ExtendedCAN_FD";
BA_ "MsgType" BO_ 2549875574 "ISO-TP";
BA_ "VFrameFormat" BO_ 2549875574 "ExtendedCAN_FD";
BA_ "MsgType" BO_ 2550006646 "ISO-TP";
BA_ "VFrameFormat" BO_ 2550006646 "ExtendedCAN_FD";
BA_ "GenMsgCycleTime" BO_ 987 100;
BA_ "GenMsgDelayTime" BO_ 987 10;
BA_ "GenMsgILSupport" BO_ 987 "Yes";
BA_ "GenMsgSendType" BO_ 987 "Cyclic";
BA_ "VFrameFormat" BO_ 987 "StandardCAN_FD";
BA_ "GenMsgCycleTime" BO_ 173 10;
BA_ "GenMsgILSupport" BO_ 173 "Yes";
BA_ "GenMsgPDUConstants" BO_ 173 "0x3f,0x69,0x39,0xdc,0x94,0xf9,0x14,0x64,0xd8,0x6a,0x34,0xce,0xa2,0x55,0xb5,0x2c";
BA_ "GenMsgSendType" BO_ 173 "Cyclic";
BA_ "VFrameFormat" BO_ 173 "StandardCAN_FD";
BA_ "GenMsgChkConstant" BO_ 324 227;
BA_ "GenMsgCycleTime" BO_ 324 20;
BA_ "GenMsgILSupport" BO_ 324 "Yes";
BA_ "GenMsgPDUConstants" BO_ 324 "0xe3,0xe3,0xe3,0xe3,0xe3,0xe3,0xe3,0xe3,0xe3,0xe3,0xe3,0xe3,0xe3,0xe3,0xe3,0xe3";
BA_ "GenMsgSendType" BO_ 324 "Cyclic";
BA_ "VFrameFormat" BO_ 324 "StandardCAN_FD";
BA_ "GenMsgCycleTime" BO_ 299 30;
BA_ "GenMsgILSupport" BO_ 299 "Yes";
BA_ "GenMsgPDUConstants" BO_ 299 "0x6a,0x38,0xb4,0x27,0x22,0xef,0xe1,0xbb,0xf8,0x80,0x84,0x49,0xc7,0x9e,0x1e,0x2b";
BA_ "GenMsgSendType" BO_ 299 "Cyclic";
BA_ "VFrameFormat" BO_ 299 "StandardCAN_FD";
BA_ "GenMsgCycleTime" BO_ 1452 100;
BA_ "GenMsgILSupport" BO_ 1452 "Yes";
BA_ "GenMsgSendType" BO_ 1452 "Cyclic";
BA_ "VFrameFormat" BO_ 1452 "StandardCAN_FD";
BA_ "GenMsgCycleTime" BO_ 1385 500;
BA_ "GenMsgDelayTime" BO_ 1385 50;
BA_ "GenMsgILSupport" BO_ 1385 "Yes";
BA_ "GenMsgSendType" BO_ 1385 "Cyclic";
BA_ "VFrameFormat" BO_ 1385 "StandardCAN_FD";
BA_ "GenMsgCycleTime" BO_ 1283 100;
BA_ "GenMsgDelayTime" BO_ 1283 10;
BA_ "GenMsgILSupport" BO_ 1283 "Yes";
BA_ "GenMsgPDUConstants" BO_ 1283 "0xed,0xd6,0x96,0x63,0xa5,0x12,0xd5,0x9a,0x1e,0x0d,0x24,0xcd,0x8c,0xa6,0x2f,0x41";
BA_ "GenMsgSendType" BO_ 1283 "Cyclic";
BA_ "VFrameFormat" BO_ 1283 "StandardCAN_FD";
BA_ "GenMsgCycleTime" BO_ 2463978813 100;
BA_ "GenMsgDelayTime" BO_ 2463978813 10;
BA_ "GenMsgILSupport" BO_ 2463978813 "Yes";
BA_ "GenMsgPDUConstants" BO_ 2463978813 "0x1d,0x82,0x7b,0x79,0xa5,0xee,0x3a,0xb9,0xb7,0xf9,0xe4,0x67,0x7f,0x97,0x11,0xad";
BA_ "GenMsgSendType" BO_ 2463978813 "Cyclic";
BA_ "VFrameFormat" BO_ 2463978813 "ExtendedCAN_FD";
BA_ "GenMsgCycleTime" BO_ 626 100;
BA_ "GenMsgDelayTime" BO_ 626 10;
BA_ "GenMsgILSupport" BO_ 626 "Yes";
BA_ "GenMsgSendType" BO_ 626 "Cyclic";
BA_ "VFrameFormat" BO_ 626 "StandardCAN_FD";
BA_ "GenMsgILSupport" BO_ 268 "Yes";
BA_ "VFrameFormat" BO_ 268 "StandardCAN_FD";
BA_ "GenMsgILSupport" BO_ 23 "Yes";
BA_ "VFrameFormat" BO_ 23 "StandardCAN_FD";
BA_ "GenMsgILSupport" BO_ 25 "Yes";
BA_ "VFrameFormat" BO_ 25 "StandardCAN_FD";
BA_ "GenMsgCycleTime" BO_ 2527679583 1000;
BA_ "GenMsgCycleTimeFast" BO_ 2527679583 100;
BA_ "GenMsgDelayTime" BO_ 2527679583 50;
BA_ "GenMsgILSupport" BO_ 2527679583 "Yes";
BA_ "GenMsgNrOfRepetition" BO_ 2527679583 5;
BA_ "GenMsgSendType" BO_ 2527679583 "Cyclic";
BA_ "VFrameFormat" BO_ 2527679583 "ExtendedCAN_FD";
BA_ "DiagRequest" BO_ 1813 "Yes";
BA_ "MsgType" BO_ 1813 "ISO-TP";
BA_ "VFrameFormat" BO_ 1813 "StandardCAN_FD";
BA_ "DiagResponse" BO_ 1919 "Yes";
BA_ "MsgType" BO_ 1919 "ISO-TP";
BA_ "VFrameFormat" BO_ 1919 "StandardCAN_FD";
BA_ "DiagState" BO_ 1792 "Yes";
BA_ "MsgType" BO_ 1792 "ISO-TP";
BA_ "VFrameFormat" BO_ 1792 "StandardCAN_FD";
BA_ "DiagRequest" BO_ 2621440021 "Yes";
BA_ "MsgType" BO_ 2621440021 "ISO-TP";
BA_ "VFrameFormat" BO_ 2621440021 "ExtendedCAN_FD";
BA_ "DiagResponse" BO_ 2621571093 "Yes";
BA_ "MsgType" BO_ 2621571093 "ISO-TP";
BA_ "VFrameFormat" BO_ 2621571093 "ExtendedCAN_FD";
BA_ "DiagRequest" BO_ 2549874812 "Yes";
BA_ "MsgType" BO_ 2549874812 "ISO-TP";
BA_ "VFrameFormat" BO_ 2549874812 "ExtendedCAN_FD";
BA_ "DiagRequest" BO_ 2621440124 "Yes";
BA_ "MsgType" BO_ 2621440124 "ISO-TP";
BA_ "VFrameFormat" BO_ 2621440124 "ExtendedCAN_FD";
BA_ "DiagResponse" BO_ 2550005884 "Yes";
BA_ "MsgType" BO_ 2550005884 "ISO-TP";
BA_ "VFrameFormat" BO_ 2550005884 "ExtendedCAN_FD";
BA_ "DiagResponse" BO_ 2621571196 "Yes";
BA_ "MsgType" BO_ 2621571196 "ISO-TP";
BA_ "VFrameFormat" BO_ 2621571196 "ExtendedCAN_FD";
BA_ "DiagRequest" BO_ 2549874872 "Yes";
BA_ "MsgType" BO_ 2549874872 "ISO-TP";
BA_ "VFrameFormat" BO_ 2549874872 "ExtendedCAN_FD";
BA_ "DiagRequest" BO_ 2621440184 "Yes";
BA_ "MsgType" BO_ 2621440184 "ISO-TP";
BA_ "VFrameFormat" BO_ 2621440184 "ExtendedCAN_FD";
BA_ "DiagResponse" BO_ 2550005944 "Yes";
BA_ "MsgType" BO_ 2550005944 "ISO-TP";
BA_ "VFrameFormat" BO_ 2550005944 "ExtendedCAN_FD";
BA_ "DiagResponse" BO_ 2621571256 "Yes";
BA_ "MsgType" BO_ 2621571256 "ISO-TP";
BA_ "VFrameFormat" BO_ 2621571256 "ExtendedCAN_FD";
BA_ "DiagState" BO_ 2621505536 "Yes";
BA_ "MsgType" BO_ 2621505536 "ISO-TP";
BA_ "VFrameFormat" BO_ 2621505536 "ExtendedCAN_FD";
BA_ "DiagRequest" BO_ 2549874806 "Yes";
BA_ "MsgType" BO_ 2549874806 "ISO-TP";
BA_ "VFrameFormat" BO_ 2549874806 "ExtendedCAN_FD";
BA_ "DiagRequest" BO_ 2621440118 "Yes";
BA_ "MsgType" BO_ 2621440118 "ISO-TP";
BA_ "VFrameFormat" BO_ 2621440118 "ExtendedCAN_FD";
BA_ "DiagResponse" BO_ 2550005878 "Yes";
BA_ "MsgType" BO_ 2550005878 "ISO-TP";
BA_ "VFrameFormat" BO_ 2550005878 "ExtendedCAN_FD";
BA_ "DiagResponse" BO_ 2621571190 "Yes";
BA_ "MsgType" BO_ 2621571190 "ISO-TP";
BA_ "VFrameFormat" BO_ 2621571190 "ExtendedCAN_FD";
BA_ "GenMsgCycleTime" BO_ 2527679684 2000;
BA_ "GenMsgDelayTime" BO_ 2527679684 100;
BA_ "GenMsgILSupport" BO_ 2527679684 "Yes";
BA_ "GenMsgSendType" BO_ 2527679684 "Cyclic";
BA_ "VFrameFormat" BO_ 2527679684 "ExtendedCAN_FD";
BA_ "GenMsgChkConstant" BO_ 960 195;
BA_ "GenMsgCycleTime" BO_ 960 100;
BA_ "GenMsgDelayTime" BO_ 960 10;
BA_ "GenMsgILSupport" BO_ 960 "Yes";
BA_ "GenMsgPDUConstants" BO_ 960 "0xc3,0xc3,0xc3,0xc3,0xc3,0xc3,0xc3,0xc3,0xc3,0xc3,0xc3,0xc3,0xc3,0xc3,0xc3,0xc3";
BA_ "GenMsgSendType" BO_ 960 "Cyclic";
BA_ "VFrameFormat" BO_ 960 "StandardCAN_FD";
BA_ "GenMsgCycleTime" BO_ 2463978753 1000;
BA_ "GenMsgCycleTimeFast" BO_ 2463978753 100;
BA_ "GenMsgDelayTime" BO_ 2463978753 100;
BA_ "GenMsgILSupport" BO_ 2463978753 "Yes";
BA_ "GenMsgNrOfRepetition" BO_ 2463978753 5;
BA_ "GenMsgSendType" BO_ 2463978753 "Cyclic";
BA_ "VFrameFormat" BO_ 2463978753 "ExtendedCAN_FD";
BA_ "GenMsgCycleTime" BO_ 1420 1000;
BA_ "GenMsgCycleTimeFast" BO_ 1420 20;
BA_ "GenMsgDelayTime" BO_ 1420 10;
BA_ "GenMsgILSupport" BO_ 1420 "Yes";
BA_ "GenMsgNrOfRepetition" BO_ 1420 5;
BA_ "GenMsgPDUConstants" BO_ 1420 "0x9b,0xb5,0x9d,0x06,0x01,0xe7,0x8f,0xc1,0xd0,0x10,0x47,0xe9,0xd3,0xca,0x05,0xf0";
BA_ "GenMsgSendType" BO_ 1420 "Cyclic";
BA_ "VFrameFormat" BO_ 1420 "StandardCAN_FD";
